VERSION ""

NS_ :

BS_:

BU_: GPSReceiver TractorECU Implement

BO_ 2628452094 CFS: 9 Vector__XXX
 SG_ VI_VolumeName m64 : 56|16@1+ (1,0) [0|65535] "" Vector__XXX
 SG_ VI_Flag_OverwriteExisting m64 : 48|1@1+ (1,0) [0|1] "" Vector__XXX
 SG_ MF_DestinationPathNameLength m48 : 40|16@1+ (1,0) [0|65535] "" Vector__XXX
 SG_ RF_ReportHiddenFiles m34 : 40|8@1+ (1,0) [0|255] "" Vector__XXX
 SG_ SF_Offset m33 : 32|32@1- (1,0) [-2147483648|2147483647] "" Vector__XXX
 SG_ RF_Count m34 : 24|16@1+ (1,0) [0|65535] "" Vector__XXX
 SG_ SF_PositionMode m33 : 24|8@1+ (1,0) [0|255] "" Vector__XXX
 SG_ OF_PathName m32 : 24|16@1+ (1,0) [0|65535] "" Vector__XXX
 SG_ MF_SourcePathNameLength m48 : 24|16@1+ (1,0) [0|65535] "" Vector__XXX
 SG_ WF_Count m35 : 24|16@1+ (1,0) [0|65535] "" Vector__XXX
 SG_ DF_PathName m49 : 24|16@1+ (1,0) [0|65535] "" Vector__XXX
 SG_ SA_PathName m51 : 24|16@1+ (1,0) [0|65535] "" Vector__XXX
 SG_ VI_Space m64 : 16|32@1+ (1,0) [0|4294967295] "" Vector__XXX
 SG_ OF_FlagExclusiveAccess m32 : 20|1@1+ (1,0) [0|1] "" Vector__XXX
 SG_ OF_FlagAppend m32 : 19|1@1+ (1,0) [0|1] "" Vector__XXX
 SG_ SA_ATTR_Hidden m51 : 18|2@1+ (1,0) [0|3] "" Vector__XXX
 SG_ OF_FlagCreateNew m32 : 18|1@1+ (1,0) [0|1] "" Vector__XXX
 SG_ MF_MoveModeRecursive m48 : 18|1@1+ (1,0) [0|1] "" Vector__XXX
 SG_ DF_DeleteModeRecursive m49 : 18|1@1+ (1,0) [0|1] "" Vector__XXX
 SG_ MF_MoveModeForce m48 : 17|1@1+ (1,0) [0|1] "" Vector__XXX
 SG_ DF_DeleteModeForce m49 : 17|1@1+ (1,0) [0|1] "" Vector__XXX
 SG_ VI_Flag_UsingSpaceSpecified m64 : 49|1@1+ (1,0) [0|1] "" Vector__XXX
 SG_ SA_ATTR_ReadOnly m51 : 16|2@1+ (1,0) [0|3] "" Vector__XXX
 SG_ CF_Handle m36 : 16|8@1+ (1,0) [0|255] "" Vector__XXX
 SG_ WF_Handle m35 : 16|8@1+ (1,0) [0|255] "" Vector__XXX
 SG_ RF_Handle m34 : 16|8@1+ (1,0) [0|255] "" Vector__XXX
 SG_ SF_Handle m33 : 16|8@1+ (1,0) [0|255] "" Vector__XXX
 SG_ OF_FlagReadWrite m32 : 16|2@1+ (1,0) [0|3] "" Vector__XXX
 SG_ CCD_PathName m17 : 16|16@1+ (1,0) [0|65535] "" Vector__XXX
 SG_ MF_MoveModeCopy m48 : 16|1@1+ (1,0) [0|1] "" Vector__XXX
 SG_ DF_DeleteMode m49 : 16|1@1+ (1,0) [0|1] "" Vector__XXX
 SG_ GA_PathName m50 : 16|16@1+ (1,0) [0|65535] "" Vector__XXX
 SG_ FDT_PathName m52 : 16|16@1+ (1,0) [0|65535] "" Vector__XXX
 SG_ VS_VolumeName m2 : 16|16@1+ (1,0) [0|0] "" Vector__XXX
 SG_ VS_RequestVolumeToPrepareForRemo m2 : 9|1@1- (1,0) [0|1] "" Vector__XXX
 SG_ CCD_TAN m17 : 8|8@1+ (1,0) [0|255] "" Vector__XXX
 SG_ GCD_TAN m16 : 8|8@1+ (1,0) [0|255] "" Vector__XXX
 SG_ FDT_TAN m52 : 8|8@1+ (1,0) [0|255] "" Vector__XXX
 SG_ SA_TAN m51 : 8|8@1+ (1,0) [0|255] "" Vector__XXX
 SG_ GA_TAN m50 : 8|8@1+ (1,0) [0|255] "" Vector__XXX
 SG_ RF_TAN m34 : 8|8@1+ (1,0) [0|255] "" Vector__XXX
 SG_ CF_TAN m36 : 8|8@1+ (1,0) [0|255] "" Vector__XXX
 SG_ WF_TAN m35 : 8|8@1+ (1,0) [0|255] "" Vector__XXX
 SG_ SF_TAN m33 : 8|8@1+ (1,0) [0|255] "" Vector__XXX
 SG_ OF_TAN m32 : 8|8@1+ (1,0) [0|255] "" Vector__XXX
 SG_ MF_TAN m48 : 8|8@1+ (1,0) [0|255] "" Vector__XXX
 SG_ DF_TAN m49 : 8|8@1+ (1,0) [0|255] "" Vector__XXX
 SG_ VI_TAN m64 : 8|8@1+ (1,0) [0|255] "" Vector__XXX
 SG_ VS_ReportVolumeUsedByClient m2 : 8|1@1+ (1,0) [0|1] "" Vector__XXX
 SG_ CM_VersionNumber m0 : 8|8@1+ (1,0) [0|255] "" Vector__XXX
 SG_ FSClientCommand M : 0|8@1+ (1,0) [0|255] "" Vector__XXX

BO_ 2628517630 FSC: 35 Vector__XXX
 SG_ OF_ATTR_VolumeSupportsHidden m32 : 34|1@1+ (1,0) [0|1] "" Vector__XXX
 SG_ GCD_PathName m16 : 88|16@1+ (1,0) [0|65535] "" Vector__XXX
 SG_ GCD_FreeSpace m16 : 56|32@1+ (512,0) [0|4294966744] "Bytes" Vector__XXX
 SG_ FDT_TimeHour m52 : 51|5@1+ (1,0) [0|23] "Hour" Vector__XXX
 SG_ FDT_TimeMinutes m52 : 45|6@1+ (1,0) [0|59] "Minutes" Vector__XXX
 SG_ FDT_TimeSeconds m52 : 40|5@1+ (2,0) [0|58] "Seconds" Vector__XXX
 SG_ OF_ATTR_VolumeIsCaseSensitive m32 : 39|1@1+ (1,0) [0|1] "" Vector__XXX
 SG_ OF_ATTR_VolumeIsRemovable m32 : 38|1@1+ (1,0) [0|1] "" Vector__XXX
 SG_ OF_ATTR_SupportsLongFilenames m32 : 37|1@1+ (1,0) [0|1] "" Vector__XXX
 SG_ OF_ATTR_IsDirectory m32 : 36|1@1+ (1,0) [0|1] "" Vector__XXX
 SG_ OF_ATTR_IsVolume m32 : 35|1@1+ (1,0) [0|1] "" Vector__XXX
 SG_ FDT_DateYear m52 : 33|7@1+ (1,1980) [1980|2107] "Year" Vector__XXX
 SG_ OF_ATTR_Hidden m32 : 33|1@1+ (1,0) [0|1] "" Vector__XXX
 SG_ SF_Position m33 : 32|32@1+ (1,0) [0|4294967295] "" Vector__XXX
 SG_ OF_ATTR_ReadOnly m32 : 32|1@1+ (1,0) [0|1] "" Vector__XXX
 SG_ GA_Size m50 : 32|32@1+ (1,0) [0|4294967295] "" Vector__XXX
 SG_ VS_VolumeName m2 : 32|16@1+ (1,0) [0|65535] "" Vector__XXX
 SG_ VI_VolumeIsCaseSensitive m64 : 31|1@1+ (1,0) [0|1] "" Vector__XXX
 SG_ GA_ATTR_VolumeIsCaseSensitive m50 : 31|1@1+ (1,0) [0|1] "" Vector__XXX
 SG_ VI_ATTR_VolumeRemovable m64 : 30|1@1+ (1,0) [0|1] "" Vector__XXX
 SG_ GA_ATTR_VolumeIsRemovable m50 : 30|1@1+ (1,0) [0|1] "" Vector__XXX
 SG_ VI_ATTR_SupportsLongFilenames m64 : 29|1@1+ (1,0) [0|1] "" Vector__XXX
 SG_ FDT_DateMonth m52 : 29|4@1+ (1,0) [0|12] "Month" Vector__XXX
 SG_ GA_ATTR_SupportsLongFilenames m50 : 29|1@1+ (1,0) [0|1] "" Vector__XXX
 SG_ GA_ATTR_IsDirectory m50 : 28|1@1+ (1,0) [0|1] "" Vector__XXX
 SG_ VI_ATTR_IsDirectory m64 : 28|1@1+ (1,0) [0|1] "" Vector__XXX
 SG_ VI_ATTR_IsVolume m64 : 27|1@1+ (1,0) [0|1] "" Vector__XXX
 SG_ GA_ATTR_IsVolume m50 : 27|1@1+ (1,0) [0|1] "" Vector__XXX
 SG_ VI_ATTR_VolumeSupportsHidden m64 : 26|1@1+ (1,0) [0|1] "" Vector__XXX
 SG_ GA_ATTR_VolumeSupportsHidden m50 : 26|1@1+ (1,0) [0|1] "" Vector__XXX
 SG_ VI_ATTR_Hidden m64 : 25|1@1+ (1,0) [0|1] "" Vector__XXX
 SG_ GA_ATTR_Hidden m50 : 25|1@1+ (1,0) [0|1] "" Vector__XXX
 SG_ VI_ATTR_ReadOnly m64 : 24|1@1+ (1,0) [0|1] "" Vector__XXX
 SG_ FDT_DateDay m52 : 24|5@1+ (1,0) [0|31] "Day" Vector__XXX
 SG_ GA_ATTR_ReadOnly m50 : 24|1@1+ (1,0) [0|1] "" Vector__XXX
 SG_ OF_Handle m32 : 24|8@1+ (1,0) [0|255] "" Vector__XXX
 SG_ GCD_TotalSpace m16 : 24|32@1+ (512,0) [0|4294966744] "Bytes" Vector__XXX
 SG_ RF_Count m34 : 24|16@1+ (1,0) [0|65535] "Bytes" Vector__XXX
 SG_ GSP_SupportMultipleVolumes m1 : 24|1@1+ (1,0) [0|255] "" Vector__XXX
 SG_ WF_Count m35 : 24|16@1+ (1,0) [0|65535] "" Vector__XXX
 SG_ VS_ErrorCode m2 : 24|8@1+ (1,0) [0|255] "" Vector__XXX
 SG_ FDT_ErrorCode m52 : 16|8@1+ (1,0) [0|255] "" Vector__XXX
 SG_ RF_ErrorCode m34 : 16|8@1+ (1,0) [0|255] "" Vector__XXX
 SG_ SF_ErrorCode m33 : 16|8@1+ (1,0) [0|255] "" Vector__XXX
 SG_ FSNumberOfOpenFiles m0 : 16|8@1- (1,0) [0|255] "" Vector__XXX
 SG_ OF_ErrorCode m32 : 16|8@1+ (1,0) [0|255] "" Vector__XXX
 SG_ WF_ErrorCode m35 : 16|8@1+ (1,0) [0|255] "" Vector__XXX
 SG_ CF_ErrorCode m36 : 16|8@1+ (1,0) [0|255] "" Vector__XXX
 SG_ MF_ErrorCode m48 : 16|8@1+ (1,0) [0|255] "" Vector__XXX
 SG_ GA_ErrorCode m50 : 16|8@1+ (1,0) [0|255] "" Vector__XXX
 SG_ SA_ErrorCode m51 : 16|8@1+ (1,0) [0|255] "" Vector__XXX
 SG_ GCD_ErrorCode m16 : 16|8@1+ (1,0) [0|255] "" Vector__XXX
 SG_ CCD_ErrorCode m17 : 16|8@1+ (1,0) [0|255] "" Vector__XXX
 SG_ GSP_MaxNrSimultaneousFilesOpen m1 : 16|8@1+ (1,0) [0|255] "" Vector__XXX
 SG_ DF_ErrorCode m49 : 16|8@1+ (1,0) [0|255] "" Vector__XXX
 SG_ VI_ErrorCode m64 : 16|8@1+ (1,0) [0|255] "" Vector__XXX
 SG_ VS_MaxTimeBeforeVolRemoval m2 : 16|8@1+ (1,0) [0|250] "min/bit" Vector__XXX
 SG_ FSBusyWriting m0 : 9|1@1+ (1,0) [0|1] "" Vector__XXX
 SG_ FSBusyReading m0 : 8|1@1+ (1,0) [0|1] "" Vector__XXX
 SG_ OF_TAN m32 : 8|8@1+ (1,0) [0|255] "" Vector__XXX
 SG_ SF_TAN m33 : 8|8@1+ (1,0) [0|255] "" Vector__XXX
 SG_ RF_TAN m34 : 8|8@1+ (1,0) [0|255] "" Vector__XXX
 SG_ WF_TAN m35 : 8|8@1+ (1,0) [0|255] "" Vector__XXX
 SG_ CF_TAN m36 : 8|8@1+ (1,0) [0|255] "" Vector__XXX
 SG_ MF_TAN m48 : 8|8@1+ (1,0) [0|255] "" Vector__XXX
 SG_ GA_TAN m50 : 8|8@1+ (1,0) [0|255] "" Vector__XXX
 SG_ SA_TAN m51 : 8|8@1+ (1,0) [0|255] "" Vector__XXX
 SG_ FDT_TAN m52 : 8|8@1+ (1,0) [0|255] "" Vector__XXX
 SG_ GCD_TAN m16 : 8|8@1+ (1,0) [0|255] "" Vector__XXX
 SG_ CCD_TAN m17 : 8|8@1+ (1,0) [0|255] "" Vector__XXX
 SG_ GSP_VersionNumber m1 : 8|8@1+ (1,0) [0|255] "" Vector__XXX
 SG_ DF_TAN m49 : 8|8@1+ (1,0) [0|255] "" Vector__XXX
 SG_ VI_TAN m64 : 8|8@1+ (1,0) [0|255] "" Vector__XXX
 SG_ VS_VolumeStatus m2 : 8|8@1+ (1,0) [0|3] "" Vector__XXX
 SG_ FSServerCommand M : 0|8@1+ (1,0) [0|255] "" Vector__XXX

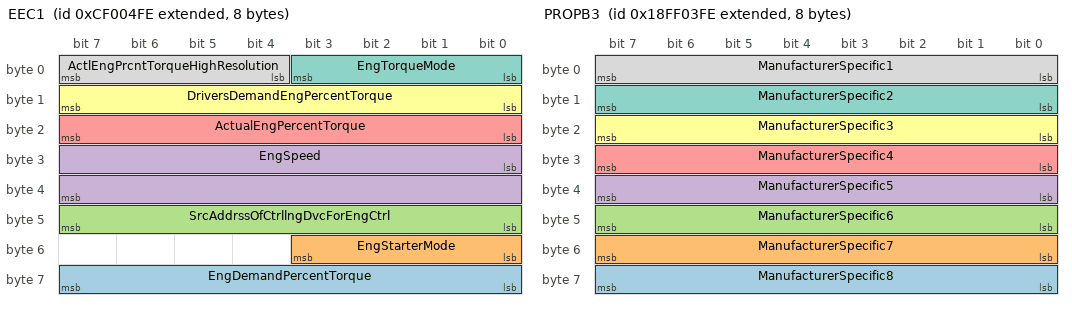
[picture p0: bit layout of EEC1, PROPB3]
BO_ 2364540158 EEC1: 8 Vector__XXX
 SG_ EngDemandPercentTorque : 56|8@1+ (1,-125) [-125|125] "%" Vector__XXX
 SG_ EngStarterMode : 48|4@1+ (1,0) [0|15] "" Vector__XXX
 SG_ SrcAddrssOfCtrllngDvcForEngCtrl : 40|8@1+ (1,0) [0|255] "" Vector__XXX
 SG_ EngSpeed : 24|16@1+ (0.125,0) [0|8031.875] "rpm" Vector__XXX
 SG_ ActualEngPercentTorque : 16|8@1+ (1,-125) [-125|125] "%" Vector__XXX
 SG_ DriversDemandEngPercentTorque : 8|8@1+ (1,-125) [-125|125] "%" Vector__XXX
 SG_ EngTorqueMode : 0|4@1+ (1,0) [0|15] "" Vector__XXX
 SG_ ActlEngPrcntTorqueHighResolution : 4|4@1+ (0.125,0) [0|0.875] "%" Vector__XXX

BO_ 2563243774 ETP_DT: 8 Vector__XXX
 SG_ Byte7 : 56|8@1+ (1,0) [0|255] "" Vector__XXX
 SG_ Byte6 : 48|8@1+ (1,0) [0|255] "" Vector__XXX
 SG_ Byte5 : 40|8@1+ (1,0) [0|255] "" Vector__XXX
 SG_ Byte4 : 32|8@1+ (1,0) [0|255] "" Vector__XXX
 SG_ Byte3 : 24|8@1+ (1,0) [0|255] "" Vector__XXX
 SG_ Byte2 : 16|8@1+ (1,0) [0|255] "" Vector__XXX
 SG_ Byte1 : 8|8@1+ (1,0) [0|255] "" Vector__XXX
 SG_ SequenceNumber : 0|8@1+ (1,0) [1|255] "" Vector__XXX

BO_ 2563309310 ETP_CM: 8 Vector__XXX
 SG_ PGNumber : 40|24@1+ (1,0) [0|16777200] "" Vector__XXX
 SG_ DataPacketOffset m22 : 16|24@1+ (1,0) [0|16777215] "" Vector__XXX
 SG_ NextPacketNumberToSend m21 : 16|24@1+ (1,0) [1|16777215] "" Vector__XXX
 SG_ NumberOfBytesTransfered m23 : 8|32@1+ (1,0) [1786|117440505] "" Vector__XXX
 SG_ NumberOfPacketsOffset m22 : 8|8@1+ (1,0) [1|255] "" Vector__XXX
 SG_ NumberOfPacketsToSend m21 : 8|8@1+ (1,0) [1|255] "" Vector__XXX
 SG_ NumberOfBytesToTransfer m20 : 8|32@1+ (1,0) [1786|117440505] "" Vector__XXX
 SG_ ControlByte M : 0|8@1+ (1,0) [0|255] "" Vector__XXX
 SG_ ConnectionAbortReason m255 : 8|8@1+ (1,0) [0|255] "" Vector__XXX

BO_ 2314732030 GNSSPositionRapidUpdate: 8 Vector__XXX
 SG_ Longitude : 32|32@1- (1E-007,0) [-180|180] "deg" Vector__XXX
 SG_ Latitude : 0|32@1- (1E-007,0) [-90|90] "deg" Vector__XXX

BO_ 2583168510 GNSSPositionData: 47 Vector__XXX
 SG_ AgeOfDGNSSCorrections1 : 360|16@1+ (0.01,0) [0|655.32] "sec" Vector__XXX
 SG_ ReferenceStationID1 : 348|12@1+ (1,0) [0|4095] "" Vector__XXX
 SG_ RefrenceStationType1 : 344|4@1+ (1,0) [0|15] "" Vector__XXX
 SG_ NumberOfReferenceStations : 336|8@1+ (1,0) [0|252] "" Vector__XXX
 SG_ GeoidalSeparation : 304|32@1- (0.01,0) [-21470000|21470000] "m" Vector__XXX
 SG_ PDOP : 288|16@1- (0.01,0) [-327.64|327.64] "" Vector__XXX
 SG_ HDOP : 272|16@1- (0.01,0) [-327.64|327.64] "" Vector__XXX
 SG_ NumberOfSVs : 264|8@1+ (1,0) [0|252] "" Vector__XXX
 SG_ GNSSIntegrity : 256|2@1+ (1,0) [0|3] "" Vector__XXX
 SG_ GNSSMethod : 252|4@1+ (1,0) [0|15] "" Vector__XXX
 SG_ TypeOfSystem : 248|4@1+ (1,0) [0|4] "" Vector__XXX
 SG_ Altitude : 184|64@1- (1E-006,0) [-9223372036854.78|9223372036854.78] "m" Vector__XXX
 SG_ Longitude : 120|64@1- (1E-016,0) [-180|180] "deg" Vector__XXX
 SG_ Latitude : 56|64@1- (1E-016,0) [-90|90] "deg" Vector__XXX
 SG_ PositionTime : 24|32@1+ (0.0001,0) [0|86401] "s" Vector__XXX
 SG_ PositionDate : 8|16@1+ (1,0) [0|65532] "day" Vector__XXX
 SG_ SequenceID : 0|8@1+ (1,0) [0|255] "" Vector__XXX

BO_ 2583299838 GNSSPseudoRangeNoiseStatistic: 15 Vector__XXX
 SG_ STDofAltError : 104|16@1+ (0.01,0) [0|655.32] "m" Vector__XXX
 SG_ STDofLonError : 88|16@1+ (0.01,0) [0|655.32] "m" Vector__XXX
 SG_ STDofLatError : 72|16@1+ (0.01,0) [0|655.32] "m" Vector__XXX
 SG_ OrientationOfMinorAxis : 56|16@1+ (0.0001,0) [0|6.2832] "rad" Vector__XXX
 SG_ STDofMinorAxis : 40|16@1+ (0.01,0) [0|655.32] "m" Vector__XXX
 SG_ STDofMajorAxis : 24|16@1+ (0.01,0) [0|655.32] "m" Vector__XXX
 SG_ RMSofPositionUncertainty : 8|16@1+ (0.01,0) [0|655.32] "m" Vector__XXX
 SG_ SequenceID : 0|8@1+ (1,0) [0|255] "" Vector__XXX

BO_ 2566849534 PROPB3: 8 Vector__XXX
 SG_ ManufacturerSpecific8 : 56|8@1+ (1,0) [0|255] "" Vector__XXX
 SG_ ManufacturerSpecific7 : 48|8@1+ (1,0) [0|255] "" Vector__XXX
 SG_ ManufacturerSpecific6 : 40|8@1+ (1,0) [0|255] "" Vector__XXX
 SG_ ManufacturerSpecific5 : 32|8@1+ (1,0) [0|255] "" Vector__XXX
 SG_ ManufacturerSpecific4 : 24|8@1+ (1,0) [0|255] "" Vector__XXX
 SG_ ManufacturerSpecific3 : 16|8@1+ (1,0) [0|255] "" Vector__XXX
 SG_ ManufacturerSpecific2 : 8|8@1+ (1,0) [0|255] "" Vector__XXX
 SG_ ManufacturerSpecific1 : 0|8@1+ (1,0) [0|255] "" Vector__XXX

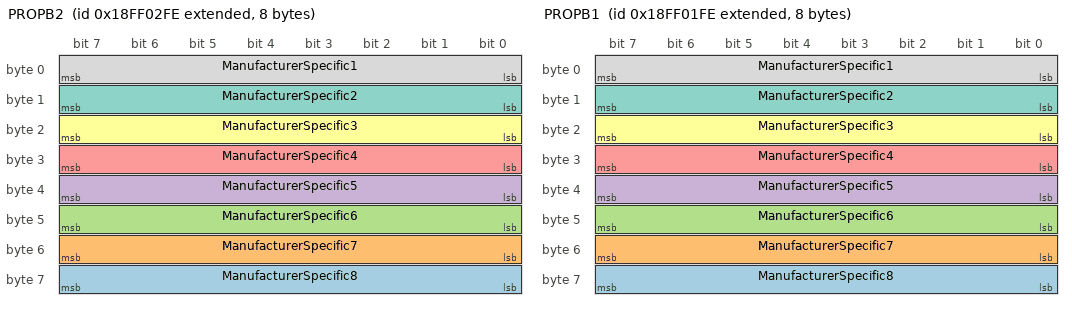
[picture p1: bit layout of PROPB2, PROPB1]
BO_ 2566849278 PROPB2: 8 Vector__XXX
 SG_ ManufacturerSpecific8 : 56|8@1+ (1,0) [0|255] "" Vector__XXX
 SG_ ManufacturerSpecific7 : 48|8@1+ (1,0) [0|255] "" Vector__XXX
 SG_ ManufacturerSpecific6 : 40|8@1+ (1,0) [0|255] "" Vector__XXX
 SG_ ManufacturerSpecific5 : 32|8@1+ (1,0) [0|255] "" Vector__XXX
 SG_ ManufacturerSpecific4 : 24|8@1+ (1,0) [0|255] "" Vector__XXX
 SG_ ManufacturerSpecific3 : 16|8@1+ (1,0) [0|255] "" Vector__XXX
 SG_ ManufacturerSpecific2 : 8|8@1+ (1,0) [0|255] "" Vector__XXX
 SG_ ManufacturerSpecific1 : 0|8@1+ (1,0) [0|255] "" Vector__XXX

BO_ 2566849022 PROPB1: 8 Vector__XXX
 SG_ ManufacturerSpecific8 : 56|8@1+ (1,0) [0|255] "" Vector__XXX
 SG_ ManufacturerSpecific7 : 48|8@1+ (1,0) [0|255] "" Vector__XXX
 SG_ ManufacturerSpecific6 : 40|8@1+ (1,0) [0|255] "" Vector__XXX
 SG_ ManufacturerSpecific5 : 32|8@1+ (1,0) [0|255] "" Vector__XXX
 SG_ ManufacturerSpecific4 : 24|8@1+ (1,0) [0|255] "" Vector__XXX
 SG_ ManufacturerSpecific3 : 16|8@1+ (1,0) [0|255] "" Vector__XXX
 SG_ ManufacturerSpecific2 : 8|8@1+ (1,0) [0|255] "" Vector__XXX
 SG_ ManufacturerSpecific1 : 0|8@1+ (1,0) [0|255] "" Vector__XXX

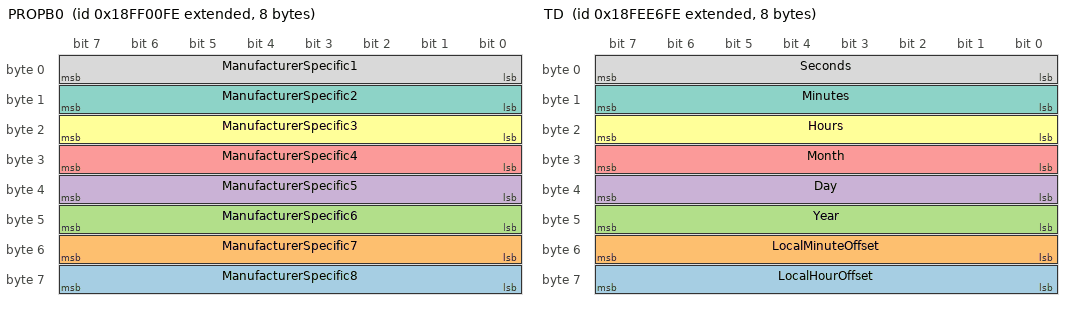
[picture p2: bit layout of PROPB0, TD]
BO_ 2566848766 PROPB0: 8 Vector__XXX
 SG_ ManufacturerSpecific8 : 56|8@1+ (1,0) [0|255] "" Vector__XXX
 SG_ ManufacturerSpecific7 : 48|8@1+ (1,0) [0|255] "" Vector__XXX
 SG_ ManufacturerSpecific6 : 40|8@1+ (1,0) [0|255] "" Vector__XXX
 SG_ ManufacturerSpecific5 : 32|8@1+ (1,0) [0|255] "" Vector__XXX
 SG_ ManufacturerSpecific4 : 24|8@1+ (1,0) [0|255] "" Vector__XXX
 SG_ ManufacturerSpecific3 : 16|8@1+ (1,0) [0|255] "" Vector__XXX
 SG_ ManufacturerSpecific2 : 8|8@1+ (1,0) [0|255] "" Vector__XXX
 SG_ ManufacturerSpecific1 : 0|8@1+ (1,0) [0|255] "" Vector__XXX

BO_ 2566842110 TD: 8 Vector__XXX
 SG_ LocalHourOffset : 56|8@1+ (1,-125) [-125|125] "hr" Vector__XXX
 SG_ LocalMinuteOffset : 48|8@1+ (1,-125) [-125|125] "mins" Vector__XXX
 SG_ Year : 40|8@1+ (1,1985) [1985|2235] "years" Vector__XXX
 SG_ Day : 32|8@1+ (0.25,0) [0|62.5] "days" Vector__XXX
 SG_ Month : 24|8@1+ (1,0) [0|250] "months" Vector__XXX
 SG_ Hours : 16|8@1+ (1,0) [0|250] "hr" Vector__XXX
 SG_ Minutes : 8|8@1+ (1,0) [0|250] "mins" Vector__XXX
 SG_ Seconds : 0|8@1+ (0.25,0) [0|62.5] "s" Vector__XXX

BO_ 2365475326 GBSD: 8 Vector__XXX
 SG_ GroundBasedMachineDirection : 56|2@1+ (1,0) [0|3] "" Vector__XXX
 SG_ GroundBasedMachineDistance : 16|32@1+ (0.001,0) [0|4211080] "m" Vector__XXX
 SG_ GroundBasedMachineSpeed : 0|16@1+ (0.001,0) [0|64.255] "m/s" Vector__XXX

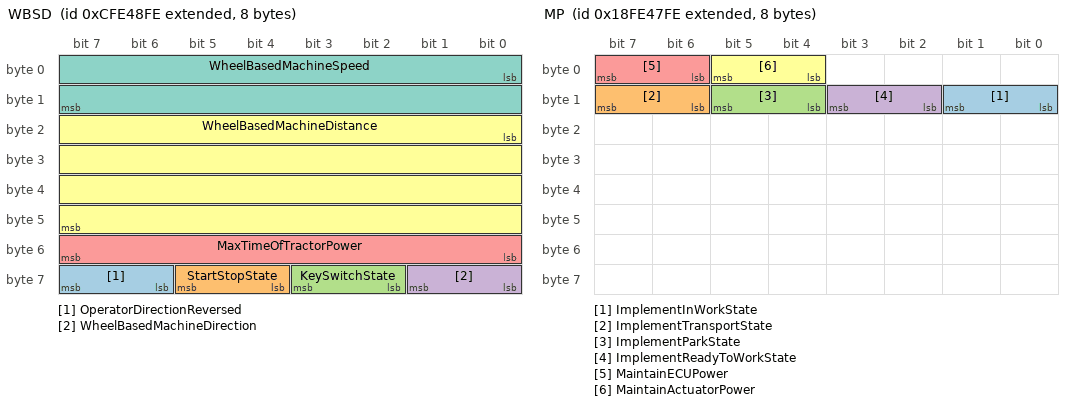
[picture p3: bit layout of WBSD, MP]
BO_ 2365475070 WBSD: 8 Vector__XXX
 SG_ OperatorDirectionReversed : 62|2@1+ (1,0) [0|3] "" Vector__XXX
 SG_ StartStopState : 60|2@1+ (1,0) [0|4] "" Vector__XXX
 SG_ KeySwitchState : 58|2@1+ (1,0) [0|3] "" Vector__XXX
 SG_ WheelBasedMachineDirection : 56|2@1+ (1,0) [0|3] "" Vector__XXX
 SG_ MaxTimeOfTractorPower : 48|8@1+ (1,0) [0|250] "min" Vector__XXX
 SG_ WheelBasedMachineDistance : 16|32@1+ (0.001,0) [0|4211081.215] "m" Vector__XXX
 SG_ WheelBasedMachineSpeed : 0|16@1+ (0.001,0) [0|64.255] "m/s" Vector__XXX

BO_ 2566801406 MP: 8 Vector__XXX
 SG_ ImplementInWorkState : 8|2@1+ (1,0) [0|0] "" Vector__XXX
 SG_ ImplementTransportState : 14|2@1+ (1,0) [0|3] "" Vector__XXX
 SG_ ImplementParkState : 12|2@1+ (1,0) [0|3] "" Vector__XXX
 SG_ ImplementReadyToWorkState : 10|2@1+ (1,0) [0|3] "" Vector__XXX
 SG_ MaintainECUPower : 6|2@1+ (1,0) [0|0] "" Vector__XXX
 SG_ MaintainActuatorPower : 4|2@1+ (1,0) [0|3] "" Vector__XXX

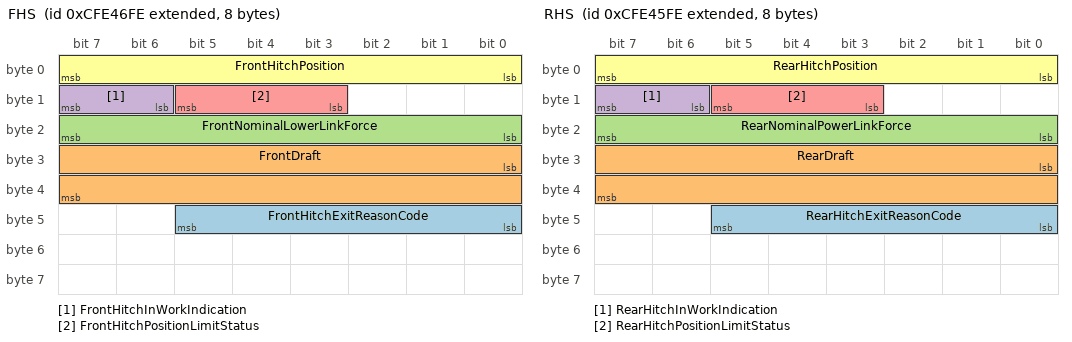
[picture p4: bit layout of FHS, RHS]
BO_ 2365474558 FHS: 8 Vector__XXX
 SG_ FrontHitchExitReasonCode : 40|6@1+ (1,0) [0|63] "" Vector__XXX
 SG_ FrontDraft : 24|16@1+ (10,-320000) [-320000|322550] "N" Vector__XXX
 SG_ FrontNominalLowerLinkForce : 16|8@1+ (0.8,-100) [-100|100] "%" Vector__XXX
 SG_ FrontHitchInWorkIndication : 14|2@1+ (1,0) [0|3] "" Vector__XXX
 SG_ FrontHitchPositionLimitStatus : 11|3@1+ (1,0) [0|7] "" Vector__XXX
 SG_ FrontHitchPosition : 0|8@1+ (0.4,0) [0|100] "%" Vector__XXX

BO_ 2365474302 RHS: 8 Vector__XXX
 SG_ RearHitchExitReasonCode : 40|6@1+ (1,0) [0|63] "" Vector__XXX
 SG_ RearDraft : 24|16@1+ (10,-320000) [-320000|322550] "N" Vector__XXX
 SG_ RearNominalPowerLinkForce : 16|8@1+ (0.8,-100) [-100|100] "%" Vector__XXX
 SG_ RearHitchInWorkIndication : 14|2@1+ (1,0) [0|3] "" Vector__XXX
 SG_ RearHitchPositionLimitStatus : 11|3@1+ (1,0) [0|7] "" Vector__XXX
 SG_ RearHitchPosition : 0|8@1+ (0.4,0) [0|100] "%" Vector__XXX

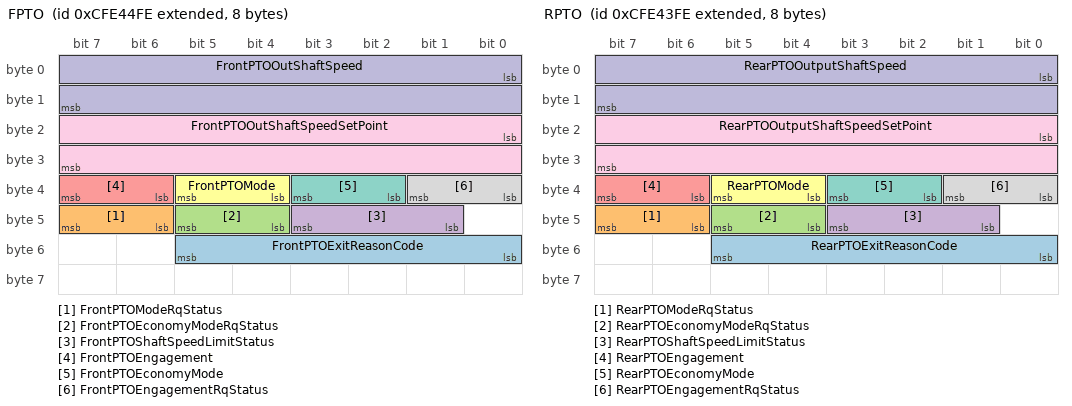
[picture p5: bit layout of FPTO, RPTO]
BO_ 2365474046 FPTO: 8 Vector__XXX
 SG_ FrontPTOExitReasonCode : 48|6@1+ (1,0) [0|63] "" Vector__XXX
 SG_ FrontPTOModeRqStatus : 46|2@1+ (1,0) [0|3] "" Vector__XXX
 SG_ FrontPTOEconomyModeRqStatus : 44|2@1+ (1,0) [0|3] "" Vector__XXX
 SG_ FrontPTOShaftSpeedLimitStatus : 41|3@1+ (1,0) [0|7] "" Vector__XXX
 SG_ FrontPTOEngagement : 38|2@1+ (1,0) [0|3] "" Vector__XXX
 SG_ FrontPTOMode : 36|2@1+ (1,0) [0|3] "" Vector__XXX
 SG_ FrontPTOEconomyMode : 34|2@1+ (1,0) [0|3] "" Vector__XXX
 SG_ FrontPTOEngagementRqStatus : 32|2@1+ (1,0) [0|3] "" Vector__XXX
 SG_ FrontPTOOutShaftSpeedSetPoint : 16|16@1+ (0.125,0) [0|8031.88] "1/min" Vector__XXX
 SG_ FrontPTOOutShaftSpeed : 0|16@1+ (0.125,0) [0|8031.88] "1/min" Vector__XXX

BO_ 2365473790 RPTO: 8 Vector__XXX
 SG_ RearPTOExitReasonCode : 48|6@1+ (1,0) [0|63] "" Vector__XXX
 SG_ RearPTOModeRqStatus : 46|2@1+ (1,0) [0|3] "" Vector__XXX
 SG_ RearPTOEconomyModeRqStatus : 44|2@1+ (1,0) [0|3] "" Vector__XXX
 SG_ RearPTOShaftSpeedLimitStatus : 41|3@1+ (1,0) [0|7] "" Vector__XXX
 SG_ RearPTOEngagement : 38|2@1+ (1,0) [0|3] "" Vector__XXX
 SG_ RearPTOMode : 36|2@1+ (1,0) [0|3] "" Vector__XXX
 SG_ RearPTOEconomyMode : 34|2@1+ (1,0) [0|3] "" Vector__XXX
 SG_ RearPTOEngagementRqStatus : 32|2@1+ (1,0) [0|3] "" Vector__XXX
 SG_ RearPTOOutputShaftSpeedSetPoint : 16|16@1+ (0.125,0) [0|8031.88] "1/min" Vector__XXX
 SG_ RearPTOOutputShaftSpeed : 0|16@1+ (0.125,0) [0|8031.88] "1/min" Vector__XXX

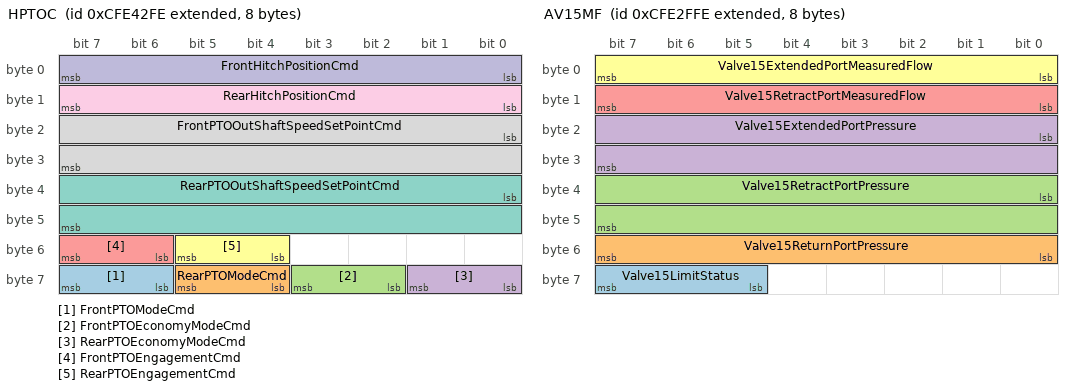
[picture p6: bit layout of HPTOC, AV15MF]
BO_ 2365473534 HPTOC: 8 Vector__XXX
 SG_ FrontPTOModeCmd : 62|2@1+ (1,0) [0|3] "" Vector__XXX
 SG_ RearPTOModeCmd : 60|2@1+ (1,0) [0|3] "" Vector__XXX
 SG_ FrontPTOEconomyModeCmd : 58|2@1+ (1,0) [0|3] "" Vector__XXX
 SG_ RearPTOEconomyModeCmd : 56|2@1+ (1,0) [0|3] "" Vector__XXX
 SG_ FrontPTOEngagementCmd : 54|2@1+ (1,0) [0|3] "" Vector__XXX
 SG_ RearPTOEngagementCmd : 52|2@1+ (1,0) [0|3] "" Vector__XXX
 SG_ RearPTOOutShaftSpeedSetPointCmd : 32|16@1+ (0.125,0) [0|801.875] "1/min" Vector__XXX
 SG_ FrontPTOOutShaftSpeedSetPointCmd : 16|16@1+ (0.125,0) [0|8031.875] "1/min" Vector__XXX
 SG_ RearHitchPositionCmd : 8|8@1+ (0.4,0) [0|100] "%" Vector__XXX
 SG_ FrontHitchPositionCmd : 0|8@1+ (0.4,0) [0|100] "%" Vector__XXX

BO_ 2365473278 LCMD: 8 Vector__XXX
 SG_ ImplementRearWorkLightCmd : 62|2@1+ (1,0) [0|3] "" Vector__XXX
 SG_ ImplementLeftFacingWorkLightCmd : 60|2@1+ (1,0) [0|3] "" Vector__XXX
 SG_ ImplementRightFacingWorkLightCmd : 58|2@1+ (1,0) [0|3] "" Vector__XXX
 SG_ LightingDataRequestCmd : 56|2@1+ (1,0) [0|3] "" Vector__XXX
 SG_ ImplementLeftForwardLightCmd : 54|2@1+ (1,0) [0|3] "" Vector__XXX
 SG_ ImplementRightForwardLightCmd : 52|2@1+ (1,0) [0|3] "" Vector__XXX
 SG_ ImplementOEMOption1LightCmd : 50|2@1+ (1,0) [0|3] "" Vector__XXX
 SG_ ImplementOEMOption2LightCmd : 48|2@1+ (1,0) [0|3] "" Vector__XXX
 SG_ TractorFrontHighWorkLightCmd : 46|2@1+ (1,0) [0|3] "" Vector__XXX
 SG_ TractorFrontLowWorkLightCmd : 44|2@1+ (1,0) [0|3] "" Vector__XXX
 SG_ TractorSideHighWorkLightCmd : 42|2@1+ (1,0) [0|3] "" Vector__XXX
 SG_ TractorSideLowWorkLightCmd : 40|2@1+ (1,0) [0|3] "" Vector__XXX
 SG_ TractorRearHighWorkLightCmd : 38|2@1+ (1,0) [0|3] "" Vector__XXX
 SG_ TractorRearLowWorkLightCmd : 36|2@1+ (1,0) [0|3] "" Vector__XXX
 SG_ TractorUndersideWorkLightCmd : 34|2@1+ (1,0) [0|3] "" Vector__XXX
 SG_ RearFogLightCmd : 32|2@1+ (1,0) [0|3] "" Vector__XXX
 SG_ TractorMarkerLightCmd : 30|2@1+ (1,0) [0|3] "" Vector__XXX
 SG_ ImplementMarkerLightCmd : 28|2@1+ (1,0) [0|3] "" Vector__XXX
 SG_ TractorClearanceLightCmd : 26|2@1+ (1,0) [0|3] "" Vector__XXX
 SG_ ImplementClearanceLightCmd : 24|2@1+ (1,0) [0|3] "" Vector__XXX
 SG_ LeftStopLightCmd : 22|2@1+ (1,0) [0|3] "" Vector__XXX
 SG_ RightStopLightCmd : 20|2@1+ (1,0) [0|3] "" Vector__XXX
 SG_ CentreStopLightCmd : 18|2@1+ (1,0) [0|3] "" Vector__XXX
 SG_ BackUpLightAndAlarmHornCmd : 16|2@1+ (1,0) [0|3] "" Vector__XXX
 SG_ LeftTurnSignalLightCmd : 14|2@1+ (1,0) [0|3] "" Vector__XXX
 SG_ RightTurnSignalLightCmd : 12|2@1+ (1,0) [0|3] "" Vector__XXX
 SG_ RotatingBeaconLightCmd : 10|2@1+ (1,0) [0|3] "" Vector__XXX
 SG_ TractorFrontFogLightCmd : 8|2@1+ (1,0) [0|3] "" Vector__XXX
 SG_ HighBeamHeadLightCmd : 6|2@1+ (1,0) [0|3] "" Vector__XXX
 SG_ LowBeamHeadLightCmd : 4|2@1+ (1,0) [0|3] "" Vector__XXX
 SG_ AlternateHeadLightCmd : 2|2@1+ (1,0) [0|3] "" Vector__XXX
 SG_ DaytimeRunningLightCmd : 0|2@1+ (1,0) [0|3] "" Vector__XXX

BO_ 2566799614 LID: 8 Vector__XXX
 SG_ ImplementRearWorkLightData : 62|2@1+ (1,0) [0|3] "" Vector__XXX
 SG_ ImplLeftFacingWorkLightData : 60|2@1+ (1,0) [0|3] "" Vector__XXX
 SG_ ImplRightFacingWorkLightData : 58|2@1+ (1,0) [0|3] "" Vector__XXX
 SG_ ImplementLeftForwardLightData : 54|2@1+ (1,0) [0|3] "" Vector__XXX
 SG_ ImplementRightForwardLightData : 52|2@1+ (1,0) [0|3] "" Vector__XXX
 SG_ ImplementOEMOption1LightData : 50|2@1+ (1,0) [0|3] "" Vector__XXX
 SG_ ImplementOEMOption2LightData : 48|2@1+ (1,0) [0|3] "" Vector__XXX
 SG_ TractorFrontHighWorkLightData : 46|2@1+ (1,0) [0|3] "" Vector__XXX
 SG_ TractorFrontLowWorkLightData : 44|2@1+ (1,0) [0|3] "" Vector__XXX
 SG_ TractorSideHighWorkLightData : 42|2@1+ (1,0) [0|3] "" Vector__XXX
 SG_ TractorSideLowWorkLightData : 40|2@1+ (1,0) [0|3] "" Vector__XXX
 SG_ TractorRearHighWorkLightData : 38|2@1+ (1,0) [0|3] "" Vector__XXX
 SG_ TractorRearLowWorkLightData : 36|2@1+ (1,0) [0|3] "" Vector__XXX
 SG_ TractorUndersideWorkLightData : 34|2@1+ (1,0) [0|3] "" Vector__XXX
 SG_ RearFogLightData : 32|2@1+ (1,0) [0|3] "" Vector__XXX
 SG_ TractorMarkerLightData : 30|2@1+ (1,0) [0|3] "" Vector__XXX
 SG_ ImplementMarkerLightData : 28|2@1+ (1,0) [0|3] "" Vector__XXX
 SG_ TractorClearanceLightData : 26|2@1+ (1,0) [0|3] "" Vector__XXX
 SG_ ImplementClearanceLightData : 24|2@1+ (1,0) [0|3] "" Vector__XXX
 SG_ LefttStopLightData : 22|2@1+ (1,0) [0|3] "" Vector__XXX
 SG_ RightStopLightData : 20|2@1+ (1,0) [0|3] "" Vector__XXX
 SG_ CentreStopLightData : 18|2@1+ (1,0) [0|3] "" Vector__XXX
 SG_ BackUpLightAndAlarmHornData : 16|2@1+ (1,0) [0|3] "" Vector__XXX
 SG_ LeftTurnSignalLightData : 14|2@1+ (1,0) [0|3] "" Vector__XXX
 SG_ RightTurnSignalLightData : 12|2@1+ (1,0) [0|3] "" Vector__XXX
 SG_ RotationBeaconLightData : 10|2@1+ (1,0) [0|3] "" Vector__XXX
 SG_ TractorFrontFogLightData : 8|2@1+ (1,0) [0|3] "" Vector__XXX
 SG_ HighBeamHeadLightData : 6|2@1+ (1,0) [0|3] "" Vector__XXX
 SG_ LowBeamHeadLightData : 4|2@1+ (1,0) [0|3] "" Vector__XXX
 SG_ AlternateHeadLightData : 2|2@1+ (1,0) [0|3] "" Vector__XXX
 SG_ DaytimeRunningLightData : 0|2@1+ (1,0) [0|3] "" Vector__XXX

BO_ 2365472766 AV15C: 8 Vector__XXX
 SG_ Valve15FailSaveModeCmd : 22|2@1+ (1,0) [0|3] "" Vector__XXX
 SG_ Valve15StateCmd : 16|4@1+ (1,0) [0|15] "" Vector__XXX
 SG_ Valve15PortFlowCmd : 0|8@1+ (0.4,0) [0|100] "%" Vector__XXX

BO_ 2365472510 AV14C: 8 Vector__XXX
 SG_ Valve14FailSaveModeCmd : 22|2@1+ (1,0) [0|3] "" Vector__XXX
 SG_ Valve14StateCmd : 16|4@1+ (1,0) [0|15] "" Vector__XXX
 SG_ Valve14PortFlowCmd : 0|8@1+ (0.4,0) [0|100] "%" Vector__XXX

BO_ 2365472254 AV13C: 8 Vector__XXX
 SG_ Valve13FailSaveModeCmd : 22|2@1+ (1,0) [0|3] "" Vector__XXX
 SG_ Valve13StateCmd : 16|4@1+ (1,0) [0|15] "" Vector__XXX
 SG_ Valve13PortFlowCmd : 0|8@1+ (0.4,0) [0|100] "%" Vector__XXX

BO_ 2365471998 AV12C: 8 Vector__XXX
 SG_ Valve12FailSaveModeCmd : 22|2@1+ (1,0) [0|3] "" Vector__XXX
 SG_ Valve12StateCmd : 16|4@1+ (1,0) [0|15] "" Vector__XXX
 SG_ Valve12PortFlowCmd : 0|8@1+ (0.4,0) [0|100] "%" Vector__XXX

BO_ 2365471742 AV11C: 8 Vector__XXX
 SG_ Valve11FailSaveModeCmd : 22|2@1+ (1,0) [0|3] "" Vector__XXX
 SG_ Valve11StateCmd : 16|4@1+ (1,0) [0|15] "" Vector__XXX
 SG_ Valve11PortFlowCmd : 0|8@1+ (0.4,0) [0|100] "%" Vector__XXX

BO_ 2365471486 AV10C: 8 Vector__XXX
 SG_ Valve10FailSaveModeCmd : 22|2@1+ (1,0) [0|3] "" Vector__XXX
 SG_ Valve10StateCmd : 16|4@1+ (1,0) [0|15] "" Vector__XXX
 SG_ Valve10PortFlowCmd : 0|8@1+ (0.4,0) [0|100] "%" Vector__XXX

BO_ 2365471230 AV09C: 8 Vector__XXX
 SG_ Valve9FailSaveModeCmd : 22|2@1+ (1,0) [0|3] "" Vector__XXX
 SG_ Valve9StateCmd : 16|4@1+ (1,0) [0|15] "" Vector__XXX
 SG_ Valve9PortFlowCmd : 0|8@1+ (0.4,0) [0|100] "%" Vector__XXX

BO_ 2365470974 AV08C: 8 Vector__XXX
 SG_ Valve8FailSaveModeCmd : 22|2@1+ (1,0) [0|3] "" Vector__XXX
 SG_ Valve8StateCmd : 16|4@1+ (1,0) [0|15] "" Vector__XXX
 SG_ Valve8PortFlowCmd : 0|8@1+ (0.4,0) [0|100] "%" Vector__XXX

BO_ 2365470718 AV07C: 8 Vector__XXX
 SG_ Valve7FailSaveModeCmd : 22|2@1+ (1,0) [0|3] "" Vector__XXX
 SG_ Valve7StateCmd : 16|4@1+ (1,0) [0|15] "" Vector__XXX
 SG_ Valve7PortFlowCmd : 0|8@1+ (0.4,0) [0|100] "%" Vector__XXX

BO_ 2365470462 AV06C: 8 Vector__XXX
 SG_ Valve6FailSaveModeCmd : 22|2@1+ (1,0) [0|3] "" Vector__XXX
 SG_ Valve6StateCmd : 16|4@1+ (1,0) [0|15] "" Vector__XXX
 SG_ Valve6PortFlowCmd : 0|8@1+ (0.4,0) [0|100] "%" Vector__XXX

BO_ 2365470206 AV05C: 8 Vector__XXX
 SG_ Valve5FailSaveModeCmd : 22|2@1+ (1,0) [0|3] "" Vector__XXX
 SG_ Valve5StateCmd : 16|4@1+ (1,0) [0|15] "" Vector__XXX
 SG_ Valve5PortFlowCmd : 0|8@1+ (0.4,0) [0|100] "%" Vector__XXX

BO_ 2365469950 AV04C: 8 Vector__XXX
 SG_ Valve4FailSaveModeCmd : 22|2@1+ (1,0) [0|3] "" Vector__XXX
 SG_ Valve4StateCmd : 16|4@1+ (1,0) [0|15] "" Vector__XXX
 SG_ Valve4PortFlowCmd : 0|8@1+ (0.4,0) [0|100] "%" Vector__XXX

BO_ 2365469694 AV03C: 8 Vector__XXX
 SG_ Valve3FailSaveModeCmd : 22|2@1+ (1,0) [0|3] "" Vector__XXX
 SG_ Valve3StateCmd : 16|4@1+ (1,0) [0|15] "" Vector__XXX
 SG_ Valve3PortFlowCmd : 0|8@1+ (0.4,0) [0|100] "%" Vector__XXX

BO_ 2365469438 AV02C: 8 Vector__XXX
 SG_ Valve2FailSaveModeCmd : 22|2@1+ (1,0) [0|3] "" Vector__XXX
 SG_ Valve2StateCmd : 16|4@1+ (1,0) [0|15] "" Vector__XXX
 SG_ Valve2PortFlowCmd : 0|8@1+ (0.4,0) [0|100] "%" Vector__XXX

BO_ 2365469182 AV01C: 8 Vector__XXX
 SG_ Valve1FailSaveModeCmd : 22|2@1+ (1,0) [0|3] "" Vector__XXX
 SG_ Valve1StateCmd : 16|4@1+ (1,0) [0|15] "" Vector__XXX
 SG_ Valve1PortFlowCmd : 0|8@1+ (0.4,0) [0|100] "%" Vector__XXX

BO_ 2365468926 AV00C: 8 Vector__XXX
 SG_ Valve0FailSaveModeCmd : 22|2@1+ (1,0) [0|3] "" Vector__XXX
 SG_ Valve0StateCmd : 16|4@1+ (1,0) [0|15] "" Vector__XXX
 SG_ Valve0PortFlowCmd : 0|8@1+ (0.4,0) [0|100] "%" Vector__XXX

BO_ 2365468670 AV15MF: 8 Vector__XXX
 SG_ Valve15LimitStatus : 61|3@1+ (1,0) [0|7] "" Vector__XXX
 SG_ Valve15ReturnPortPressure : 48|8@1+ (16,0) [0|4000] "kPa" Vector__XXX
 SG_ Valve15RetractPortPressure : 32|16@1+ (5,0) [0|321275] "kPa" Vector__XXX
 SG_ Valve15ExtendedPortPressure : 16|16@1+ (5,0) [0|321275] "kPa" Vector__XXX
 SG_ Valve15RetractPortMeasuredFlow : 8|8@1+ (1,-125) [-125|125] "%" Vector__XXX
 SG_ Valve15ExtendedPortMeasuredFlow : 0|8@1+ (1,-125) [-125|125] "%" Vector__XXX

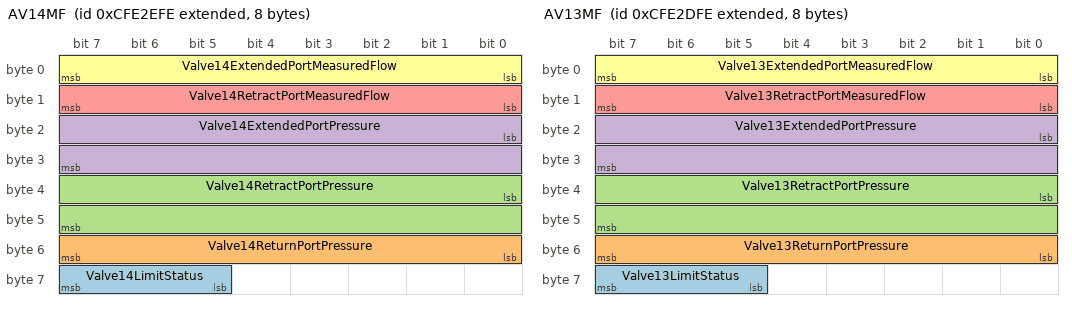
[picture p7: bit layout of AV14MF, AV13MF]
BO_ 2365468414 AV14MF: 8 Vector__XXX
 SG_ Valve14LimitStatus : 61|3@1+ (1,0) [0|7] "" Vector__XXX
 SG_ Valve14ReturnPortPressure : 48|8@1+ (16,0) [0|4000] "kPa" Vector__XXX
 SG_ Valve14RetractPortPressure : 32|16@1+ (5,0) [0|321275] "kPa" Vector__XXX
 SG_ Valve14ExtendedPortPressure : 16|16@1+ (5,0) [0|321275] "kPa" Vector__XXX
 SG_ Valve14RetractPortMeasuredFlow : 8|8@1+ (1,-125) [-125|125] "%" Vector__XXX
 SG_ Valve14ExtendedPortMeasuredFlow : 0|8@1+ (1,-125) [-125|125] "%" Vector__XXX

BO_ 2365468158 AV13MF: 8 Vector__XXX
 SG_ Valve13LimitStatus : 61|3@1+ (1,0) [0|7] "" Vector__XXX
 SG_ Valve13ReturnPortPressure : 48|8@1+ (16,0) [0|4000] "kPa" Vector__XXX
 SG_ Valve13RetractPortPressure : 32|16@1+ (5,0) [0|321275] "kPa" Vector__XXX
 SG_ Valve13ExtendedPortPressure : 16|16@1+ (5,0) [0|321275] "kPa" Vector__XXX
 SG_ Valve13RetractPortMeasuredFlow : 8|8@1+ (1,-125) [-125|125] "%" Vector__XXX
 SG_ Valve13ExtendedPortMeasuredFlow : 0|8@1+ (1,-125) [-125|125] "%" Vector__XXX

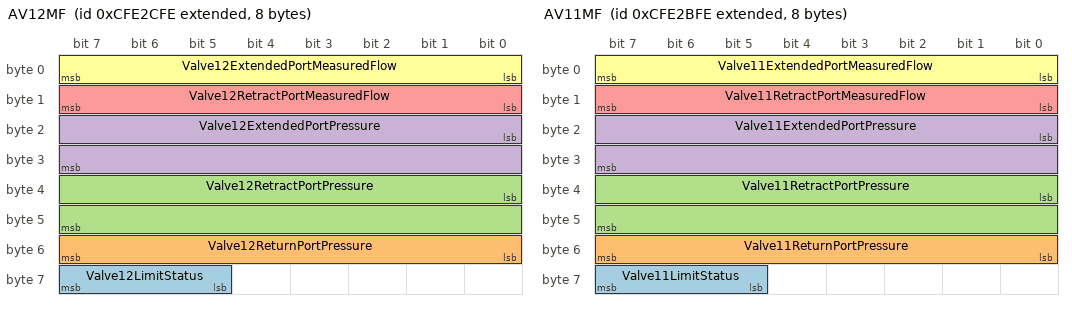
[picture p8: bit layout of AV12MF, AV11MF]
BO_ 2365467902 AV12MF: 8 Vector__XXX
 SG_ Valve12LimitStatus : 61|3@1+ (1,0) [0|7] "" Vector__XXX
 SG_ Valve12ReturnPortPressure : 48|8@1+ (16,0) [0|4000] "kPa" Vector__XXX
 SG_ Valve12RetractPortPressure : 32|16@1+ (5,0) [0|321275] "kPa" Vector__XXX
 SG_ Valve12ExtendedPortPressure : 16|16@1+ (5,0) [0|321275] "kPa" Vector__XXX
 SG_ Valve12RetractPortMeasuredFlow : 8|8@1+ (1,-125) [-125|125] "%" Vector__XXX
 SG_ Valve12ExtendedPortMeasuredFlow : 0|8@1+ (1,-125) [-125|125] "%" Vector__XXX

BO_ 2365467646 AV11MF: 8 Vector__XXX
 SG_ Valve11LimitStatus : 61|3@1+ (1,0) [0|7] "" Vector__XXX
 SG_ Valve11ReturnPortPressure : 48|8@1+ (16,0) [0|4000] "kPa" Vector__XXX
 SG_ Valve11RetractPortPressure : 32|16@1+ (5,0) [0|321275] "kPa" Vector__XXX
 SG_ Valve11ExtendedPortPressure : 16|16@1+ (5,0) [0|321275] "kPa" Vector__XXX
 SG_ Valve11RetractPortMeasuredFlow : 8|8@1+ (1,-125) [-125|125] "%" Vector__XXX
 SG_ Valve11ExtendedPortMeasuredFlow : 0|8@1+ (1,-125) [-125|125] "%" Vector__XXX

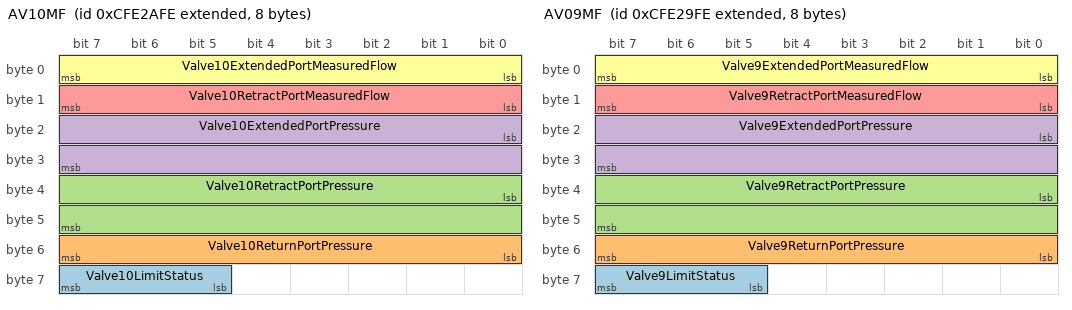
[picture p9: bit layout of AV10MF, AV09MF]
BO_ 2365467390 AV10MF: 8 Vector__XXX
 SG_ Valve10LimitStatus : 61|3@1+ (1,0) [0|7] "" Vector__XXX
 SG_ Valve10ReturnPortPressure : 48|8@1+ (16,0) [0|4000] "kPa" Vector__XXX
 SG_ Valve10RetractPortPressure : 32|16@1+ (5,0) [0|321275] "kPa" Vector__XXX
 SG_ Valve10ExtendedPortPressure : 16|16@1+ (5,0) [0|321275] "kPa" Vector__XXX
 SG_ Valve10RetractPortMeasuredFlow : 8|8@1+ (1,-125) [-125|125] "%" Vector__XXX
 SG_ Valve10ExtendedPortMeasuredFlow : 0|8@1+ (1,-125) [-125|125] "%" Vector__XXX

BO_ 2365467134 AV09MF: 8 Vector__XXX
 SG_ Valve9LimitStatus : 61|3@1+ (1,0) [0|7] "" Vector__XXX
 SG_ Valve9ReturnPortPressure : 48|8@1+ (16,0) [0|4000] "kPa" Vector__XXX
 SG_ Valve9RetractPortPressure : 32|16@1+ (5,0) [0|321275] "kPa" Vector__XXX
 SG_ Valve9ExtendedPortPressure : 16|16@1+ (5,0) [0|321275] "kPa" Vector__XXX
 SG_ Valve9RetractPortMeasuredFlow : 8|8@1+ (1,-125) [-125|125] "%" Vector__XXX
 SG_ Valve9ExtendedPortMeasuredFlow : 0|8@1+ (1,-125) [-125|125] "%" Vector__XXX

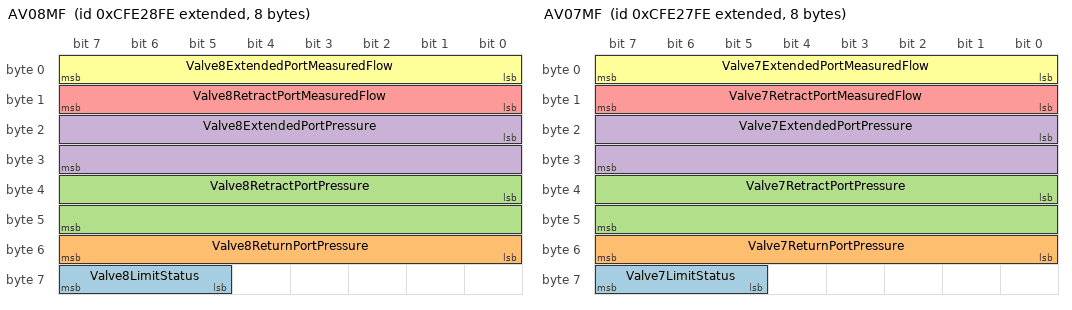
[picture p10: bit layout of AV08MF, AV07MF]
BO_ 2365466878 AV08MF: 8 Vector__XXX
 SG_ Valve8LimitStatus : 61|3@1+ (1,0) [0|7] "" Vector__XXX
 SG_ Valve8ReturnPortPressure : 48|8@1+ (16,0) [0|4000] "kPa" Vector__XXX
 SG_ Valve8RetractPortPressure : 32|16@1+ (5,0) [0|321275] "kPa" Vector__XXX
 SG_ Valve8ExtendedPortPressure : 16|16@1+ (5,0) [0|321275] "kPa" Vector__XXX
 SG_ Valve8RetractPortMeasuredFlow : 8|8@1+ (1,-125) [-125|125] "%" Vector__XXX
 SG_ Valve8ExtendedPortMeasuredFlow : 0|8@1+ (1,-125) [-125|125] "%" Vector__XXX

BO_ 2365466622 AV07MF: 8 Vector__XXX
 SG_ Valve7LimitStatus : 61|3@1+ (1,0) [0|7] "" Vector__XXX
 SG_ Valve7ReturnPortPressure : 48|8@1+ (16,0) [0|4000] "kPa" Vector__XXX
 SG_ Valve7RetractPortPressure : 32|16@1+ (5,0) [0|321275] "kPa" Vector__XXX
 SG_ Valve7ExtendedPortPressure : 16|16@1+ (5,0) [0|321275] "kPa" Vector__XXX
 SG_ Valve7RetractPortMeasuredFlow : 8|8@1+ (1,-125) [-125|125] "%" Vector__XXX
 SG_ Valve7ExtendedPortMeasuredFlow : 0|8@1+ (1,-125) [-125|125] "%" Vector__XXX

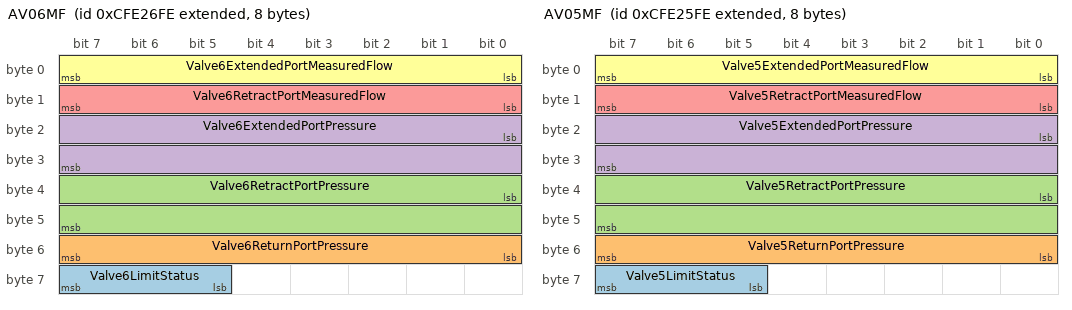
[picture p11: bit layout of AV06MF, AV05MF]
BO_ 2365466366 AV06MF: 8 Vector__XXX
 SG_ Valve6LimitStatus : 61|3@1+ (1,0) [0|7] "" Vector__XXX
 SG_ Valve6ReturnPortPressure : 48|8@1+ (16,0) [0|4000] "kPa" Vector__XXX
 SG_ Valve6RetractPortPressure : 32|16@1+ (5,0) [0|321275] "kPa" Vector__XXX
 SG_ Valve6ExtendedPortPressure : 16|16@1+ (5,0) [0|321275] "kPa" Vector__XXX
 SG_ Valve6RetractPortMeasuredFlow : 8|8@1+ (1,-125) [-125|125] "%" Vector__XXX
 SG_ Valve6ExtendedPortMeasuredFlow : 0|8@1+ (1,-125) [-125|125] "%" Vector__XXX

BO_ 2365466110 AV05MF: 8 Vector__XXX
 SG_ Valve5LimitStatus : 61|3@1+ (1,0) [0|7] "" Vector__XXX
 SG_ Valve5ReturnPortPressure : 48|8@1+ (16,0) [0|4000] "kPa" Vector__XXX
 SG_ Valve5RetractPortPressure : 32|16@1+ (5,0) [0|321275] "kPa" Vector__XXX
 SG_ Valve5ExtendedPortPressure : 16|16@1+ (5,0) [0|321275] "kPa" Vector__XXX
 SG_ Valve5RetractPortMeasuredFlow : 8|8@1+ (1,-125) [-125|125] "%" Vector__XXX
 SG_ Valve5ExtendedPortMeasuredFlow : 0|8@1+ (1,-125) [-125|125] "%" Vector__XXX

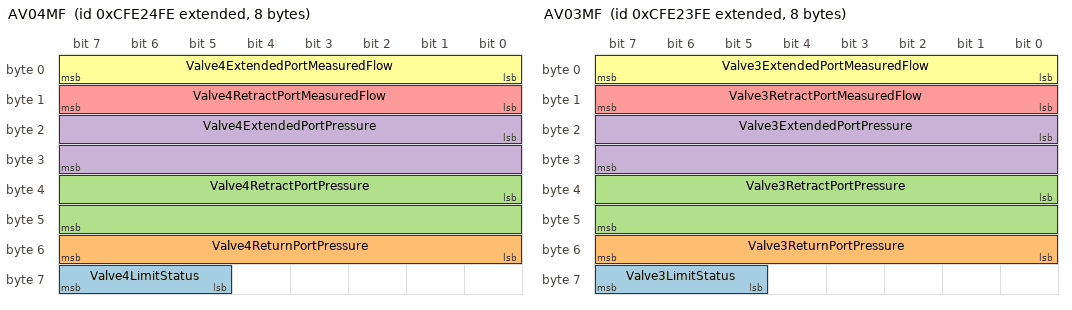
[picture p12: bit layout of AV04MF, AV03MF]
BO_ 2365465854 AV04MF: 8 Vector__XXX
 SG_ Valve4LimitStatus : 61|3@1+ (1,0) [0|7] "" Vector__XXX
 SG_ Valve4ReturnPortPressure : 48|8@1+ (16,0) [0|4000] "kPa" Vector__XXX
 SG_ Valve4RetractPortPressure : 32|16@1+ (5,0) [0|321275] "kPa" Vector__XXX
 SG_ Valve4ExtendedPortPressure : 16|16@1+ (5,0) [0|321275] "kPa" Vector__XXX
 SG_ Valve4RetractPortMeasuredFlow : 8|8@1+ (1,-125) [-125|125] "%" Vector__XXX
 SG_ Valve4ExtendedPortMeasuredFlow : 0|8@1+ (1,-125) [-125|125] "%" Vector__XXX

BO_ 2365465598 AV03MF: 8 Vector__XXX
 SG_ Valve3LimitStatus : 61|3@1+ (1,0) [0|7] "" Vector__XXX
 SG_ Valve3ReturnPortPressure : 48|8@1+ (16,0) [0|4000] "kPa" Vector__XXX
 SG_ Valve3RetractPortPressure : 32|16@1+ (5,0) [0|321275] "kPa" Vector__XXX
 SG_ Valve3ExtendedPortPressure : 16|16@1+ (5,0) [0|321275] "kPa" Vector__XXX
 SG_ Valve3RetractPortMeasuredFlow : 8|8@1+ (1,-125) [-125|125] "%" Vector__XXX
 SG_ Valve3ExtendedPortMeasuredFlow : 0|8@1+ (1,-125) [-125|125] "%" Vector__XXX

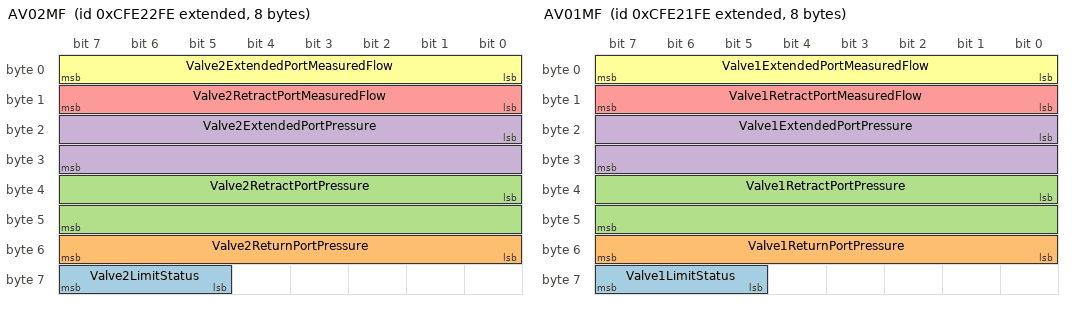
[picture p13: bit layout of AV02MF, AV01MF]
BO_ 2365465342 AV02MF: 8 Vector__XXX
 SG_ Valve2LimitStatus : 61|3@1+ (1,0) [0|7] "" Vector__XXX
 SG_ Valve2ReturnPortPressure : 48|8@1+ (16,0) [0|4000] "kPa" Vector__XXX
 SG_ Valve2RetractPortPressure : 32|16@1+ (5,0) [0|321275] "kPa" Vector__XXX
 SG_ Valve2ExtendedPortPressure : 16|16@1+ (5,0) [0|321275] "kPa" Vector__XXX
 SG_ Valve2RetractPortMeasuredFlow : 8|8@1+ (1,-125) [-125|125] "%" Vector__XXX
 SG_ Valve2ExtendedPortMeasuredFlow : 0|8@1+ (1,-125) [-125|125] "%" Vector__XXX

BO_ 2365465086 AV01MF: 8 Vector__XXX
 SG_ Valve1LimitStatus : 61|3@1+ (1,0) [0|7] "" Vector__XXX
 SG_ Valve1ReturnPortPressure : 48|8@1+ (16,0) [0|4000] "kPa" Vector__XXX
 SG_ Valve1RetractPortPressure : 32|16@1+ (5,0) [0|321275] "kPa" Vector__XXX
 SG_ Valve1ExtendedPortPressure : 16|16@1+ (5,0) [0|321275] "kPa" Vector__XXX
 SG_ Valve1RetractPortMeasuredFlow : 8|8@1+ (1,-125) [-125|125] "%" Vector__XXX
 SG_ Valve1ExtendedPortMeasuredFlow : 0|8@1+ (1,-125) [-125|125] "%" Vector__XXX

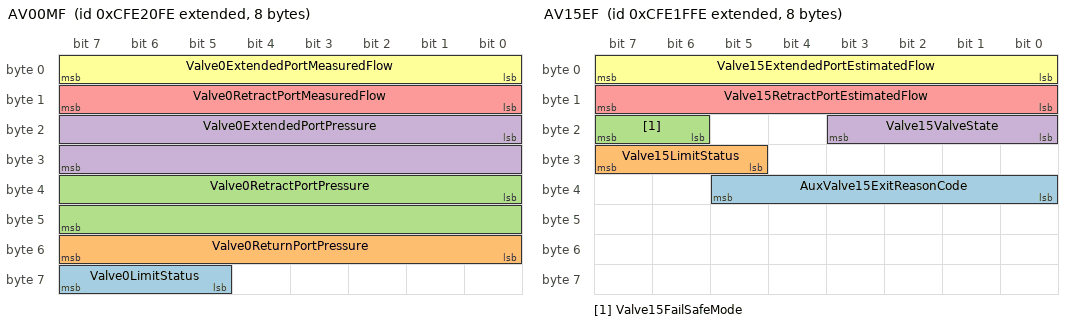
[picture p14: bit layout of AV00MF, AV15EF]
BO_ 2365464830 AV00MF: 8 Vector__XXX
 SG_ Valve0LimitStatus : 61|3@1+ (1,0) [0|7] "" Vector__XXX
 SG_ Valve0ReturnPortPressure : 48|8@1+ (16,0) [0|4000] "kPa" Vector__XXX
 SG_ Valve0RetractPortPressure : 32|16@1+ (5,0) [0|321275] "kPa" Vector__XXX
 SG_ Valve0ExtendedPortPressure : 16|16@1+ (5,0) [0|321275] "kPa" Vector__XXX
 SG_ Valve0RetractPortMeasuredFlow : 8|8@1+ (1,-125) [-125|125] "%" Vector__XXX
 SG_ Valve0ExtendedPortMeasuredFlow : 0|8@1+ (1,-125) [-125|125] "%" Vector__XXX

BO_ 2365464574 AV15EF: 8 Vector__XXX
 SG_ AuxValve15ExitReasonCode : 32|6@1+ (1,0) [0|63] "" Vector__XXX
 SG_ Valve15LimitStatus : 29|3@1+ (1,0) [0|7] "" Vector__XXX
 SG_ Valve15FailSafeMode : 22|2@1+ (1,0) [0|3] "" Vector__XXX
 SG_ Valve15ValveState : 16|4@1+ (1,0) [0|15] "" Vector__XXX
 SG_ Valve15RetractPortEstimatedFlow : 8|8@1+ (1,-125) [-125|125] "%" Vector__XXX
 SG_ Valve15ExtendedPortEstimatedFlow : 0|8@1+ (1,-125) [-125|125] "%" Vector__XXX

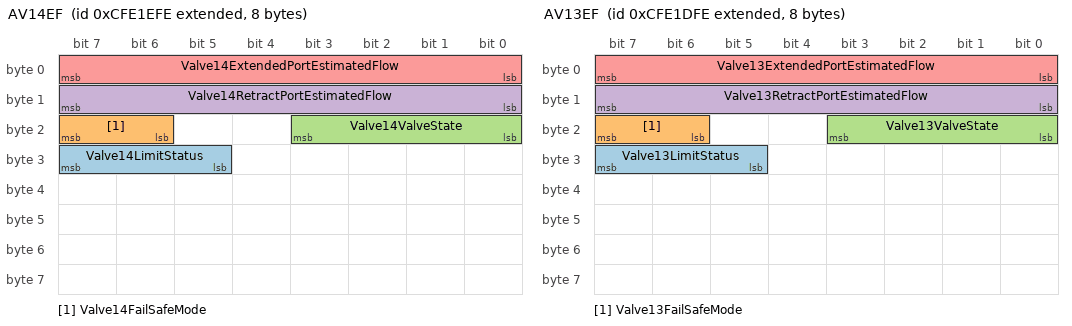
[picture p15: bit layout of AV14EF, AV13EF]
BO_ 2365464318 AV14EF: 8 Vector__XXX
 SG_ Valve14LimitStatus : 29|3@1+ (1,0) [0|7] "" Vector__XXX
 SG_ Valve14FailSafeMode : 22|2@1+ (1,0) [0|3] "" Vector__XXX
 SG_ Valve14ValveState : 16|4@1+ (1,0) [0|15] "" Vector__XXX
 SG_ Valve14RetractPortEstimatedFlow : 8|8@1+ (1,-125) [-125|125] "%" Vector__XXX
 SG_ Valve14ExtendedPortEstimatedFlow : 0|8@1+ (1,-125) [-125|125] "%" Vector__XXX

BO_ 2365464062 AV13EF: 8 Vector__XXX
 SG_ Valve13LimitStatus : 29|3@1+ (1,0) [0|7] "" Vector__XXX
 SG_ Valve13FailSafeMode : 22|2@1+ (1,0) [0|3] "" Vector__XXX
 SG_ Valve13ValveState : 16|4@1+ (1,0) [0|15] "" Vector__XXX
 SG_ Valve13RetractPortEstimatedFlow : 8|8@1+ (1,-125) [-125|125] "%" Vector__XXX
 SG_ Valve13ExtendedPortEstimatedFlow : 0|8@1+ (1,-125) [-125|125] "%" Vector__XXX

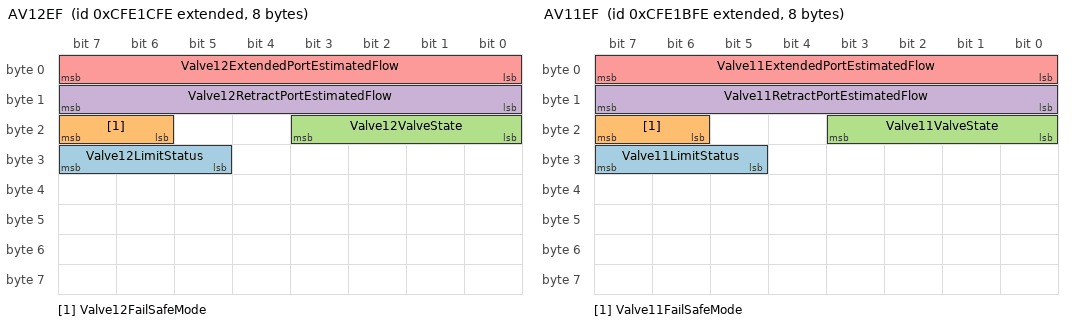
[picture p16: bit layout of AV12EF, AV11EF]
BO_ 2365463806 AV12EF: 8 Vector__XXX
 SG_ Valve12LimitStatus : 29|3@1+ (1,0) [0|7] "" Vector__XXX
 SG_ Valve12FailSafeMode : 22|2@1+ (1,0) [0|3] "" Vector__XXX
 SG_ Valve12ValveState : 16|4@1+ (1,0) [0|15] "" Vector__XXX
 SG_ Valve12RetractPortEstimatedFlow : 8|8@1+ (1,-125) [-125|125] "%" Vector__XXX
 SG_ Valve12ExtendedPortEstimatedFlow : 0|8@1+ (1,-125) [-125|125] "%" Vector__XXX

BO_ 2365463550 AV11EF: 8 Vector__XXX
 SG_ Valve11LimitStatus : 29|3@1+ (1,0) [0|7] "" Vector__XXX
 SG_ Valve11FailSafeMode : 22|2@1+ (1,0) [0|3] "" Vector__XXX
 SG_ Valve11ValveState : 16|4@1+ (1,0) [0|15] "" Vector__XXX
 SG_ Valve11RetractPortEstimatedFlow : 8|8@1+ (1,-125) [-125|125] "%" Vector__XXX
 SG_ Valve11ExtendedPortEstimatedFlow : 0|8@1+ (1,-125) [-125|125] "%" Vector__XXX

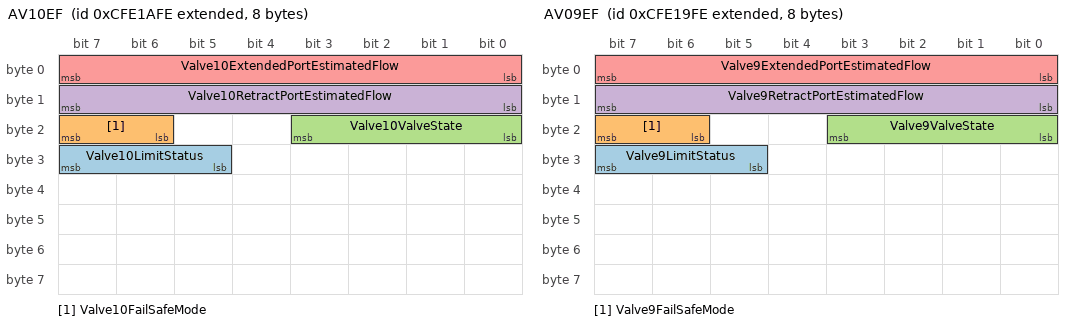
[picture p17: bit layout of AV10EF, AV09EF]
BO_ 2365463294 AV10EF: 8 Vector__XXX
 SG_ Valve10LimitStatus : 29|3@1+ (1,0) [0|7] "" Vector__XXX
 SG_ Valve10FailSafeMode : 22|2@1+ (1,0) [0|3] "" Vector__XXX
 SG_ Valve10ValveState : 16|4@1+ (1,0) [0|15] "" Vector__XXX
 SG_ Valve10RetractPortEstimatedFlow : 8|8@1+ (1,-125) [-125|125] "%" Vector__XXX
 SG_ Valve10ExtendedPortEstimatedFlow : 0|8@1+ (1,-125) [-125|125] "%" Vector__XXX

BO_ 2365463038 AV09EF: 8 Vector__XXX
 SG_ Valve9LimitStatus : 29|3@1+ (1,0) [0|7] "" Vector__XXX
 SG_ Valve9FailSafeMode : 22|2@1+ (1,0) [0|3] "" Vector__XXX
 SG_ Valve9ValveState : 16|4@1+ (1,0) [0|15] "" Vector__XXX
 SG_ Valve9RetractPortEstimatedFlow : 8|8@1+ (1,-125) [-125|125] "%" Vector__XXX
 SG_ Valve9ExtendedPortEstimatedFlow : 0|8@1+ (1,-125) [-125|125] "%" Vector__XXX

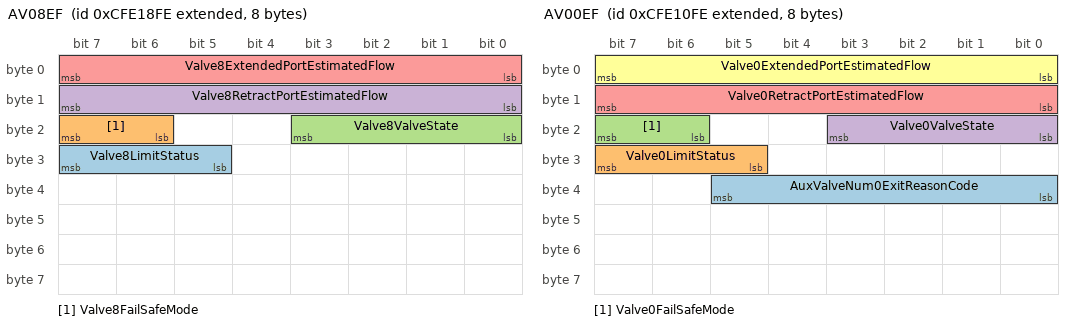
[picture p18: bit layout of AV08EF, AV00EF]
BO_ 2365462782 AV08EF: 8 Vector__XXX
 SG_ Valve8LimitStatus : 29|3@1+ (1,0) [0|7] "" Vector__XXX
 SG_ Valve8FailSafeMode : 22|2@1+ (1,0) [0|3] "" Vector__XXX
 SG_ Valve8ValveState : 16|4@1+ (1,0) [0|15] "" Vector__XXX
 SG_ Valve8RetractPortEstimatedFlow : 8|8@1+ (1,-125) [-125|125] "%" Vector__XXX
 SG_ Valve8ExtendedPortEstimatedFlow : 0|8@1+ (1,-125) [-125|125] "%" Vector__XXX

BO_ 2365462526 AV07EF: 8 Vector__XXX
 SG_ Valve7LimitStatus : 29|3@1+ (1,0) [0|7] "" Vector__XXX
 SG_ Valve7FailSafeMode : 22|2@1+ (1,0) [0|3] "" Vector__XXX
 SG_ Valve7ValveState : 16|4@1+ (1,0) [0|15] "" Vector__XXX
 SG_ Valve7RetractPortEstimatedFlow : 8|8@1+ (1,-125) [-125|125] "%" Vector__XXX
 SG_ Valve7ExtendedPortEstimatedFlow : 0|8@1+ (1,-125) [-125|125] "%" Vector__XXX

BO_ 2365462270 AV06EF: 8 Vector__XXX
 SG_ Valve6LimitStatus : 29|3@1+ (1,0) [0|7] "" Vector__XXX
 SG_ Valve6FailSafeMode : 22|2@1+ (1,0) [0|3] "" Vector__XXX
 SG_ Valve6ValveState : 16|4@1+ (1,0) [0|15] "" Vector__XXX
 SG_ Valve6RetractPortEstimatedFlow : 8|8@1+ (1,-125) [-125|125] "%" Vector__XXX
 SG_ Valve6ExtendedPortEstimatedFlow : 0|8@1+ (1,-125) [-125|125] "%" Vector__XXX

BO_ 2365462014 AV05EF: 8 Vector__XXX
 SG_ Valve5LimitStatus : 29|3@1+ (1,0) [0|7] "" Vector__XXX
 SG_ Valve5FailSafeMode : 22|2@1+ (1,0) [0|3] "" Vector__XXX
 SG_ Valve5ValveState : 16|4@1+ (1,0) [0|15] "" Vector__XXX
 SG_ Valve5RetractPortEstimatedFlow : 8|8@1+ (1,-125) [-125|125] "%" Vector__XXX
 SG_ Valve5ExtendedPortEstimatedFlow : 0|8@1+ (1,-125) [-125|125] "%" Vector__XXX

BO_ 2365461758 AV04EF: 8 Vector__XXX
 SG_ Valve4LimitStatus : 29|3@1+ (1,0) [0|7] "" Vector__XXX
 SG_ Valve4FailSafeMode : 22|2@1+ (1,0) [0|3] "" Vector__XXX
 SG_ Valve4ValveState : 16|4@1+ (1,0) [0|15] "" Vector__XXX
 SG_ Valve4RetractPortEstimatedFlow : 8|8@1+ (1,-125) [-125|125] "%" Vector__XXX
 SG_ Valve4ExtendedPortEstimatedFlow : 0|8@1+ (1,-125) [-125|125] "%" Vector__XXX

BO_ 2365461502 AV03EF: 8 Vector__XXX
 SG_ Valve3LimitStatus : 29|3@1+ (1,0) [0|7] "" Vector__XXX
 SG_ Valve3FailSafeMode : 22|2@1+ (1,0) [0|3] "" Vector__XXX
 SG_ Valve3ValveState : 16|4@1+ (1,0) [0|15] "" Vector__XXX
 SG_ Valve3RetractPortEstimatedFlow : 8|8@1+ (1,-125) [-125|125] "%" Vector__XXX
 SG_ Valve3ExtendedPortEstimatedFlow : 0|8@1+ (1,-125) [-125|125] "%" Vector__XXX

BO_ 2365461246 AV02EF: 8 Vector__XXX
 SG_ Valve2LimitStatus : 29|3@1+ (1,0) [0|7] "" Vector__XXX
 SG_ Valve2FailSafeMode : 22|2@1+ (1,0) [0|3] "" Vector__XXX
 SG_ Valve2ValveState : 16|4@1+ (1,0) [0|15] "" Vector__XXX
 SG_ Valve2RetractPortEstimatedFlow : 8|8@1+ (1,-125) [-125|125] "%" Vector__XXX
 SG_ Valve2ExtendedPortEstimatedFlow : 0|8@1+ (1,-125) [-125|125] "%" Vector__XXX

BO_ 2365460990 AV01EF: 8 Vector__XXX
 SG_ Valve1LimitStatus : 29|3@1+ (1,0) [0|7] "" Vector__XXX
 SG_ Valve1FailSafeMode : 22|2@1+ (1,0) [0|3] "" Vector__XXX
 SG_ Valve1ValveState : 16|4@1+ (1,0) [0|15] "" Vector__XXX
 SG_ Valve1RetractPortEstimatedFlow : 8|8@1+ (1,-125) [-125|125] "%" Vector__XXX
 SG_ Valve1ExtendedPortEstimatedFlow : 0|8@1+ (1,-125) [-125|125] "%" Vector__XXX

BO_ 2365460734 AV00EF: 8 Vector__XXX
 SG_ AuxValveNum0ExitReasonCode : 32|6@1+ (1,0) [0|63] "" Vector__XXX
 SG_ Valve0LimitStatus : 29|3@1+ (1,0) [0|7] "" Vector__XXX
 SG_ Valve0FailSafeMode : 22|2@1+ (1,0) [0|3] "" Vector__XXX
 SG_ Valve0ValveState : 16|4@1+ (1,0) [0|15] "" Vector__XXX
 SG_ Valve0RetractPortEstimatedFlow : 8|8@1+ (1,-125) [-125|125] "%" Vector__XXX
 SG_ Valve0ExtendedPortEstimatedFlow : 0|8@1+ (1,-125) [-125|125] "%" Vector__XXX

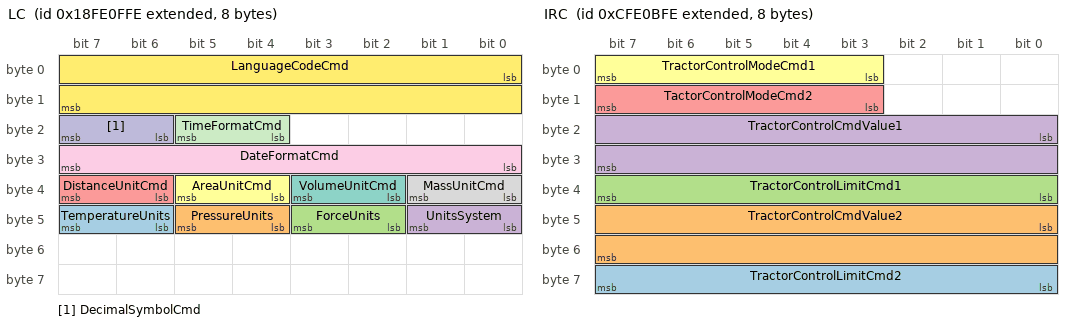
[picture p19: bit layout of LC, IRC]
BO_ 2566787070 LC: 8 Vector__XXX
 SG_ TemperatureUnits : 46|2@1+ (1,0) [0|3] "" Vector__XXX
 SG_ PressureUnits : 44|2@1+ (1,0) [0|3] "" Vector__XXX
 SG_ ForceUnits : 42|2@1+ (1,0) [0|3] "" Vector__XXX
 SG_ UnitsSystem : 40|2@1+ (1,0) [0|3] "" Vector__XXX
 SG_ DistanceUnitCmd : 38|2@1+ (1,0) [0|3] "" Vector__XXX
 SG_ AreaUnitCmd : 36|2@1+ (1,0) [0|3] "" Vector__XXX
 SG_ VolumeUnitCmd : 34|2@1+ (1,0) [0|3] "" Vector__XXX
 SG_ MassUnitCmd : 32|2@1+ (1,0) [0|3] "" Vector__XXX
 SG_ DateFormatCmd : 24|8@1+ (1,0) [0|255] "" Vector__XXX
 SG_ DecimalSymbolCmd : 22|2@1+ (1,0) [0|3] "" Vector__XXX
 SG_ TimeFormatCmd : 20|2@1+ (1,0) [0|3] "" Vector__XXX
 SG_ LanguageCodeCmd : 0|16@1+ (1,0) [0|16383] "" Vector__XXX

BO_ 2566786814 RESRR: 8 Vector__XXX
 SG_ ActualRepetitionRate : 24|16@1+ (1,0) [0|64255] "ms" Vector__XXX
 SG_ PGN : 0|24@1+ (1,0) [0|16777200] "" Vector__XXX

BO_ 2633895422 WSMSTR: 8 Vector__XXX
 SG_ NumberOfMembers : 0|8@1+ (1,0) [0|0] "" Vector__XXX

BO_ 2633895166 WSMEM: 8 Vector__XXX
 SG_ ArbitraryAddressCapable : 63|1@1+ (1,0) [0|1] "" Vector__XXX
 SG_ ECUInstance : 32|3@1+ (1,0) [0|7] "" Vector__XXX
 SG_ Function : 40|8@1+ (1,0) [0|255] "" Vector__XXX
 SG_ FunctionInstance : 35|5@1+ (1,0) [0|31] "" Vector__XXX
 SG_ IdentityNumber : 0|21@1+ (1,0) [0|2097152] "" Vector__XXX
 SG_ IndustryGroup M : 60|3@1+ (1,0) [0|7] "" Vector__XXX
 SG_ ManufacturerCode : 21|11@1+ (1,0) [0|2047] "" Vector__XXX
 SG_ VehicleSystem m0 : 49|7@1+ (1,0) [0|127] "" Vector__XXX
 SG_ VehicleSystem1 m1 : 49|7@1+ (1,0) [0|127] "" Vector__XXX
 SG_ VehicleSystem2 m2 : 49|7@1+ (1,0) [0|127] "" Vector__XXX
 SG_ VehicleSystem3 m3 : 49|7@1+ (1,0) [0|127] "" Vector__XXX
 SG_ VehicleSystem4 m4 : 49|7@1+ (1,0) [0|127] "" Vector__XXX
 SG_ VehicleSystem5 m5 : 49|7@1+ (1,0) [0|127] "" Vector__XXX
 SG_ VehicleSystemInstance m0 : 56|4@1+ (1,0) [0|15] "" Vector__XXX

BO_ 2365459454 IRC: 8 Vector__XXX
 SG_ TractorControlLimitCmd2 : 56|8@1- (1,0) [0|0] "" Vector__XXX
 SG_ TractorControlCmdValue2 : 40|16@1+ (1,0) [0|0] "" Vector__XXX
 SG_ TractorControlLimitCmd1 : 32|8@1- (1,0) [0|0] "" Vector__XXX
 SG_ TractorControlCmdValue1 : 16|16@1+ (1,0) [0|0] "" Vector__XXX
 SG_ TactorControlModeCmd2 : 11|5@1+ (1,0) [0|31] "" Vector__XXX
 SG_ TractorControlModeCmd1 : 3|5@1+ (1,0) [0|31] "" Vector__XXX

CM_ BO_ 2628452094 "Client (ECU) to File Server message";
CM_ SG_ 2628452094 VI_VolumeName "Length of path name string for Initailize Volume Request";
CM_ SG_ 2628452094 VI_Flag_OverwriteExisting "Create a new volume if not yet existing (fails if existing volume)";
CM_ SG_ 2628452094 MF_DestinationPathNameLength "Length of destination path name string for Move File";
CM_ SG_ 2628452094 RF_ReportHiddenFiles "Report Hidden Files";
CM_ SG_ 2628452094 SF_Offset "Offset for Seek File";
CM_ SG_ 2628452094 RF_Count "Number of bytes or number of directory entries to be read";
CM_ SG_ 2628452094 SF_PositionMode "Position Mode for Seek File";
CM_ SG_ 2628452094 OF_PathName "Length of path name string for Open File";
CM_ SG_ 2628452094 MF_SourcePathNameLength "Length of source path name string for Move File";
CM_ SG_ 2628452094 WF_Count "Byte count of data to be written to file";
CM_ SG_ 2628452094 DF_PathName "Length of path name string for Delete File";
CM_ SG_ 2628452094 SA_PathName "Length of path name string for Set File Attributes";
CM_ SG_ 2628452094 VI_Space "The space in units of 512";
CM_ SG_ 2628452094 OF_FlagExclusiveAccess "Open file with exclusive access (fails if already open)";
CM_ SG_ 2628452094 OF_FlagAppend "Open file for appending data to the end of the file";
CM_ SG_ 2628452094 SA_ATTR_Hidden "Attribute 'hidden'";
CM_ SG_ 2628452094 OF_FlagCreateNew "Create a new file if not yet existing";
CM_ SG_ 2628452094 MF_MoveModeRecursive "Recursive mode for Move File";
CM_ SG_ 2628452094 DF_DeleteModeRecursive "Recursive mode for Move File";
CM_ SG_ 2628452094 MF_MoveModeForce "Force mode for Move File";
CM_ SG_ 2628452094 DF_DeleteModeForce "Force mode for Move File";
CM_ SG_ 2628452094 VI_Flag_UsingSpaceSpecified "Create volume using space specified";
CM_ SG_ 2628452094 SA_ATTR_ReadOnly "Attribute 'read-only'";
CM_ SG_ 2628452094 CF_Handle "Handle for Close File";
CM_ SG_ 2628452094 WF_Handle "Handle for Write File";
CM_ SG_ 2628452094 RF_Handle "Handle for Read File";
CM_ SG_ 2628452094 SF_Handle "Handle for Seek File";
CM_ SG_ 2628452094 OF_FlagReadWrite "Read/Write/Both/Directory Flag for Open File";
CM_ SG_ 2628452094 CCD_PathName "Length of path name string for Change Current Directory";
CM_ SG_ 2628452094 MF_MoveModeCopy "Copy mode for Move File";
CM_ SG_ 2628452094 DF_DeleteMode "Copy mode for Move File";
CM_ SG_ 2628452094 GA_PathName "Length of path name string for Get File Attributes";
CM_ SG_ 2628452094 FDT_PathName "Length of path name string for Get File Date and Time";
CM_ SG_ 2628452094 CCD_TAN "Transaction Number for Change Default Directory";
CM_ SG_ 2628452094 GCD_TAN "Transaction Number for Get Default Directory";
CM_ SG_ 2628452094 FDT_TAN "Transaction Number for Get File Data & Time";
CM_ SG_ 2628452094 SA_TAN "Transaction Number for Set File Attribute";
CM_ SG_ 2628452094 GA_TAN "Transaction Number for Get File Attribute";
CM_ SG_ 2628452094 RF_TAN "Transaction Number for Read File";
CM_ SG_ 2628452094 CF_TAN "Transaction Number for Close File";
CM_ SG_ 2628452094 WF_TAN "Transaction Number for Write File";
CM_ SG_ 2628452094 SF_TAN "Transaction Number for Seek File";
CM_ SG_ 2628452094 OF_TAN "Transaction Number for Open File";
CM_ SG_ 2628452094 MF_TAN "Transaction Number for Move File";
CM_ SG_ 2628452094 DF_TAN "Transaction Number for Delete File";
CM_ SG_ 2628452094 VI_TAN "Transaction Number for Initailize Volume Request";
CM_ SG_ 2628452094 FSClientCommand "File Server - Client Command";
CM_ BO_ 2628517630 "File Server to Client (ECU) message";
CM_ SG_ 2628517630 GCD_PathName "Length of path name string for Get Current Directory";
CM_ SG_ 2628517630 GCD_FreeSpace "Free Volume Space for Get Current Directory";
CM_ SG_ 2628517630 FDT_TimeHour "Hour of File Time";
CM_ SG_ 2628517630 FDT_TimeMinutes "Minutes of File Time";
CM_ SG_ 2628517630 FDT_TimeSeconds "Day of File Time";
CM_ SG_ 2628517630 FDT_DateYear "Year of File Date";
CM_ SG_ 2628517630 SF_Position "Position of Seek File response";
CM_ SG_ 2628517630 GA_Size "The number of bytes in a file.";
CM_ SG_ 2628517630 GA_ATTR_VolumeIsCaseSensitive "GetFileAttribute attribute 'Volume is case-sensitive'";
CM_ SG_ 2628517630 GA_ATTR_VolumeIsRemovable "GetFileAttribute attribute 'Volume is not removable'";
CM_ SG_ 2628517630 FDT_DateMonth "Month of File Date";
CM_ SG_ 2628517630 GA_ATTR_SupportsLongFilenames "GetFileAttribute attribute 'Volume supports long filenames'";
CM_ SG_ 2628517630 GA_ATTR_IsDirectory "GetFileAttribute attribute 'Handle specifies a directory'";
CM_ SG_ 2628517630 VI_ATTR_IsDirectory "File Attribute DirectoryFile Attribute DirectoryFile Attribute DirectoryFile Attribute Directory";
CM_ SG_ 2628517630 GA_ATTR_IsVolume "GetFileAttribute attribute 'Handle specifies a volume'";
CM_ SG_ 2628517630 GA_ATTR_VolumeSupportsHidden "GetFileAttribute attribute 'Volume supports hidden attribute'";
CM_ SG_ 2628517630 GA_ATTR_Hidden "GetFileAttribute attribute 'Hidden'";
CM_ SG_ 2628517630 FDT_DateDay "Day of File Date";
CM_ SG_ 2628517630 GA_ATTR_ReadOnly "GetFileAttribute attribute 'Read-Only'";
CM_ SG_ 2628517630 OF_Handle "Handle for Open File";
CM_ SG_ 2628517630 GCD_TotalSpace "Total Volume Space for Get Current Directory";
CM_ SG_ 2628517630 RF_Count "Number of read bytes or number of read directory entries";
CM_ SG_ 2628517630 GSP_SupportMultipleVolumes "File Server Capabilities for Get File Server Properties";
CM_ SG_ 2628517630 WF_Count "Number of written bytes";
CM_ SG_ 2628517630 FDT_ErrorCode "Error Code for Get File Data & Time";
CM_ SG_ 2628517630 RF_ErrorCode "Error Code for Read File";
CM_ SG_ 2628517630 SF_ErrorCode "ErrorCode for Seek File";
CM_ SG_ 2628517630 FSNumberOfOpenFiles "Number of open files";
CM_ SG_ 2628517630 OF_ErrorCode "Error Code for Open File";
CM_ SG_ 2628517630 WF_ErrorCode "Error Code for Write File";
CM_ SG_ 2628517630 CF_ErrorCode "Error Code for Close File";
CM_ SG_ 2628517630 MF_ErrorCode "Error Code for Move File";
CM_ SG_ 2628517630 GA_ErrorCode "Error Code for Get File Attribute";
CM_ SG_ 2628517630 SA_ErrorCode "Error Code for Set File Attribute";
CM_ SG_ 2628517630 GCD_ErrorCode "ErrorCode for Get Current Directory";
CM_ SG_ 2628517630 CCD_ErrorCode "Error Code for Change Current Directory";
CM_ SG_ 2628517630 GSP_MaxNrSimultaneousFilesOpen "The number of files that can maximally be opened simultaneous at the File Server.";
CM_ SG_ 2628517630 DF_ErrorCode "Error Code for Delete File";
CM_ SG_ 2628517630 VI_ErrorCode "Error Code for Volume Initialization";
CM_ SG_ 2628517630 FSBusyWriting "Busy writing";
CM_ SG_ 2628517630 FSBusyReading "Busy reading";
CM_ SG_ 2628517630 OF_TAN "Transaction Number for Open File";
CM_ SG_ 2628517630 SF_TAN "Transaction Number for Seek File";
CM_ SG_ 2628517630 RF_TAN "Transaction Number for Rename File";
CM_ SG_ 2628517630 WF_TAN "Transaction Number for Write File";
CM_ SG_ 2628517630 CF_TAN "Transaction Number for Close File";
CM_ SG_ 2628517630 MF_TAN "Transaction Number for Move File";
CM_ SG_ 2628517630 GA_TAN "Transaction Number for Get File Attributes";
CM_ SG_ 2628517630 SA_TAN "Transaction Number for Set File Attributes";
CM_ SG_ 2628517630 FDT_TAN "Transaction Number for Get File Data & Time";
CM_ SG_ 2628517630 GCD_TAN "Transaction Number for Get Current Directory";
CM_ SG_ 2628517630 CCD_TAN "Transaction Number for Change Current Directory";
CM_ SG_ 2628517630 GSP_VersionNumber "The version of ISO11783-13 that this File Server meets.";
CM_ SG_ 2628517630 DF_TAN "Transaction Number for Delete File";
CM_ SG_ 2628517630 VI_TAN "Transaction Number for Volume Initialization";
CM_ SG_ 2628517630 FSServerCommand "File Server Command";
CM_ BO_ 2364540158 "Electronic Engine Controller #1";
CM_ SG_ 2364540158 EngStarterMode "There are several phases in a starting action and different reasons why a start cannot take place.";
CM_ SG_ 2364540158 SrcAddrssOfCtrllngDvcForEngCtrl "The source address of the SAE J1939 device currently controlling the engine.";
CM_ SG_ 2364540158 ActualEngPercentTorque "The calculated output torque of the engine.";
CM_ SG_ 2364540158 DriversDemandEngPercentTorque "The requested torque output of the engine by the driver.";
CM_ SG_ 2364540158 EngTorqueMode "State signal which indicates which engine torque mode is currently generating, limiting, or controlling the torque.";
CM_ SG_ 2364540158 ActlEngPrcntTorqueHighResolution "This parameter displays an additional torque in percent of the reference engine torque.";
CM_ BO_ 2563243774 "Extended TP (Data)";
CM_ BO_ 2563309310 "Extended TP (Command)";
CM_ BO_ 2314732030 "This PGN provides latitude and longitude referenced to WGS84";
CM_ BO_ 2583168510 "This PGN conveys a comprehensive set of Global Navigation Satellite System (GNSS) parameters, including position 
information
";
CM_ SG_ 2583168510 AgeOfDGNSSCorrections1 "Age of Differential corrections";
CM_ SG_ 2583168510 ReferenceStationID1 "Reference Station ID";
CM_ SG_ 2583168510 NumberOfReferenceStations "Numeric count, event counter, sequence counter";
CM_ SG_ 2583168510 GeoidalSeparation "The difference between the earth ellipsoid and mean-sea-level (geoid) defined by the reference datum used in the position solution ' -' = mean-sea-level below ellipsoid
";
CM_ SG_ 2583168510 PDOP "Dilution of Precision (DOP) indicates the contribution of satellite configuration geometry to positioning error
";
CM_ SG_ 2583168510 HDOP "Dilution of Precision (DOP) indicates the contribution of satellite configuration geometry to positioning error
";
CM_ SG_ 2583168510 NumberOfSVs "Numeric count, event counter, sequence counter";
CM_ SG_ 2583168510 Altitude "Altitude referenced to WGS-84";
CM_ SG_ 2583168510 Longitude "Longitude referenced to WGS-84";
CM_ SG_ 2583168510 Latitude "Latitude referenced to WGS-84";
CM_ SG_ 2583168510 PositionTime "24 hour clock, 0 =  midnight,  time is in UTC";
CM_ SG_ 2583168510 PositionDate "Days since January 1, 1970,  Date is relative to UTC Time";
CM_ SG_ 2583168510 SequenceID "An upward counting number used to tie related information together between different PGNs.
";
CM_ BO_ 2583299838 "GNSS pseudorange measurement noise statistics can be translated in the position domain in order to give statistical measures 
of the quality of the position solution. Intended for use with a Receiver Autonomous Integrity Monitoring (RAIM) application.
";
CM_ SG_ 2583299838 STDofAltError "Error distances expressed in meters";
CM_ SG_ 2583299838 STDofLonError "Error distances expressed in meters";
CM_ SG_ 2583299838 STDofLatError "Error distances expressed in meters.";
CM_ SG_ 2583299838 OrientationOfMinorAxis "Degrees clockwise relative to True North.";
CM_ SG_ 2583299838 STDofMinorAxis "Error distances expressed in meters.";
CM_ SG_ 2583299838 STDofMajorAxis "Error distances expressed in meters.";
CM_ SG_ 2583299838 RMSofPositionUncertainty "Error distances expressed in meters.";
CM_ SG_ 2583299838 SequenceID "An upward counting number used to tie related information together between different PGNs.
";
CM_ BO_ 2566849534 "Proprietary B3";
CM_ BO_ 2566849278 "Proprietary B2";
CM_ BO_ 2566849022 "Proprietary B1";
CM_ BO_ 2566848766 "Proprietary B0";
CM_ BO_ 2566842110 "Time/Date";
CM_ SG_ 2566842110 LocalHourOffset "The hour component of the offset between the UTC (Universal Time Coordinate) time and date and a local time zone time ...";
CM_ SG_ 2566842110 LocalMinuteOffset "The minute component of the offset between the UTC time and date and a local time zone time and date.  This is the ...";
CM_ SG_ 2566842110 Day "The day component of the current calendar date.  This should be reported as the day component of the current date at ...";
CM_ SG_ 2566842110 Hours "The hour component of the current time of day.  This should be reported as the hour component of the current time at ...";
CM_ SG_ 2566842110 Minutes "The minutes component of the current time of day.  This should be reported as the minutes component of the current time ...";
CM_ BO_ 2365475326 "Ground-based Speed and Distance";
CM_ BO_ 2365475070 "Wheel-based Speed and Distance";
CM_ SG_ 2365475070 OperatorDirectionReversed "This parameter indicates whether the reported direction is reversed from the perspective of the operator.";
CM_ BO_ 2566801406 "Message sent by any ECU connected to the implement bus requesting that the Tractor ECU not switch off 
the power for 2 s after it has received the wheel-based speed and distance message indicating that the 
ignition has been switched off. ";
CM_ SG_ 2566801406 ImplementInWorkState "Indicates that an implement is connected to a tractor or power unit and is in work state.";
CM_ BO_ 2365474558 "Secondary or Front Hitch Status";
CM_ SG_ 2365474558 FrontHitchExitReasonCode "This parameter is used to indicate why the front hitch cannot accept remote commands or has most recently 
stopped accepting remote commands. ";
CM_ SG_ 2365474558 FrontHitchPositionLimitStatus "Parameter used to report the tractor ECUs present limit status associated with a parameter whose commands are persistent";
CM_ BO_ 2365474302 "Primary or Rear Hitch Status";
CM_ SG_ 2365474302 RearHitchExitReasonCode "This parameter is used to indicate why the rear hitch cannot accept remote commands or has most recently 
stopped accepting remote commands. ";
CM_ SG_ 2365474302 RearHitchPositionLimitStatus "Parameter used to report the tractor ECUs present limit status associated with a parameter whose commands are persistent";
CM_ BO_ 2365474046 "Pprovides the measurement of the current secondary or front power take-off (PTO) output shaft parameters.";
CM_ SG_ 2365474046 FrontPTOExitReasonCode "This parameter is used to indicate why the front PTO cannot accept remote commands or has most recently 
stopped accepting remote commands.";
CM_ SG_ 2365474046 FrontPTOModeRqStatus "Parameter used to report the tractor ECUs status associated with a parameter whose requests are transient.";
CM_ SG_ 2365474046 FrontPTOEconomyModeRqStatus "Parameter used to report the tractor ECUs status associated with a parameter whose requests are transient.";
CM_ SG_ 2365474046 FrontPTOShaftSpeedLimitStatus "Parameter used to report the tractor ECUs present limit status associated with a parameter whose commands are persistent";
CM_ SG_ 2365474046 FrontPTOEngagementRqStatus "Parameter used to report the tractor ECUs status associated with a parameter whose requests are transient.";
CM_ BO_ 2365473790 "Provides the measurement of the current primary or rear power take-off (PTO) output shaft parameters.
";
CM_ SG_ 2365473790 RearPTOExitReasonCode "This parameter is used to indicate why the rear PTO cannot accept remote commands or has most recently 
stopped accepting remote commands.";
CM_ SG_ 2365473790 RearPTOModeRqStatus "Parameter used to report the tractor ECUs status associated with a parameter whose requests are transient.";
CM_ SG_ 2365473790 RearPTOEconomyModeRqStatus "Parameter used to report the tractor ECUs status associated with a parameter whose requests are transient.";
CM_ SG_ 2365473790 RearPTOShaftSpeedLimitStatus "Parameter used to report the tractor ECUs present limit status associated with a parameter whose commands are persistent";
CM_ SG_ 2365473790 RearPTOEngagementRqStatus "Parameter used to report the tractor ECUs status associated with a parameter whose requests are transient.";
CM_ BO_ 2365473534 "Hitch and PTO Commands";
CM_ BO_ 2365473278 "Lighting Command";
CM_ BO_ 2566799614 "Lighting Data";
CM_ BO_ 2365472766 "Auxiliary Valve Command";
CM_ BO_ 2365472510 "Auxiliary Valve Command";
CM_ BO_ 2365472254 "Auxiliary Valve Command";
CM_ BO_ 2365471998 "Auxiliary Valve Command";
CM_ BO_ 2365471742 "Auxiliary Valve Command";
CM_ BO_ 2365471486 "Auxiliary Valve Command";
CM_ BO_ 2365471230 "Auxiliary Valve Command";
CM_ BO_ 2365470974 "Auxiliary Valve Command";
CM_ BO_ 2365470718 "Auxiliary Valve Command";
CM_ BO_ 2365470462 "Auxiliary Valve Command";
CM_ BO_ 2365470206 "Auxiliary Valve Command";
CM_ BO_ 2365469950 "Auxiliary Valve Command";
CM_ BO_ 2365469694 "Auxiliary Valve Command";
CM_ BO_ 2365469438 "Auxiliary Valve Command";
CM_ BO_ 2365469182 "Auxiliary Valve Command";
CM_ BO_ 2365468926 "Auxiliary Valve Command";
CM_ BO_ 2365468670 "Auxiliary valve measured flow";
CM_ SG_ 2365468670 Valve15LimitStatus "Parameter used to report the tractor ECUs present limit status associated with a parameter whose commands are persistent";
CM_ BO_ 2365468414 "Auxiliary valve measured flow";
CM_ SG_ 2365468414 Valve14LimitStatus "Parameter used to report the tractor ECUs present limit status associated with a parameter whose commands are persistent";
CM_ BO_ 2365468158 "Auxiliary valve measured flow";
CM_ SG_ 2365468158 Valve13LimitStatus "Parameter used to report the tractor ECUs present limit status associated with a parameter whose commands are persistent";
CM_ BO_ 2365467902 "Auxiliary valve measured flow";
CM_ SG_ 2365467902 Valve12LimitStatus "Parameter used to report the tractor ECUs present limit status associated with a parameter whose commands are persistent";
CM_ BO_ 2365467646 "Auxiliary valve measured flow";
CM_ SG_ 2365467646 Valve11LimitStatus "Parameter used to report the tractor ECUs present limit status associated with a parameter whose commands are persistent";
CM_ BO_ 2365467390 "Auxiliary valve measured flow";
CM_ SG_ 2365467390 Valve10LimitStatus "Parameter used to report the tractor ECUs present limit status associated with a parameter whose commands are persistent";
CM_ BO_ 2365467134 "Auxiliary valve measured flow";
CM_ SG_ 2365467134 Valve9LimitStatus "Parameter used to report the tractor ECUs present limit status associated with a parameter whose commands are persistent";
CM_ BO_ 2365466878 "Auxiliary valve measured flow";
CM_ SG_ 2365466878 Valve8LimitStatus "Parameter used to report the tractor ECUs present limit status associated with a parameter whose commands are persistent";
CM_ BO_ 2365466622 "Auxiliary valve measured flow";
CM_ SG_ 2365466622 Valve7LimitStatus "Parameter used to report the tractor ECUs present limit status associated with a parameter whose commands are persistent";
CM_ BO_ 2365466366 "Auxiliary valve measured flow";
CM_ SG_ 2365466366 Valve6LimitStatus "Parameter used to report the tractor ECUs present limit status associated with a parameter whose commands are persistent";
CM_ BO_ 2365466110 "Auxiliary valve measured flow";
CM_ SG_ 2365466110 Valve5LimitStatus "Parameter used to report the tractor ECUs present limit status associated with a parameter whose commands are persistent";
CM_ BO_ 2365465854 "Auxiliary valve measured flow";
CM_ SG_ 2365465854 Valve4LimitStatus "Parameter used to report the tractor ECUs present limit status associated with a parameter whose commands are persistent";
CM_ BO_ 2365465598 "Auxiliary valve measured flow";
CM_ SG_ 2365465598 Valve3LimitStatus "Parameter used to report the tractor ECUs present limit status associated with a parameter whose commands are persistent";
CM_ BO_ 2365465342 "Auxiliary valve measured flow";
CM_ SG_ 2365465342 Valve2LimitStatus "Parameter used to report the tractor ECUs present limit status associated with a parameter whose commands are persistent";
CM_ BO_ 2365465086 "Auxiliary valve measured flow";
CM_ SG_ 2365465086 Valve1LimitStatus "Parameter used to report the tractor ECUs present limit status associated with a parameter whose commands are persistent";
CM_ BO_ 2365464830 "Auxiliary valve measured flow";
CM_ SG_ 2365464830 Valve0LimitStatus "Parameter used to report the tractor ECUs present limit status associated with a parameter whose commands are persistent";
CM_ BO_ 2365464574 "Esimated flow of auxiliary valve number 0 ";
CM_ SG_ 2365464574 AuxValve15ExitReasonCode "This parameter is used to indicate why the auxiliary valve 15 cannot accept remote commands or has most 
recently stopped accepting remote commands.";
CM_ SG_ 2365464574 Valve15LimitStatus "Parameter used to report the tractor ECUs present limit status associated with a parameter whose commands are persistent";
CM_ BO_ 2365464318 "Esimated flow of auxiliary valve number 0 ";
CM_ SG_ 2365464318 Valve14LimitStatus "Parameter used to report the tractor ECUs present limit status associated with a parameter whose commands are persistent";
CM_ BO_ 2365464062 "Esimated flow of auxiliary valve number 0 ";
CM_ SG_ 2365464062 Valve13LimitStatus "Parameter used to report the tractor ECUs present limit status associated with a parameter whose commands are persistent";
CM_ BO_ 2365463806 "Esimated flow of auxiliary valve number 0 ";
CM_ SG_ 2365463806 Valve12LimitStatus "Parameter used to report the tractor ECUs present limit status associated with a parameter whose commands are persistent";
CM_ BO_ 2365463550 "Esimated flow of auxiliary valve number 0 ";
CM_ SG_ 2365463550 Valve11LimitStatus "Parameter used to report the tractor ECUs present limit status associated with a parameter whose commands are persistent";
CM_ BO_ 2365463294 "Esimated flow of auxiliary valve number 0 ";
CM_ SG_ 2365463294 Valve10LimitStatus "Parameter used to report the tractor ECUs present limit status associated with a parameter whose commands are persistent";
CM_ BO_ 2365463038 "Esimated flow of auxiliary valve number 0 ";
CM_ SG_ 2365463038 Valve9LimitStatus "Parameter used to report the tractor ECUs present limit status associated with a parameter whose commands are persistent";
CM_ BO_ 2365462782 "Esimated flow of auxiliary valve number 0 ";
CM_ SG_ 2365462782 Valve8LimitStatus "Parameter used to report the tractor ECUs present limit status associated with a parameter whose commands are persistent";
CM_ BO_ 2365462526 "Esimated flow of auxiliary valve number 0 ";
CM_ SG_ 2365462526 Valve7LimitStatus "Parameter used to report the tractor ECUs present limit status associated with a parameter whose commands are persistent";
CM_ BO_ 2365462270 "Esimated flow of auxiliary valve number 0 ";
CM_ SG_ 2365462270 Valve6LimitStatus "Parameter used to report the tractor ECUs present limit status associated with a parameter whose commands are persistent";
CM_ BO_ 2365462014 "Esimated flow of auxiliary valve number 0 ";
CM_ SG_ 2365462014 Valve5LimitStatus "Parameter used to report the tractor ECUs present limit status associated with a parameter whose commands are persistent";
CM_ BO_ 2365461758 "Esimated flow of auxiliary valve number 0 ";
CM_ SG_ 2365461758 Valve4LimitStatus "Parameter used to report the tractor ECUs present limit status associated with a parameter whose commands are persistent";
CM_ BO_ 2365461502 "Esimated flow of auxiliary valve number 0 ";
CM_ SG_ 2365461502 Valve3LimitStatus "Parameter used to report the tractor ECUs present limit status associated with a parameter whose commands are persistent";
CM_ BO_ 2365461246 "Esimated flow of auxiliary valve number 0 ";
CM_ SG_ 2365461246 Valve2LimitStatus "Parameter used to report the tractor ECUs present limit status associated with a parameter whose commands are persistent";
CM_ BO_ 2365460990 "Esimated flow of auxiliary valve number 0 ";
CM_ SG_ 2365460990 Valve1LimitStatus "Parameter used to report the tractor ECUs present limit status associated with a parameter whose commands are persistent";
CM_ BO_ 2365460734 "Esimated flow of auxiliary valve number 0 ";
CM_ SG_ 2365460734 AuxValveNum0ExitReasonCode "This parameter is used to indicate why the auxiliary valve 0 cannot accept remote commands or has most 
recently stopped accepting remote commands.";
CM_ SG_ 2365460734 Valve0LimitStatus "Parameter used to report the tractor ECUs present limit status associated with a parameter whose commands are persistent";
CM_ BO_ 2566787070 "Language Command";
CM_ BO_ 2566786814 "Response for Repetition Rate";
CM_ BO_ 2633895422 "Working Set Master";
CM_ BO_ 2633895166 "Working Set Member";
CM_ BO_ 2365459454 "Tractor control mode command (previously: Implement remote control command)";
BA_DEF_ SG_  "DDI" INT 0 65535;
BA_DEF_ BO_  "SingleFrame" INT 0 1;
BA_DEF_ BO_  "VFrameFormat" ENUM  "StandardCAN","ExtendedCAN","reserved","J1939PG","vector_leerstring";
BA_DEF_ BO_  "GenMsgSendType" ENUM  "cyclic","NotUsed","IfActive","NotUsed","NotUsed","NotUsed","NotUsed","NotUsed","noMsgSendType","vector_leerstring";
BA_DEF_ BO_  "GenMsgCycleTime" INT 0 3600000;
BA_DEF_ BO_  "GenMsgRequestable" INT 0 1;
BA_DEF_ BO_  "GenMsgCycleTimeFast" INT 0 3600000;
BA_DEF_ SG_  "SPN" INT 0 524287;
BA_DEF_ SG_  "GenSigSendType" ENUM  "Cyclic","OnWrite","OnWriteWithRepetition","OnChange","OnChangeWithRepetition","IfActive","IfActiveWithRepetition","NoSigSendType";
BA_DEF_ SG_  "SigType" ENUM  "Default","Range","RangeSigned","ASCII","Discrete","Control","ReferencePGN","DTC","StringDelimiter","StringLength","StringLengthControl","MessageCounter","MessageChecksum";
BA_DEF_ SG_  "GenSigStartValue" INT -2147483648 2147483647;
BA_DEF_ SG_  "SystemSignalLongSymbol" STRING ;
BA_DEF_DEF_  "DDI" 0;
BA_DEF_DEF_  "SingleFrame" 1;
BA_DEF_DEF_  "VFrameFormat" "J1939PG";
BA_DEF_DEF_  "GenMsgSendType" "noMsgSendType";
BA_DEF_DEF_  "GenMsgCycleTime" 0;
BA_DEF_DEF_  "GenMsgRequestable" 1;
BA_DEF_DEF_  "GenMsgCycleTimeFast" 0;
BA_DEF_DEF_  "SPN" 0;
BA_DEF_DEF_  "GenSigSendType" "NoSigSendType";
BA_DEF_DEF_  "SigType" "Default";
BA_DEF_DEF_  "GenSigStartValue" 0;
BA_DEF_DEF_  "SystemSignalLongSymbol" "";
BA_ "GenMsgSendType" BO_ 2314732030 8.51951780093012E-317;
BA_ "GenMsgCycleTime" BO_ 2314732030 100;
BA_ "GenMsgSendType" BO_ 2583168510 8.52390115134002E-317;
BA_ "GenMsgCycleTime" BO_ 2583168510 100;
BA_ "SingleFrame" BO_ 2583168510 0;
BA_ "GenMsgSendType" BO_ 2583299838 8.52558097453588E-317;
BA_ "GenMsgCycleTime" BO_ 2583299838 1000;
BA_ "SingleFrame" BO_ 2583299838 0;
BA_ "GenMsgSendType" BO_ 2566849534 8.52715012702708E-317;
BA_ "GenMsgCycleTime" BO_ 2566849534 100;
BA_ "GenMsgSendType" BO_ 2566849278 8.52871927951827E-317;
BA_ "GenMsgCycleTime" BO_ 2566849278 100;
BA_ "GenMsgSendType" BO_ 2566849022 8.53028843200946E-317;
BA_ "GenMsgCycleTime" BO_ 2566849022 100;
BA_ "GenMsgSendType" BO_ 2566848766 8.53185758450065E-317;
BA_ "GenMsgCycleTime" BO_ 2566848766 100;
BA_ "GenMsgSendType" BO_ 2365475326 8.53594844804822E-317;
BA_ "GenMsgCycleTime" BO_ 2365475326 100;
BA_ "GenMsgSendType" BO_ 2365475070 8.53733973690691E-317;
BA_ "GenMsgCycleTime" BO_ 2365475070 100;
BA_ "GenMsgCycleTime" BO_ 2566801406 100;
BA_ "GenMsgSendType" BO_ 2365474558 8.53967963180561E-317;
BA_ "GenMsgCycleTime" BO_ 2365474558 100;
BA_ "GenMsgSendType" BO_ 2365474302 8.54054523481712E-317;
BA_ "GenMsgCycleTime" BO_ 2365474302 100;
BA_ "GenMsgSendType" BO_ 2365474046 2;
BA_ "GenMsgCycleTime" BO_ 2365474046 100;
BA_ "GenMsgSendType" BO_ 2365473790 2;
BA_ "GenMsgCycleTime" BO_ 2365473790 100;
BA_ "GenMsgSendType" BO_ 2365473534 8.54526850239137E-317;
BA_ "GenMsgCycleTime" BO_ 2365473534 1000;
BA_ "GenMsgCycleTime" BO_ 2365473278 100;
BA_ "GenMsgCycleTime" BO_ 2566799614 100;
BA_ "GenMsgSendType" BO_ 2365472766 8.56219716768047E-317;
BA_ "GenMsgCycleTime" BO_ 2365472766 1000;
BA_ "GenMsgSendType" BO_ 2365472510 8.56296395756282E-317;
BA_ "GenMsgCycleTime" BO_ 2365472510 1000;
BA_ "GenMsgSendType" BO_ 2365472254 8.56373074744516E-317;
BA_ "GenMsgCycleTime" BO_ 2365472254 1000;
BA_ "GenMsgSendType" BO_ 2365471998 8.56449753732751E-317;
BA_ "GenMsgCycleTime" BO_ 2365471998 1000;
BA_ "GenMsgSendType" BO_ 2365471742 8.56526432720985E-317;
BA_ "GenMsgCycleTime" BO_ 2365471742 1000;
BA_ "GenMsgSendType" BO_ 2365471486 8.5660311170922E-317;
BA_ "GenMsgCycleTime" BO_ 2365471486 1000;
BA_ "GenMsgSendType" BO_ 2365471230 8.56679790697454E-317;
BA_ "GenMsgCycleTime" BO_ 2365471230 1000;
BA_ "GenMsgSendType" BO_ 2365470974 8.56756469685689E-317;
BA_ "GenMsgCycleTime" BO_ 2365470974 1000;
BA_ "GenMsgSendType" BO_ 2365470718 8.5683354392644E-317;
BA_ "GenMsgCycleTime" BO_ 2365470718 1000;
BA_ "GenMsgSendType" BO_ 2365470462 8.56910222914675E-317;
BA_ "GenMsgCycleTime" BO_ 2365470462 1000;
BA_ "GenMsgSendType" BO_ 2365470206 8.56986901902909E-317;
BA_ "GenMsgCycleTime" BO_ 2365470206 1000;
BA_ "GenMsgSendType" BO_ 2365469950 8.57063976143661E-317;
BA_ "GenMsgCycleTime" BO_ 2365469950 1000;
BA_ "GenMsgSendType" BO_ 2365469694 8.57140655131895E-317;
BA_ "GenMsgCycleTime" BO_ 2365469694 1000;
BA_ "GenMsgSendType" BO_ 2365469438 8.5721733412013E-317;
BA_ "GenMsgCycleTime" BO_ 2365469438 1000;
BA_ "GenMsgSendType" BO_ 2365469182 8.57294013108364E-317;
BA_ "GenMsgCycleTime" BO_ 2365469182 1000;
BA_ "GenMsgSendType" BO_ 2365468926 8.57370692096599E-317;
BA_ "GenMsgCycleTime" BO_ 2365468926 1000;
BA_ "GenMsgSendType" BO_ 2365468670 8.5746199542795E-317;
BA_ "GenMsgCycleTime" BO_ 2365468670 100;
BA_ "GenMsgSendType" BO_ 2365468414 8.57553298759302E-317;
BA_ "GenMsgCycleTime" BO_ 2365468414 100;
BA_ "GenMsgSendType" BO_ 2365468158 8.5764499734317E-317;
BA_ "GenMsgCycleTime" BO_ 2365468158 100;
BA_ "GenMsgSendType" BO_ 2365467902 8.57736300674521E-317;
BA_ "GenMsgCycleTime" BO_ 2365467902 100;
BA_ "GenMsgSendType" BO_ 2365467646 8.57827604005873E-317;
BA_ "GenMsgCycleTime" BO_ 2365467646 100;
BA_ "GenMsgSendType" BO_ 2365467390 8.57918907337224E-317;
BA_ "GenMsgCycleTime" BO_ 2365467390 100;
BA_ "GenMsgSendType" BO_ 2365467134 8.58010210668576E-317;
BA_ "GenMsgCycleTime" BO_ 2365467134 100;
BA_ "GenMsgSendType" BO_ 2365466878 8.58101513999927E-317;
BA_ "GenMsgCycleTime" BO_ 2365466878 100;
BA_ "GenMsgSendType" BO_ 2365466622 8.58192817331279E-317;
BA_ "GenMsgCycleTime" BO_ 2365466622 100;
BA_ "GenMsgSendType" BO_ 2365466366 8.58284515915147E-317;
BA_ "GenMsgCycleTime" BO_ 2365466366 100;
BA_ "GenMsgSendType" BO_ 2365466110 8.58375819246498E-317;
BA_ "GenMsgCycleTime" BO_ 2365466110 100;
BA_ "GenMsgSendType" BO_ 2365465854 8.5846712257785E-317;
BA_ "GenMsgCycleTime" BO_ 2365465854 100;
BA_ "GenMsgSendType" BO_ 2365465598 8.58558425909201E-317;
BA_ "GenMsgCycleTime" BO_ 2365465598 100;
BA_ "GenMsgSendType" BO_ 2365465342 8.58649729240553E-317;
BA_ "GenMsgCycleTime" BO_ 2365465342 100;
BA_ "GenMsgSendType" BO_ 2365465086 8.58741032571904E-317;
BA_ "GenMsgCycleTime" BO_ 2365465086 100;
BA_ "GenMsgSendType" BO_ 2365464830 8.58832335903256E-317;
BA_ "GenMsgCycleTime" BO_ 2365464830 100;
BA_ "GenMsgSendType" BO_ 2365464574 8.5893154428494E-317;
BA_ "GenMsgCycleTime" BO_ 2365464574 100;
BA_ "GenMsgSendType" BO_ 2365464318 8.59030752666625E-317;
BA_ "GenMsgCycleTime" BO_ 2365464318 100;
BA_ "GenMsgSendType" BO_ 2365464062 8.5912996104831E-317;
BA_ "GenMsgCycleTime" BO_ 2365464062 100;
BA_ "GenMsgSendType" BO_ 2365463806 8.59229169429995E-317;
BA_ "GenMsgCycleTime" BO_ 2365463806 100;
BA_ "GenMsgSendType" BO_ 2365463550 8.5932837781168E-317;
BA_ "GenMsgCycleTime" BO_ 2365463550 100;
BA_ "GenMsgSendType" BO_ 2365463294 8.59427586193365E-317;
BA_ "GenMsgCycleTime" BO_ 2365463294 100;
BA_ "GenMsgSendType" BO_ 2365463038 8.5952679457505E-317;
BA_ "GenMsgCycleTime" BO_ 2365463038 100;
BA_ "GenMsgSendType" BO_ 2365462782 8.59626002956735E-317;
BA_ "GenMsgCycleTime" BO_ 2365462782 100;
BA_ "GenMsgSendType" BO_ 2365462526 8.5972521133842E-317;
BA_ "GenMsgCycleTime" BO_ 2365462526 100;
BA_ "GenMsgSendType" BO_ 2365462270 8.59824419720105E-317;
BA_ "GenMsgCycleTime" BO_ 2365462270 100;
BA_ "GenMsgSendType" BO_ 2365462014 8.5992362810179E-317;
BA_ "GenMsgCycleTime" BO_ 2365462014 100;
BA_ "GenMsgSendType" BO_ 2365461758 8.60022836483475E-317;
BA_ "GenMsgCycleTime" BO_ 2365461758 100;
BA_ "GenMsgSendType" BO_ 2365461502 8.60122044865159E-317;
BA_ "GenMsgCycleTime" BO_ 2365461502 100;
BA_ "GenMsgSendType" BO_ 2365461246 8.60221253246844E-317;
BA_ "GenMsgCycleTime" BO_ 2365461246 100;
BA_ "GenMsgSendType" BO_ 2365460990 8.60320856881046E-317;
BA_ "GenMsgCycleTime" BO_ 2365460990 100;
BA_ "GenMsgSendType" BO_ 2365460734 8.60420065262731E-317;
BA_ "GenMsgCycleTime" BO_ 2365460734 100;
BA_ "GenMsgCycleTime" BO_ 2566787070 100;
BA_ "GenMsgCycleTime" BO_ 2566786814 100;
BA_ "GenMsgSendType" BO_ 2365459454 8.61276577466361E-317;
BA_ "GenMsgCycleTime" BO_ 2365459454 100;
BA_ "SigType" SG_ 2628452094 VI_VolumeName 9;
BA_ "SigType" SG_ 2628452094 OF_PathName 9;
BA_ "SigType" SG_ 2628452094 DF_PathName 9;
BA_ "SigType" SG_ 2628452094 SA_PathName 9;
BA_ "SigType" SG_ 2628452094 CCD_PathName 9;
BA_ "SigType" SG_ 2628452094 GA_PathName 9;
BA_ "SigType" SG_ 2628452094 FDT_PathName 9;
BA_ "SigType" SG_ 2628452094 VS_VolumeName 8;
BA_ "SystemSignalLongSymbol" SG_ 2628452094 VS_RequestVolumeToPrepareForRemo "VS_RequestVolumeToPrepareForRemoval";
BA_ "SigType" SG_ 2628517630 GCD_PathName 9;
BA_ "SigType" SG_ 2628517630 VS_VolumeName 9;
BA_ "SPN" SG_ 2364540158 EngDemandPercentTorque 2432;
BA_ "SigType" SG_ 2364540158 EngDemandPercentTorque 1;
BA_ "SPN" SG_ 2364540158 EngStarterMode 1675;
BA_ "SPN" SG_ 2364540158 SrcAddrssOfCtrllngDvcForEngCtrl 1483;
BA_ "SPN" SG_ 2364540158 EngSpeed 190;
BA_ "SigType" SG_ 2364540158 EngSpeed 1;
BA_ "SPN" SG_ 2364540158 ActualEngPercentTorque 513;
BA_ "SigType" SG_ 2364540158 ActualEngPercentTorque 1;
BA_ "SPN" SG_ 2364540158 DriversDemandEngPercentTorque 512;
BA_ "SigType" SG_ 2364540158 DriversDemandEngPercentTorque 1;
BA_ "SPN" SG_ 2364540158 EngTorqueMode 899;
BA_ "SPN" SG_ 2364540158 ActlEngPrcntTorqueHighResolution 4154;
BA_ "SigType" SG_ 2563243774 Byte7 1;
BA_ "SigType" SG_ 2563243774 Byte6 1;
BA_ "SigType" SG_ 2563243774 Byte5 1;
BA_ "SigType" SG_ 2563243774 Byte4 1;
BA_ "SigType" SG_ 2563243774 Byte3 1;
BA_ "SigType" SG_ 2563243774 Byte2 1;
BA_ "SigType" SG_ 2563243774 Byte1 1;
BA_ "SigType" SG_ 2563243774 SequenceNumber 1;
BA_ "GenSigStartValue" SG_ 2563243774 SequenceNumber 1;
BA_ "SigType" SG_ 2563309310 PGNumber 6;
BA_ "SigType" SG_ 2563309310 DataPacketOffset 1;
BA_ "SigType" SG_ 2563309310 NextPacketNumberToSend 1;
BA_ "GenSigStartValue" SG_ 2563309310 NextPacketNumberToSend 1;
BA_ "SigType" SG_ 2563309310 NumberOfBytesTransfered 1;
BA_ "GenSigStartValue" SG_ 2563309310 NumberOfBytesTransfered 1786;
BA_ "SigType" SG_ 2563309310 NumberOfPacketsOffset 1;
BA_ "GenSigStartValue" SG_ 2563309310 NumberOfPacketsOffset 1;
BA_ "SigType" SG_ 2563309310 NumberOfPacketsToSend 1;
BA_ "GenSigStartValue" SG_ 2563309310 NumberOfPacketsToSend 1;
BA_ "SigType" SG_ 2563309310 NumberOfBytesToTransfer 1;
BA_ "GenSigStartValue" SG_ 2563309310 NumberOfBytesToTransfer 1786;
BA_ "SigType" SG_ 2563309310 ControlByte 1;
BA_ "SigType" SG_ 2583168510 AgeOfDGNSSCorrections1 1;
BA_ "SigType" SG_ 2583168510 ReferenceStationID1 1;
BA_ "SigType" SG_ 2583168510 NumberOfReferenceStations 1;
BA_ "SigType" SG_ 2583168510 GeoidalSeparation 2;
BA_ "SigType" SG_ 2583168510 PDOP 2;
BA_ "SigType" SG_ 2583168510 HDOP 2;
BA_ "SigType" SG_ 2583168510 NumberOfSVs 1;
BA_ "SigType" SG_ 2583168510 GNSSIntegrity 4;
BA_ "SigType" SG_ 2583168510 PositionTime 1;
BA_ "SigType" SG_ 2583168510 PositionDate 1;
BA_ "SigType" SG_ 2583168510 SequenceID 1;
BA_ "SigType" SG_ 2583299838 STDofAltError 1;
BA_ "SigType" SG_ 2583299838 STDofLonError 1;
BA_ "SigType" SG_ 2583299838 STDofLatError 1;
BA_ "SigType" SG_ 2583299838 OrientationOfMinorAxis 1;
BA_ "SigType" SG_ 2583299838 STDofMinorAxis 1;
BA_ "SigType" SG_ 2583299838 STDofMajorAxis 1;
BA_ "SigType" SG_ 2583299838 RMSofPositionUncertainty 1;
BA_ "SigType" SG_ 2583299838 SequenceID 1;
BA_ "SigType" SG_ 2566849534 ManufacturerSpecific8 1;
BA_ "SigType" SG_ 2566849534 ManufacturerSpecific7 1;
BA_ "SigType" SG_ 2566849534 ManufacturerSpecific6 1;
BA_ "SigType" SG_ 2566849534 ManufacturerSpecific5 1;
BA_ "SigType" SG_ 2566849534 ManufacturerSpecific4 1;
BA_ "SigType" SG_ 2566849534 ManufacturerSpecific3 1;
BA_ "SigType" SG_ 2566849534 ManufacturerSpecific2 1;
BA_ "SigType" SG_ 2566849534 ManufacturerSpecific1 1;
BA_ "SigType" SG_ 2566849278 ManufacturerSpecific8 1;
BA_ "SigType" SG_ 2566849278 ManufacturerSpecific7 1;
BA_ "SigType" SG_ 2566849278 ManufacturerSpecific6 1;
BA_ "SigType" SG_ 2566849278 ManufacturerSpecific5 1;
BA_ "SigType" SG_ 2566849278 ManufacturerSpecific4 1;
BA_ "SigType" SG_ 2566849278 ManufacturerSpecific3 1;
BA_ "SigType" SG_ 2566849278 ManufacturerSpecific2 1;
BA_ "SigType" SG_ 2566849278 ManufacturerSpecific1 1;
BA_ "SigType" SG_ 2566849022 ManufacturerSpecific8 1;
BA_ "SigType" SG_ 2566849022 ManufacturerSpecific7 1;
BA_ "SigType" SG_ 2566849022 ManufacturerSpecific6 1;
BA_ "SigType" SG_ 2566849022 ManufacturerSpecific5 1;
BA_ "SigType" SG_ 2566849022 ManufacturerSpecific4 1;
BA_ "SigType" SG_ 2566849022 ManufacturerSpecific3 1;
BA_ "SigType" SG_ 2566849022 ManufacturerSpecific2 1;
BA_ "SigType" SG_ 2566849022 ManufacturerSpecific1 1;
BA_ "SigType" SG_ 2566848766 ManufacturerSpecific8 1;
BA_ "SigType" SG_ 2566848766 ManufacturerSpecific7 1;
BA_ "SigType" SG_ 2566848766 ManufacturerSpecific6 1;
BA_ "SigType" SG_ 2566848766 ManufacturerSpecific5 1;
BA_ "SigType" SG_ 2566848766 ManufacturerSpecific4 1;
BA_ "SigType" SG_ 2566848766 ManufacturerSpecific3 1;
BA_ "SigType" SG_ 2566848766 ManufacturerSpecific2 1;
BA_ "SigType" SG_ 2566848766 ManufacturerSpecific1 1;
BA_ "SigType" SG_ 2566842110 LocalHourOffset 1;
BA_ "SPN" SG_ 2566842110 LocalHourOffset 1602;
BA_ "SigType" SG_ 2566842110 LocalMinuteOffset 1;
BA_ "SPN" SG_ 2566842110 LocalMinuteOffset 1601;
BA_ "SigType" SG_ 2566842110 Year 1;
BA_ "SPN" SG_ 2566842110 Year 964;
BA_ "SigType" SG_ 2566842110 Day 1;
BA_ "SPN" SG_ 2566842110 Day 962;
BA_ "SigType" SG_ 2566842110 Month 1;
BA_ "SPN" SG_ 2566842110 Month 963;
BA_ "SigType" SG_ 2566842110 Hours 1;
BA_ "SPN" SG_ 2566842110 Hours 961;
BA_ "SigType" SG_ 2566842110 Minutes 1;
BA_ "SPN" SG_ 2566842110 Minutes 960;
BA_ "SigType" SG_ 2566842110 Seconds 1;
BA_ "SPN" SG_ 2566842110 Seconds 959;
BA_ "SigType" SG_ 2365475326 GroundBasedMachineDirection 4;
BA_ "SPN" SG_ 2365475326 GroundBasedMachineDirection 1861;
BA_ "SigType" SG_ 2365475326 GroundBasedMachineDistance 1;
BA_ "SPN" SG_ 2365475326 GroundBasedMachineDistance 1860;
BA_ "SigType" SG_ 2365475326 GroundBasedMachineSpeed 1;
BA_ "SPN" SG_ 2365475326 GroundBasedMachineSpeed 1859;
BA_ "SigType" SG_ 2365475070 OperatorDirectionReversed 5;
BA_ "SPN" SG_ 2365475070 OperatorDirectionReversed 5244;
BA_ "SigType" SG_ 2365475070 StartStopState 4;
BA_ "SPN" SG_ 2365475070 StartStopState 5203;
BA_ "SigType" SG_ 2365475070 KeySwitchState 4;
BA_ "SPN" SG_ 2365475070 KeySwitchState 1865;
BA_ "SigType" SG_ 2365475070 WheelBasedMachineDirection 4;
BA_ "SPN" SG_ 2365475070 WheelBasedMachineDirection 1864;
BA_ "SigType" SG_ 2365475070 MaxTimeOfTractorPower 1;
BA_ "SPN" SG_ 2365475070 MaxTimeOfTractorPower 1866;
BA_ "SigType" SG_ 2365475070 WheelBasedMachineDistance 1;
BA_ "SPN" SG_ 2365475070 WheelBasedMachineDistance 1863;
BA_ "SigType" SG_ 2365475070 WheelBasedMachineSpeed 1;
BA_ "SPN" SG_ 2365475070 WheelBasedMachineSpeed 1862;
BA_ "SPN" SG_ 2566801406 ImplementInWorkState 7447;
BA_ "SigType" SG_ 2566801406 ImplementInWorkState 4;
BA_ "SigType" SG_ 2566801406 ImplementTransportState 4;
BA_ "SPN" SG_ 2566801406 ImplementTransportState 1869;
BA_ "SigType" SG_ 2566801406 ImplementParkState 4;
BA_ "SPN" SG_ 2566801406 ImplementParkState 1870;
BA_ "SigType" SG_ 2566801406 ImplementReadyToWorkState 4;
BA_ "SPN" SG_ 2566801406 ImplementReadyToWorkState 1871;
BA_ "SigType" SG_ 2566801406 MaintainECUPower 4;
BA_ "SPN" SG_ 2566801406 MaintainECUPower 1867;
BA_ "SigType" SG_ 2566801406 MaintainActuatorPower 4;
BA_ "SPN" SG_ 2566801406 MaintainActuatorPower 1868;
BA_ "SPN" SG_ 2365474558 FrontHitchExitReasonCode 5816;
BA_ "SigType" SG_ 2365474558 FrontDraft 1;
BA_ "SPN" SG_ 2365474558 FrontDraft 1878;
BA_ "SigType" SG_ 2365474558 FrontNominalLowerLinkForce 1;
BA_ "SPN" SG_ 2365474558 FrontNominalLowerLinkForce 1880;
BA_ "SigType" SG_ 2365474558 FrontHitchInWorkIndication 4;
BA_ "SPN" SG_ 2365474558 FrontHitchInWorkIndication 1876;
BA_ "SPN" SG_ 2365474558 FrontHitchPositionLimitStatus 5150;
BA_ "SigType" SG_ 2365474558 FrontHitchPosition 1;
BA_ "SPN" SG_ 2365474558 FrontHitchPosition 1872;
BA_ "SPN" SG_ 2365474302 RearHitchExitReasonCode 5819;
BA_ "SigType" SG_ 2365474302 RearDraft 1;
BA_ "SPN" SG_ 2365474302 RearDraft 1879;
BA_ "SigType" SG_ 2365474302 RearNominalPowerLinkForce 1;
BA_ "SPN" SG_ 2365474302 RearNominalPowerLinkForce 1881;
BA_ "SigType" SG_ 2365474302 RearHitchInWorkIndication 4;
BA_ "SPN" SG_ 2365474302 RearHitchInWorkIndication 1877;
BA_ "SPN" SG_ 2365474302 RearHitchPositionLimitStatus 5151;
BA_ "SigType" SG_ 2365474302 RearHitchPosition 1;
BA_ "SPN" SG_ 2365474302 RearHitchPosition 1873;
BA_ "SPN" SG_ 2365474046 FrontPTOExitReasonCode 5817;
BA_ "SigType" SG_ 2365474046 FrontPTOModeRqStatus 4;
BA_ "SPN" SG_ 2365474046 FrontPTOModeRqStatus 5153;
BA_ "SigType" SG_ 2365474046 FrontPTOEconomyModeRqStatus 4;
BA_ "SPN" SG_ 2365474046 FrontPTOEconomyModeRqStatus 5154;
BA_ "SPN" SG_ 2365474046 FrontPTOShaftSpeedLimitStatus 5155;
BA_ "SigType" SG_ 2365474046 FrontPTOEngagement 4;
BA_ "SPN" SG_ 2365474046 FrontPTOEngagement 1888;
BA_ "SigType" SG_ 2365474046 FrontPTOMode 4;
BA_ "SPN" SG_ 2365474046 FrontPTOMode 1889;
BA_ "SigType" SG_ 2365474046 FrontPTOEconomyMode 4;
BA_ "SPN" SG_ 2365474046 FrontPTOEconomyMode 1891;
BA_ "SigType" SG_ 2365474046 FrontPTOEngagementRqStatus 4;
BA_ "SPN" SG_ 2365474046 FrontPTOEngagementRqStatus 5152;
BA_ "SigType" SG_ 2365474046 FrontPTOOutShaftSpeedSetPoint 1;
BA_ "SPN" SG_ 2365474046 FrontPTOOutShaftSpeedSetPoint 1884;
BA_ "SigType" SG_ 2365474046 FrontPTOOutShaftSpeed 1;
BA_ "SPN" SG_ 2365474046 FrontPTOOutShaftSpeed 1882;
BA_ "SPN" SG_ 2365473790 RearPTOExitReasonCode 5820;
BA_ "SigType" SG_ 2365473790 RearPTOModeRqStatus 4;
BA_ "SPN" SG_ 2365473790 RearPTOModeRqStatus 5157;
BA_ "SigType" SG_ 2365473790 RearPTOEconomyModeRqStatus 4;
BA_ "SPN" SG_ 2365473790 RearPTOEconomyModeRqStatus 5158;
BA_ "SPN" SG_ 2365473790 RearPTOShaftSpeedLimitStatus 5159;
BA_ "SigType" SG_ 2365473790 RearPTOEngagement 4;
BA_ "SPN" SG_ 2365473790 RearPTOEngagement 2408;
BA_ "SigType" SG_ 2365473790 RearPTOMode 4;
BA_ "SPN" SG_ 2365473790 RearPTOMode 1890;
BA_ "SigType" SG_ 2365473790 RearPTOEconomyMode 4;
BA_ "SPN" SG_ 2365473790 RearPTOEconomyMode 1892;
BA_ "SigType" SG_ 2365473790 RearPTOEngagementRqStatus 4;
BA_ "SPN" SG_ 2365473790 RearPTOEngagementRqStatus 5156;
BA_ "SigType" SG_ 2365473790 RearPTOOutputShaftSpeedSetPoint 1;
BA_ "SPN" SG_ 2365473790 RearPTOOutputShaftSpeedSetPoint 1885;
BA_ "SigType" SG_ 2365473790 RearPTOOutputShaftSpeed 1;
BA_ "SPN" SG_ 2365473790 RearPTOOutputShaftSpeed 1883;
BA_ "SigType" SG_ 2365473534 FrontPTOModeCmd 4;
BA_ "SPN" SG_ 2365473534 FrontPTOModeCmd 1895;
BA_ "SigType" SG_ 2365473534 RearPTOModeCmd 4;
BA_ "SPN" SG_ 2365473534 RearPTOModeCmd 1896;
BA_ "SigType" SG_ 2365473534 FrontPTOEconomyModeCmd 4;
BA_ "SPN" SG_ 2365473534 FrontPTOEconomyModeCmd 1897;
BA_ "SigType" SG_ 2365473534 RearPTOEconomyModeCmd 4;
BA_ "SPN" SG_ 2365473534 RearPTOEconomyModeCmd 1898;
BA_ "SigType" SG_ 2365473534 FrontPTOEngagementCmd 4;
BA_ "SPN" SG_ 2365473534 FrontPTOEngagementCmd 1893;
BA_ "SigType" SG_ 2365473534 RearPTOEngagementCmd 4;
BA_ "SPN" SG_ 2365473534 RearPTOEngagementCmd 1894;
BA_ "SigType" SG_ 2365473534 RearPTOOutShaftSpeedSetPointCmd 1;
BA_ "SPN" SG_ 2365473534 RearPTOOutShaftSpeedSetPointCmd 1887;
BA_ "SigType" SG_ 2365473534 FrontPTOOutShaftSpeedSetPointCmd 1;
BA_ "SPN" SG_ 2365473534 FrontPTOOutShaftSpeedSetPointCmd 1886;
BA_ "SigType" SG_ 2365473534 RearHitchPositionCmd 1;
BA_ "SPN" SG_ 2365473534 RearHitchPositionCmd 1875;
BA_ "SigType" SG_ 2365473534 FrontHitchPositionCmd 1;
BA_ "SPN" SG_ 2365473534 FrontHitchPositionCmd 1874;
BA_ "SPN" SG_ 2365473278 ImplementRearWorkLightCmd 2405;
BA_ "SigType" SG_ 2365473278 ImplementRearWorkLightCmd 4;
BA_ "SPN" SG_ 2365473278 ImplementLeftFacingWorkLightCmd 2399;
BA_ "SigType" SG_ 2365473278 ImplementLeftFacingWorkLightCmd 4;
BA_ "SPN" SG_ 2365473278 ImplementRightFacingWorkLightCmd 2401;
BA_ "SigType" SG_ 2365473278 ImplementRightFacingWorkLightCmd 4;
BA_ "SPN" SG_ 2365473278 LightingDataRequestCmd 2393;
BA_ "SigType" SG_ 2365473278 LightingDataRequestCmd 4;
BA_ "SPN" SG_ 2365473278 ImplementLeftForwardLightCmd 2597;
BA_ "SigType" SG_ 2365473278 ImplementLeftForwardLightCmd 4;
BA_ "SPN" SG_ 2365473278 ImplementRightForwardLightCmd 2406;
BA_ "SigType" SG_ 2365473278 ImplementRightForwardLightCmd 4;
BA_ "SPN" SG_ 2365473278 ImplementOEMOption1LightCmd 2395;
BA_ "SigType" SG_ 2365473278 ImplementOEMOption1LightCmd 4;
BA_ "SPN" SG_ 2365473278 ImplementOEMOption2LightCmd 2397;
BA_ "SigType" SG_ 2365473278 ImplementOEMOption2LightCmd 4;
BA_ "SPN" SG_ 2365473278 TractorFrontHighWorkLightCmd 2355;
BA_ "SigType" SG_ 2365473278 TractorFrontHighWorkLightCmd 4;
BA_ "SPN" SG_ 2365473278 TractorFrontLowWorkLightCmd 2353;
BA_ "SigType" SG_ 2365473278 TractorFrontLowWorkLightCmd 4;
BA_ "SPN" SG_ 2365473278 TractorSideHighWorkLightCmd 2365;
BA_ "SigType" SG_ 2365473278 TractorSideHighWorkLightCmd 4;
BA_ "SPN" SG_ 2365473278 TractorSideLowWorkLightCmd 2363;
BA_ "SigType" SG_ 2365473278 TractorSideLowWorkLightCmd 4;
BA_ "SPN" SG_ 2365473278 TractorRearHighWorkLightCmd 2361;
BA_ "SigType" SG_ 2365473278 TractorRearHighWorkLightCmd 4;
BA_ "SPN" SG_ 2365473278 TractorRearLowWorkLightCmd 2359;
BA_ "SigType" SG_ 2365473278 TractorRearLowWorkLightCmd 4;
BA_ "SPN" SG_ 2365473278 TractorUndersideWorkLightCmd 2357;
BA_ "SigType" SG_ 2365473278 TractorUndersideWorkLightCmd 4;
BA_ "SPN" SG_ 2365473278 RearFogLightCmd 2389;
BA_ "SigType" SG_ 2365473278 RearFogLightCmd 4;
BA_ "SPN" SG_ 2365473278 TractorMarkerLightCmd 2377;
BA_ "SigType" SG_ 2365473278 TractorMarkerLightCmd 4;
BA_ "SPN" SG_ 2365473278 ImplementMarkerLightCmd 2379;
BA_ "SigType" SG_ 2365473278 ImplementMarkerLightCmd 4;
BA_ "SPN" SG_ 2365473278 TractorClearanceLightCmd 2381;
BA_ "SigType" SG_ 2365473278 TractorClearanceLightCmd 4;
BA_ "SPN" SG_ 2365473278 ImplementClearanceLightCmd 2383;
BA_ "SigType" SG_ 2365473278 ImplementClearanceLightCmd 4;
BA_ "SPN" SG_ 2365473278 LeftStopLightCmd 2371;
BA_ "SigType" SG_ 2365473278 LeftStopLightCmd 4;
BA_ "SPN" SG_ 2365473278 RightStopLightCmd 2373;
BA_ "SigType" SG_ 2365473278 RightStopLightCmd 4;
BA_ "SPN" SG_ 2365473278 CentreStopLightCmd 2375;
BA_ "SigType" SG_ 2365473278 CentreStopLightCmd 4;
BA_ "SPN" SG_ 2365473278 BackUpLightAndAlarmHornCmd 2391;
BA_ "SigType" SG_ 2365473278 BackUpLightAndAlarmHornCmd 4;
BA_ "SPN" SG_ 2365473278 LeftTurnSignalLightCmd 2367;
BA_ "SigType" SG_ 2365473278 LeftTurnSignalLightCmd 4;
BA_ "SPN" SG_ 2365473278 RightTurnSignalLightCmd 2369;
BA_ "SigType" SG_ 2365473278 RightTurnSignalLightCmd 4;
BA_ "SPN" SG_ 2365473278 RotatingBeaconLightCmd 2385;
BA_ "SigType" SG_ 2365473278 RotatingBeaconLightCmd 4;
BA_ "SPN" SG_ 2365473278 TractorFrontFogLightCmd 2387;
BA_ "SigType" SG_ 2365473278 TractorFrontFogLightCmd 4;
BA_ "SPN" SG_ 2365473278 HighBeamHeadLightCmd 2347;
BA_ "SigType" SG_ 2365473278 HighBeamHeadLightCmd 4;
BA_ "SPN" SG_ 2365473278 LowBeamHeadLightCmd 2349;
BA_ "SigType" SG_ 2365473278 LowBeamHeadLightCmd 4;
BA_ "SPN" SG_ 2365473278 AlternateHeadLightCmd 2351;
BA_ "SigType" SG_ 2365473278 AlternateHeadLightCmd 4;
BA_ "SPN" SG_ 2365473278 DaytimeRunningLightCmd 2403;
BA_ "SigType" SG_ 2365473278 DaytimeRunningLightCmd 4;
BA_ "SPN" SG_ 2566799614 ImplementRearWorkLightData 2394;
BA_ "SigType" SG_ 2566799614 ImplementRearWorkLightData 4;
BA_ "SPN" SG_ 2566799614 ImplLeftFacingWorkLightData 2400;
BA_ "SigType" SG_ 2566799614 ImplLeftFacingWorkLightData 4;
BA_ "SPN" SG_ 2566799614 ImplRightFacingWorkLightData 2402;
BA_ "SigType" SG_ 2566799614 ImplRightFacingWorkLightData 4;
BA_ "SPN" SG_ 2566799614 ImplementLeftForwardLightData 2598;
BA_ "SigType" SG_ 2566799614 ImplementLeftForwardLightData 4;
BA_ "SPN" SG_ 2566799614 ImplementRightForwardLightData 2407;
BA_ "SigType" SG_ 2566799614 ImplementRightForwardLightData 4;
BA_ "SPN" SG_ 2566799614 ImplementOEMOption1LightData 2396;
BA_ "SigType" SG_ 2566799614 ImplementOEMOption1LightData 4;
BA_ "SPN" SG_ 2566799614 ImplementOEMOption2LightData 2398;
BA_ "SigType" SG_ 2566799614 ImplementOEMOption2LightData 4;
BA_ "SPN" SG_ 2566799614 TractorFrontHighWorkLightData 2356;
BA_ "SigType" SG_ 2566799614 TractorFrontHighWorkLightData 4;
BA_ "SPN" SG_ 2566799614 TractorFrontLowWorkLightData 2354;
BA_ "SigType" SG_ 2566799614 TractorFrontLowWorkLightData 4;
BA_ "SPN" SG_ 2566799614 TractorSideHighWorkLightData 2366;
BA_ "SigType" SG_ 2566799614 TractorSideHighWorkLightData 4;
BA_ "SPN" SG_ 2566799614 TractorSideLowWorkLightData 2364;
BA_ "SigType" SG_ 2566799614 TractorSideLowWorkLightData 4;
BA_ "SPN" SG_ 2566799614 TractorRearHighWorkLightData 2362;
BA_ "SigType" SG_ 2566799614 TractorRearHighWorkLightData 4;
BA_ "SPN" SG_ 2566799614 TractorRearLowWorkLightData 2360;
BA_ "SigType" SG_ 2566799614 TractorRearLowWorkLightData 4;
BA_ "SPN" SG_ 2566799614 TractorUndersideWorkLightData 2358;
BA_ "SigType" SG_ 2566799614 TractorUndersideWorkLightData 4;
BA_ "SPN" SG_ 2566799614 RearFogLightData 2390;
BA_ "SigType" SG_ 2566799614 RearFogLightData 4;
BA_ "SPN" SG_ 2566799614 TractorMarkerLightData 2378;
BA_ "SigType" SG_ 2566799614 TractorMarkerLightData 4;
BA_ "SPN" SG_ 2566799614 ImplementMarkerLightData 2380;
BA_ "SigType" SG_ 2566799614 ImplementMarkerLightData 4;
BA_ "SPN" SG_ 2566799614 TractorClearanceLightData 2382;
BA_ "SigType" SG_ 2566799614 TractorClearanceLightData 4;
BA_ "SPN" SG_ 2566799614 ImplementClearanceLightData 2384;
BA_ "SigType" SG_ 2566799614 ImplementClearanceLightData 4;
BA_ "SPN" SG_ 2566799614 LefttStopLightData 2372;
BA_ "SigType" SG_ 2566799614 LefttStopLightData 4;
BA_ "SPN" SG_ 2566799614 RightStopLightData 2374;
BA_ "SigType" SG_ 2566799614 RightStopLightData 4;
BA_ "SPN" SG_ 2566799614 CentreStopLightData 2376;
BA_ "SigType" SG_ 2566799614 CentreStopLightData 4;
BA_ "SPN" SG_ 2566799614 BackUpLightAndAlarmHornData 2392;
BA_ "SigType" SG_ 2566799614 BackUpLightAndAlarmHornData 4;
BA_ "SPN" SG_ 2566799614 LeftTurnSignalLightData 2368;
BA_ "SigType" SG_ 2566799614 LeftTurnSignalLightData 4;
BA_ "SPN" SG_ 2566799614 RightTurnSignalLightData 2370;
BA_ "SigType" SG_ 2566799614 RightTurnSignalLightData 4;
BA_ "SPN" SG_ 2566799614 RotationBeaconLightData 2386;
BA_ "SigType" SG_ 2566799614 RotationBeaconLightData 4;
BA_ "SPN" SG_ 2566799614 TractorFrontFogLightData 2388;
BA_ "SigType" SG_ 2566799614 TractorFrontFogLightData 4;
BA_ "SPN" SG_ 2566799614 HighBeamHeadLightData 2348;
BA_ "SigType" SG_ 2566799614 HighBeamHeadLightData 4;
BA_ "SPN" SG_ 2566799614 LowBeamHeadLightData 2350;
BA_ "SigType" SG_ 2566799614 LowBeamHeadLightData 4;
BA_ "SPN" SG_ 2566799614 AlternateHeadLightData 2352;
BA_ "SigType" SG_ 2566799614 AlternateHeadLightData 4;
BA_ "SPN" SG_ 2566799614 DaytimeRunningLightData 2404;
BA_ "SigType" SG_ 2566799614 DaytimeRunningLightData 4;
BA_ "SPN" SG_ 2365472766 Valve15FailSaveModeCmd 2345;
BA_ "SigType" SG_ 2365472766 Valve15FailSaveModeCmd 4;
BA_ "SPN" SG_ 2365472766 Valve15StateCmd 2344;
BA_ "SPN" SG_ 2365472766 Valve15PortFlowCmd 2343;
BA_ "SigType" SG_ 2365472766 Valve15PortFlowCmd 1;
BA_ "SPN" SG_ 2365472510 Valve14FailSaveModeCmd 2333;
BA_ "SigType" SG_ 2365472510 Valve14FailSaveModeCmd 4;
BA_ "SPN" SG_ 2365472510 Valve14StateCmd 2332;
BA_ "SPN" SG_ 2365472510 Valve14PortFlowCmd 2331;
BA_ "SigType" SG_ 2365472510 Valve14PortFlowCmd 1;
BA_ "SPN" SG_ 2365472254 Valve13FailSaveModeCmd 2321;
BA_ "SigType" SG_ 2365472254 Valve13FailSaveModeCmd 4;
BA_ "SPN" SG_ 2365472254 Valve13StateCmd 2320;
BA_ "SPN" SG_ 2365472254 Valve13PortFlowCmd 2319;
BA_ "SigType" SG_ 2365472254 Valve13PortFlowCmd 1;
BA_ "SPN" SG_ 2365471998 Valve12FailSaveModeCmd 2309;
BA_ "SigType" SG_ 2365471998 Valve12FailSaveModeCmd 4;
BA_ "SPN" SG_ 2365471998 Valve12StateCmd 2308;
BA_ "SPN" SG_ 2365471998 Valve12PortFlowCmd 2307;
BA_ "SigType" SG_ 2365471998 Valve12PortFlowCmd 1;
BA_ "SPN" SG_ 2365471742 Valve11FailSaveModeCmd 2297;
BA_ "SigType" SG_ 2365471742 Valve11FailSaveModeCmd 4;
BA_ "SPN" SG_ 2365471742 Valve11StateCmd 2296;
BA_ "SPN" SG_ 2365471742 Valve11PortFlowCmd 2295;
BA_ "SigType" SG_ 2365471742 Valve11PortFlowCmd 1;
BA_ "SPN" SG_ 2365471486 Valve10FailSaveModeCmd 2285;
BA_ "SigType" SG_ 2365471486 Valve10FailSaveModeCmd 4;
BA_ "SPN" SG_ 2365471486 Valve10StateCmd 2284;
BA_ "SPN" SG_ 2365471486 Valve10PortFlowCmd 2283;
BA_ "SigType" SG_ 2365471486 Valve10PortFlowCmd 1;
BA_ "SPN" SG_ 2365471230 Valve9FailSaveModeCmd 2273;
BA_ "SigType" SG_ 2365471230 Valve9FailSaveModeCmd 4;
BA_ "SPN" SG_ 2365471230 Valve9StateCmd 2272;
BA_ "SPN" SG_ 2365471230 Valve9PortFlowCmd 2271;
BA_ "SigType" SG_ 2365471230 Valve9PortFlowCmd 1;
BA_ "SPN" SG_ 2365470974 Valve8FailSaveModeCmd 2261;
BA_ "SigType" SG_ 2365470974 Valve8FailSaveModeCmd 4;
BA_ "SPN" SG_ 2365470974 Valve8StateCmd 2260;
BA_ "SPN" SG_ 2365470974 Valve8PortFlowCmd 2259;
BA_ "SigType" SG_ 2365470974 Valve8PortFlowCmd 1;
BA_ "SPN" SG_ 2365470718 Valve7FailSaveModeCmd 1993;
BA_ "SigType" SG_ 2365470718 Valve7FailSaveModeCmd 4;
BA_ "SPN" SG_ 2365470718 Valve7StateCmd 1992;
BA_ "SPN" SG_ 2365470718 Valve7PortFlowCmd 1991;
BA_ "SigType" SG_ 2365470718 Valve7PortFlowCmd 1;
BA_ "SPN" SG_ 2365470462 Valve6FailSaveModeCmd 1981;
BA_ "SigType" SG_ 2365470462 Valve6FailSaveModeCmd 4;
BA_ "SPN" SG_ 2365470462 Valve6StateCmd 1980;
BA_ "SPN" SG_ 2365470462 Valve6PortFlowCmd 1979;
BA_ "SigType" SG_ 2365470462 Valve6PortFlowCmd 1;
BA_ "SPN" SG_ 2365470206 Valve5FailSaveModeCmd 1969;
BA_ "SigType" SG_ 2365470206 Valve5FailSaveModeCmd 4;
BA_ "SPN" SG_ 2365470206 Valve5StateCmd 1968;
BA_ "SPN" SG_ 2365470206 Valve5PortFlowCmd 1967;
BA_ "SigType" SG_ 2365470206 Valve5PortFlowCmd 1;
BA_ "SPN" SG_ 2365469950 Valve4FailSaveModeCmd 1957;
BA_ "SigType" SG_ 2365469950 Valve4FailSaveModeCmd 4;
BA_ "SPN" SG_ 2365469950 Valve4StateCmd 1956;
BA_ "SPN" SG_ 2365469950 Valve4PortFlowCmd 1955;
BA_ "SigType" SG_ 2365469950 Valve4PortFlowCmd 1;
BA_ "SPN" SG_ 2365469694 Valve3FailSaveModeCmd 1945;
BA_ "SigType" SG_ 2365469694 Valve3FailSaveModeCmd 4;
BA_ "SPN" SG_ 2365469694 Valve3StateCmd 1944;
BA_ "SPN" SG_ 2365469694 Valve3PortFlowCmd 1943;
BA_ "SigType" SG_ 2365469694 Valve3PortFlowCmd 1;
BA_ "SPN" SG_ 2365469438 Valve2FailSaveModeCmd 1933;
BA_ "SigType" SG_ 2365469438 Valve2FailSaveModeCmd 4;
BA_ "SPN" SG_ 2365469438 Valve2StateCmd 1932;
BA_ "SPN" SG_ 2365469438 Valve2PortFlowCmd 1931;
BA_ "SigType" SG_ 2365469438 Valve2PortFlowCmd 1;
BA_ "SigType" SG_ 2365469182 Valve1FailSaveModeCmd 4;
BA_ "SPN" SG_ 2365469182 Valve1StateCmd 1920;
BA_ "SPN" SG_ 2365469182 Valve1PortFlowCmd 1919;
BA_ "SigType" SG_ 2365469182 Valve1PortFlowCmd 1;
BA_ "SPN" SG_ 2365468926 Valve0FailSaveModeCmd 1909;
BA_ "SigType" SG_ 2365468926 Valve0FailSaveModeCmd 4;
BA_ "SPN" SG_ 2365468926 Valve0StateCmd 1908;
BA_ "SPN" SG_ 2365468926 Valve0PortFlowCmd 1907;
BA_ "SigType" SG_ 2365468926 Valve0PortFlowCmd 1;
BA_ "SPN" SG_ 2365468670 Valve15LimitStatus 5190;
BA_ "SPN" SG_ 2365468670 Valve15ReturnPortPressure 2342;
BA_ "SigType" SG_ 2365468670 Valve15ReturnPortPressure 1;
BA_ "SPN" SG_ 2365468670 Valve15RetractPortPressure 2341;
BA_ "SigType" SG_ 2365468670 Valve15RetractPortPressure 1;
BA_ "SPN" SG_ 2365468670 Valve15ExtendedPortPressure 2340;
BA_ "SigType" SG_ 2365468670 Valve15ExtendedPortPressure 1;
BA_ "SPN" SG_ 2365468670 Valve15RetractPortMeasuredFlow 2336;
BA_ "SigType" SG_ 2365468670 Valve15RetractPortMeasuredFlow 1;
BA_ "SPN" SG_ 2365468670 Valve15ExtendedPortMeasuredFlow 2335;
BA_ "SigType" SG_ 2365468670 Valve15ExtendedPortMeasuredFlow 1;
BA_ "SPN" SG_ 2365468414 Valve14LimitStatus 5188;
BA_ "SPN" SG_ 2365468414 Valve14ReturnPortPressure 2330;
BA_ "SigType" SG_ 2365468414 Valve14ReturnPortPressure 1;
BA_ "SPN" SG_ 2365468414 Valve14RetractPortPressure 2329;
BA_ "SigType" SG_ 2365468414 Valve14RetractPortPressure 1;
BA_ "SPN" SG_ 2365468414 Valve14ExtendedPortPressure 2328;
BA_ "SigType" SG_ 2365468414 Valve14ExtendedPortPressure 1;
BA_ "SPN" SG_ 2365468414 Valve14RetractPortMeasuredFlow 2324;
BA_ "SigType" SG_ 2365468414 Valve14RetractPortMeasuredFlow 1;
BA_ "SPN" SG_ 2365468414 Valve14ExtendedPortMeasuredFlow 2323;
BA_ "SigType" SG_ 2365468414 Valve14ExtendedPortMeasuredFlow 1;
BA_ "SPN" SG_ 2365468158 Valve13LimitStatus 5186;
BA_ "SPN" SG_ 2365468158 Valve13ReturnPortPressure 2318;
BA_ "SigType" SG_ 2365468158 Valve13ReturnPortPressure 1;
BA_ "SPN" SG_ 2365468158 Valve13RetractPortPressure 2317;
BA_ "SigType" SG_ 2365468158 Valve13RetractPortPressure 1;
BA_ "SPN" SG_ 2365468158 Valve13ExtendedPortPressure 2316;
BA_ "SigType" SG_ 2365468158 Valve13ExtendedPortPressure 1;
BA_ "SPN" SG_ 2365468158 Valve13RetractPortMeasuredFlow 2312;
BA_ "SigType" SG_ 2365468158 Valve13RetractPortMeasuredFlow 1;
BA_ "SPN" SG_ 2365468158 Valve13ExtendedPortMeasuredFlow 2311;
BA_ "SigType" SG_ 2365468158 Valve13ExtendedPortMeasuredFlow 1;
BA_ "SPN" SG_ 2365467902 Valve12LimitStatus 5184;
BA_ "SPN" SG_ 2365467902 Valve12ReturnPortPressure 2306;
BA_ "SigType" SG_ 2365467902 Valve12ReturnPortPressure 1;
BA_ "SPN" SG_ 2365467902 Valve12RetractPortPressure 2305;
BA_ "SigType" SG_ 2365467902 Valve12RetractPortPressure 1;
BA_ "SPN" SG_ 2365467902 Valve12ExtendedPortPressure 2304;
BA_ "SigType" SG_ 2365467902 Valve12ExtendedPortPressure 1;
BA_ "SPN" SG_ 2365467902 Valve12RetractPortMeasuredFlow 2300;
BA_ "SigType" SG_ 2365467902 Valve12RetractPortMeasuredFlow 1;
BA_ "SPN" SG_ 2365467902 Valve12ExtendedPortMeasuredFlow 2299;
BA_ "SigType" SG_ 2365467902 Valve12ExtendedPortMeasuredFlow 1;
BA_ "SPN" SG_ 2365467646 Valve11LimitStatus 5182;
BA_ "SPN" SG_ 2365467646 Valve11ReturnPortPressure 2294;
BA_ "SigType" SG_ 2365467646 Valve11ReturnPortPressure 1;
BA_ "SPN" SG_ 2365467646 Valve11RetractPortPressure 2293;
BA_ "SigType" SG_ 2365467646 Valve11RetractPortPressure 1;
BA_ "SPN" SG_ 2365467646 Valve11ExtendedPortPressure 2292;
BA_ "SigType" SG_ 2365467646 Valve11ExtendedPortPressure 1;
BA_ "SPN" SG_ 2365467646 Valve11RetractPortMeasuredFlow 2288;
BA_ "SigType" SG_ 2365467646 Valve11RetractPortMeasuredFlow 1;
BA_ "SPN" SG_ 2365467646 Valve11ExtendedPortMeasuredFlow 2287;
BA_ "SigType" SG_ 2365467646 Valve11ExtendedPortMeasuredFlow 1;
BA_ "SPN" SG_ 2365467390 Valve10LimitStatus 5180;
BA_ "SPN" SG_ 2365467390 Valve10ReturnPortPressure 2282;
BA_ "SigType" SG_ 2365467390 Valve10ReturnPortPressure 1;
BA_ "SPN" SG_ 2365467390 Valve10RetractPortPressure 2281;
BA_ "SigType" SG_ 2365467390 Valve10RetractPortPressure 1;
BA_ "SPN" SG_ 2365467390 Valve10ExtendedPortPressure 2280;
BA_ "SigType" SG_ 2365467390 Valve10ExtendedPortPressure 1;
BA_ "SPN" SG_ 2365467390 Valve10RetractPortMeasuredFlow 2276;
BA_ "SigType" SG_ 2365467390 Valve10RetractPortMeasuredFlow 1;
BA_ "SPN" SG_ 2365467390 Valve10ExtendedPortMeasuredFlow 2275;
BA_ "SigType" SG_ 2365467390 Valve10ExtendedPortMeasuredFlow 1;
BA_ "SPN" SG_ 2365467134 Valve9LimitStatus 5178;
BA_ "SPN" SG_ 2365467134 Valve9ReturnPortPressure 2270;
BA_ "SigType" SG_ 2365467134 Valve9ReturnPortPressure 1;
BA_ "SPN" SG_ 2365467134 Valve9RetractPortPressure 2269;
BA_ "SigType" SG_ 2365467134 Valve9RetractPortPressure 1;
BA_ "SPN" SG_ 2365467134 Valve9ExtendedPortPressure 2268;
BA_ "SigType" SG_ 2365467134 Valve9ExtendedPortPressure 1;
BA_ "SPN" SG_ 2365467134 Valve9RetractPortMeasuredFlow 2264;
BA_ "SigType" SG_ 2365467134 Valve9RetractPortMeasuredFlow 1;
BA_ "SPN" SG_ 2365467134 Valve9ExtendedPortMeasuredFlow 2263;
BA_ "SigType" SG_ 2365467134 Valve9ExtendedPortMeasuredFlow 1;
BA_ "SPN" SG_ 2365466878 Valve8LimitStatus 5176;
BA_ "SPN" SG_ 2365466878 Valve8ReturnPortPressure 2258;
BA_ "SigType" SG_ 2365466878 Valve8ReturnPortPressure 1;
BA_ "SPN" SG_ 2365466878 Valve8RetractPortPressure 2257;
BA_ "SigType" SG_ 2365466878 Valve8RetractPortPressure 1;
BA_ "SPN" SG_ 2365466878 Valve8ExtendedPortPressure 2256;
BA_ "SigType" SG_ 2365466878 Valve8ExtendedPortPressure 1;
BA_ "SPN" SG_ 2365466878 Valve8RetractPortMeasuredFlow 1996;
BA_ "SigType" SG_ 2365466878 Valve8RetractPortMeasuredFlow 1;
BA_ "SPN" SG_ 2365466878 Valve8ExtendedPortMeasuredFlow 1995;
BA_ "SigType" SG_ 2365466878 Valve8ExtendedPortMeasuredFlow 1;
BA_ "SPN" SG_ 2365466622 Valve7LimitStatus 5174;
BA_ "SPN" SG_ 2365466622 Valve7ReturnPortPressure 1990;
BA_ "SigType" SG_ 2365466622 Valve7ReturnPortPressure 1;
BA_ "SPN" SG_ 2365466622 Valve7RetractPortPressure 1989;
BA_ "SigType" SG_ 2365466622 Valve7RetractPortPressure 1;
BA_ "SPN" SG_ 2365466622 Valve7ExtendedPortPressure 1988;
BA_ "SigType" SG_ 2365466622 Valve7ExtendedPortPressure 1;
BA_ "SPN" SG_ 2365466622 Valve7RetractPortMeasuredFlow 1984;
BA_ "SigType" SG_ 2365466622 Valve7RetractPortMeasuredFlow 1;
BA_ "SPN" SG_ 2365466622 Valve7ExtendedPortMeasuredFlow 1983;
BA_ "SigType" SG_ 2365466622 Valve7ExtendedPortMeasuredFlow 1;
BA_ "SPN" SG_ 2365466366 Valve6LimitStatus 5172;
BA_ "SPN" SG_ 2365466366 Valve6ReturnPortPressure 1978;
BA_ "SigType" SG_ 2365466366 Valve6ReturnPortPressure 1;
BA_ "SPN" SG_ 2365466366 Valve6RetractPortPressure 1977;
BA_ "SigType" SG_ 2365466366 Valve6RetractPortPressure 1;
BA_ "SPN" SG_ 2365466366 Valve6ExtendedPortPressure 1976;
BA_ "SigType" SG_ 2365466366 Valve6ExtendedPortPressure 1;
BA_ "SPN" SG_ 2365466366 Valve6RetractPortMeasuredFlow 1972;
BA_ "SigType" SG_ 2365466366 Valve6RetractPortMeasuredFlow 1;
BA_ "SPN" SG_ 2365466366 Valve6ExtendedPortMeasuredFlow 1971;
BA_ "SigType" SG_ 2365466366 Valve6ExtendedPortMeasuredFlow 1;
BA_ "SPN" SG_ 2365466110 Valve5LimitStatus 5170;
BA_ "SPN" SG_ 2365466110 Valve5ReturnPortPressure 1966;
BA_ "SigType" SG_ 2365466110 Valve5ReturnPortPressure 1;
BA_ "SPN" SG_ 2365466110 Valve5RetractPortPressure 1965;
BA_ "SigType" SG_ 2365466110 Valve5RetractPortPressure 1;
BA_ "SPN" SG_ 2365466110 Valve5ExtendedPortPressure 1964;
BA_ "SigType" SG_ 2365466110 Valve5ExtendedPortPressure 1;
BA_ "SPN" SG_ 2365466110 Valve5RetractPortMeasuredFlow 1960;
BA_ "SigType" SG_ 2365466110 Valve5RetractPortMeasuredFlow 1;
BA_ "SPN" SG_ 2365466110 Valve5ExtendedPortMeasuredFlow 1959;
BA_ "SigType" SG_ 2365466110 Valve5ExtendedPortMeasuredFlow 1;
BA_ "SPN" SG_ 2365465854 Valve4LimitStatus 5168;
BA_ "SPN" SG_ 2365465854 Valve4ReturnPortPressure 1954;
BA_ "SigType" SG_ 2365465854 Valve4ReturnPortPressure 1;
BA_ "SPN" SG_ 2365465854 Valve4RetractPortPressure 1953;
BA_ "SigType" SG_ 2365465854 Valve4RetractPortPressure 1;
BA_ "SPN" SG_ 2365465854 Valve4ExtendedPortPressure 1952;
BA_ "SigType" SG_ 2365465854 Valve4ExtendedPortPressure 1;
BA_ "SPN" SG_ 2365465854 Valve4RetractPortMeasuredFlow 1948;
BA_ "SigType" SG_ 2365465854 Valve4RetractPortMeasuredFlow 1;
BA_ "SPN" SG_ 2365465854 Valve4ExtendedPortMeasuredFlow 1947;
BA_ "SigType" SG_ 2365465854 Valve4ExtendedPortMeasuredFlow 1;
BA_ "SPN" SG_ 2365465598 Valve3LimitStatus 5166;
BA_ "SPN" SG_ 2365465598 Valve3ReturnPortPressure 1942;
BA_ "SigType" SG_ 2365465598 Valve3ReturnPortPressure 1;
BA_ "SPN" SG_ 2365465598 Valve3RetractPortPressure 1941;
BA_ "SigType" SG_ 2365465598 Valve3RetractPortPressure 1;
BA_ "SPN" SG_ 2365465598 Valve3ExtendedPortPressure 1940;
BA_ "SigType" SG_ 2365465598 Valve3ExtendedPortPressure 1;
BA_ "SPN" SG_ 2365465598 Valve3RetractPortMeasuredFlow 1936;
BA_ "SigType" SG_ 2365465598 Valve3RetractPortMeasuredFlow 1;
BA_ "SPN" SG_ 2365465598 Valve3ExtendedPortMeasuredFlow 1935;
BA_ "SigType" SG_ 2365465598 Valve3ExtendedPortMeasuredFlow 1;
BA_ "SPN" SG_ 2365465342 Valve2LimitStatus 5164;
BA_ "SPN" SG_ 2365465342 Valve2ReturnPortPressure 1930;
BA_ "SigType" SG_ 2365465342 Valve2ReturnPortPressure 1;
BA_ "SPN" SG_ 2365465342 Valve2RetractPortPressure 1929;
BA_ "SigType" SG_ 2365465342 Valve2RetractPortPressure 1;
BA_ "SPN" SG_ 2365465342 Valve2ExtendedPortPressure 1928;
BA_ "SigType" SG_ 2365465342 Valve2ExtendedPortPressure 1;
BA_ "SPN" SG_ 2365465342 Valve2RetractPortMeasuredFlow 1924;
BA_ "SigType" SG_ 2365465342 Valve2RetractPortMeasuredFlow 1;
BA_ "SPN" SG_ 2365465342 Valve2ExtendedPortMeasuredFlow 1923;
BA_ "SigType" SG_ 2365465342 Valve2ExtendedPortMeasuredFlow 1;
BA_ "SPN" SG_ 2365465086 Valve1LimitStatus 5162;
BA_ "SPN" SG_ 2365465086 Valve1ReturnPortPressure 1918;
BA_ "SigType" SG_ 2365465086 Valve1ReturnPortPressure 1;
BA_ "SPN" SG_ 2365465086 Valve1RetractPortPressure 1917;
BA_ "SigType" SG_ 2365465086 Valve1RetractPortPressure 1;
BA_ "SPN" SG_ 2365465086 Valve1ExtendedPortPressure 1916;
BA_ "SigType" SG_ 2365465086 Valve1ExtendedPortPressure 1;
BA_ "SPN" SG_ 2365465086 Valve1RetractPortMeasuredFlow 1912;
BA_ "SigType" SG_ 2365465086 Valve1RetractPortMeasuredFlow 1;
BA_ "SPN" SG_ 2365465086 Valve1ExtendedPortMeasuredFlow 1911;
BA_ "SigType" SG_ 2365465086 Valve1ExtendedPortMeasuredFlow 1;
BA_ "SPN" SG_ 2365464830 Valve0LimitStatus 5160;
BA_ "SPN" SG_ 2365464830 Valve0ReturnPortPressure 1906;
BA_ "SigType" SG_ 2365464830 Valve0ReturnPortPressure 1;
BA_ "SPN" SG_ 2365464830 Valve0RetractPortPressure 1905;
BA_ "SigType" SG_ 2365464830 Valve0RetractPortPressure 1;
BA_ "SPN" SG_ 2365464830 Valve0ExtendedPortPressure 1904;
BA_ "SigType" SG_ 2365464830 Valve0ExtendedPortPressure 1;
BA_ "SigType" SG_ 2365464830 Valve0RetractPortMeasuredFlow 1;
BA_ "SPN" SG_ 2365464830 Valve0RetractPortMeasuredFlow 1900;
BA_ "SigType" SG_ 2365464830 Valve0ExtendedPortMeasuredFlow 1;
BA_ "SPN" SG_ 2365464830 Valve0ExtendedPortMeasuredFlow 1899;
BA_ "SPN" SG_ 2365464574 AuxValve15ExitReasonCode 5815;
BA_ "SPN" SG_ 2365464574 Valve15LimitStatus 5191;
BA_ "SPN" SG_ 2365464574 Valve15FailSafeMode 2346;
BA_ "SigType" SG_ 2365464574 Valve15FailSafeMode 4;
BA_ "SPN" SG_ 2365464574 Valve15ValveState 2339;
BA_ "SPN" SG_ 2365464574 Valve15RetractPortEstimatedFlow 2338;
BA_ "SigType" SG_ 2365464574 Valve15RetractPortEstimatedFlow 1;
BA_ "SPN" SG_ 2365464574 Valve15ExtendedPortEstimatedFlow 2337;
BA_ "SigType" SG_ 2365464574 Valve15ExtendedPortEstimatedFlow 1;
BA_ "SPN" SG_ 2365464318 Valve14LimitStatus 5189;
BA_ "SPN" SG_ 2365464318 Valve14FailSafeMode 2334;
BA_ "SigType" SG_ 2365464318 Valve14FailSafeMode 4;
BA_ "SPN" SG_ 2365464318 Valve14ValveState 2327;
BA_ "SPN" SG_ 2365464318 Valve14RetractPortEstimatedFlow 2326;
BA_ "SigType" SG_ 2365464318 Valve14RetractPortEstimatedFlow 1;
BA_ "SPN" SG_ 2365464318 Valve14ExtendedPortEstimatedFlow 2325;
BA_ "SigType" SG_ 2365464318 Valve14ExtendedPortEstimatedFlow 1;
BA_ "SPN" SG_ 2365464062 Valve13LimitStatus 5187;
BA_ "SPN" SG_ 2365464062 Valve13FailSafeMode 2322;
BA_ "SigType" SG_ 2365464062 Valve13FailSafeMode 4;
BA_ "SPN" SG_ 2365464062 Valve13ValveState 2315;
BA_ "SPN" SG_ 2365464062 Valve13RetractPortEstimatedFlow 2314;
BA_ "SigType" SG_ 2365464062 Valve13RetractPortEstimatedFlow 1;
BA_ "SPN" SG_ 2365464062 Valve13ExtendedPortEstimatedFlow 2313;
BA_ "SigType" SG_ 2365464062 Valve13ExtendedPortEstimatedFlow 1;
BA_ "SPN" SG_ 2365463806 Valve12LimitStatus 5185;
BA_ "SPN" SG_ 2365463806 Valve12FailSafeMode 2310;
BA_ "SigType" SG_ 2365463806 Valve12FailSafeMode 4;
BA_ "SPN" SG_ 2365463806 Valve12ValveState 2303;
BA_ "SPN" SG_ 2365463806 Valve12RetractPortEstimatedFlow 2302;
BA_ "SigType" SG_ 2365463806 Valve12RetractPortEstimatedFlow 1;
BA_ "SPN" SG_ 2365463806 Valve12ExtendedPortEstimatedFlow 2301;
BA_ "SigType" SG_ 2365463806 Valve12ExtendedPortEstimatedFlow 1;
BA_ "SPN" SG_ 2365463550 Valve11LimitStatus 5183;
BA_ "SPN" SG_ 2365463550 Valve11FailSafeMode 2298;
BA_ "SigType" SG_ 2365463550 Valve11FailSafeMode 4;
BA_ "SPN" SG_ 2365463550 Valve11ValveState 2291;
BA_ "SPN" SG_ 2365463550 Valve11RetractPortEstimatedFlow 2290;
BA_ "SigType" SG_ 2365463550 Valve11RetractPortEstimatedFlow 1;
BA_ "SPN" SG_ 2365463550 Valve11ExtendedPortEstimatedFlow 2289;
BA_ "SigType" SG_ 2365463550 Valve11ExtendedPortEstimatedFlow 1;
BA_ "SPN" SG_ 2365463294 Valve10LimitStatus 5181;
BA_ "SPN" SG_ 2365463294 Valve10FailSafeMode 2286;
BA_ "SigType" SG_ 2365463294 Valve10FailSafeMode 4;
BA_ "SPN" SG_ 2365463294 Valve10ValveState 2279;
BA_ "SPN" SG_ 2365463294 Valve10RetractPortEstimatedFlow 2278;
BA_ "SigType" SG_ 2365463294 Valve10RetractPortEstimatedFlow 1;
BA_ "SPN" SG_ 2365463294 Valve10ExtendedPortEstimatedFlow 2277;
BA_ "SigType" SG_ 2365463294 Valve10ExtendedPortEstimatedFlow 1;
BA_ "SPN" SG_ 2365463038 Valve9LimitStatus 5179;
BA_ "SPN" SG_ 2365463038 Valve9FailSafeMode 2274;
BA_ "SigType" SG_ 2365463038 Valve9FailSafeMode 4;
BA_ "SPN" SG_ 2365463038 Valve9ValveState 2267;
BA_ "SPN" SG_ 2365463038 Valve9RetractPortEstimatedFlow 2266;
BA_ "SigType" SG_ 2365463038 Valve9RetractPortEstimatedFlow 1;
BA_ "SPN" SG_ 2365463038 Valve9ExtendedPortEstimatedFlow 2265;
BA_ "SigType" SG_ 2365463038 Valve9ExtendedPortEstimatedFlow 1;
BA_ "SPN" SG_ 2365462782 Valve8LimitStatus 5177;
BA_ "SPN" SG_ 2365462782 Valve8FailSafeMode 2262;
BA_ "SigType" SG_ 2365462782 Valve8FailSafeMode 4;
BA_ "SPN" SG_ 2365462782 Valve8ValveState 1999;
BA_ "SPN" SG_ 2365462782 Valve8RetractPortEstimatedFlow 1998;
BA_ "SigType" SG_ 2365462782 Valve8RetractPortEstimatedFlow 1;
BA_ "SPN" SG_ 2365462782 Valve8ExtendedPortEstimatedFlow 1997;
BA_ "SigType" SG_ 2365462782 Valve8ExtendedPortEstimatedFlow 1;
BA_ "SPN" SG_ 2365462526 Valve7LimitStatus 5175;
BA_ "SPN" SG_ 2365462526 Valve7FailSafeMode 1994;
BA_ "SigType" SG_ 2365462526 Valve7FailSafeMode 4;
BA_ "SPN" SG_ 2365462526 Valve7ValveState 1987;
BA_ "SPN" SG_ 2365462526 Valve7RetractPortEstimatedFlow 1986;
BA_ "SigType" SG_ 2365462526 Valve7RetractPortEstimatedFlow 1;
BA_ "SPN" SG_ 2365462526 Valve7ExtendedPortEstimatedFlow 1985;
BA_ "SigType" SG_ 2365462526 Valve7ExtendedPortEstimatedFlow 1;
BA_ "SPN" SG_ 2365462270 Valve6LimitStatus 5173;
BA_ "SPN" SG_ 2365462270 Valve6FailSafeMode 1982;
BA_ "SigType" SG_ 2365462270 Valve6FailSafeMode 4;
BA_ "SPN" SG_ 2365462270 Valve6ValveState 1975;
BA_ "SPN" SG_ 2365462270 Valve6RetractPortEstimatedFlow 1974;
BA_ "SigType" SG_ 2365462270 Valve6RetractPortEstimatedFlow 1;
BA_ "SPN" SG_ 2365462270 Valve6ExtendedPortEstimatedFlow 1973;
BA_ "SigType" SG_ 2365462270 Valve6ExtendedPortEstimatedFlow 1;
BA_ "SPN" SG_ 2365462014 Valve5LimitStatus 5171;
BA_ "SPN" SG_ 2365462014 Valve5FailSafeMode 1970;
BA_ "SigType" SG_ 2365462014 Valve5FailSafeMode 4;
BA_ "SPN" SG_ 2365462014 Valve5ValveState 1963;
BA_ "SPN" SG_ 2365462014 Valve5RetractPortEstimatedFlow 1962;
BA_ "SigType" SG_ 2365462014 Valve5RetractPortEstimatedFlow 1;
BA_ "SPN" SG_ 2365462014 Valve5ExtendedPortEstimatedFlow 1961;
BA_ "SigType" SG_ 2365462014 Valve5ExtendedPortEstimatedFlow 1;
BA_ "SPN" SG_ 2365461758 Valve4LimitStatus 5169;
BA_ "SPN" SG_ 2365461758 Valve4FailSafeMode 1958;
BA_ "SigType" SG_ 2365461758 Valve4FailSafeMode 4;
BA_ "SPN" SG_ 2365461758 Valve4ValveState 1951;
BA_ "SPN" SG_ 2365461758 Valve4RetractPortEstimatedFlow 1950;
BA_ "SigType" SG_ 2365461758 Valve4RetractPortEstimatedFlow 1;
BA_ "SPN" SG_ 2365461758 Valve4ExtendedPortEstimatedFlow 1949;
BA_ "SigType" SG_ 2365461758 Valve4ExtendedPortEstimatedFlow 1;
BA_ "SPN" SG_ 2365461502 Valve3LimitStatus 5167;
BA_ "SPN" SG_ 2365461502 Valve3FailSafeMode 1946;
BA_ "SigType" SG_ 2365461502 Valve3FailSafeMode 4;
BA_ "SPN" SG_ 2365461502 Valve3ValveState 1939;
BA_ "SPN" SG_ 2365461502 Valve3RetractPortEstimatedFlow 1938;
BA_ "SigType" SG_ 2365461502 Valve3RetractPortEstimatedFlow 1;
BA_ "SPN" SG_ 2365461502 Valve3ExtendedPortEstimatedFlow 1937;
BA_ "SigType" SG_ 2365461502 Valve3ExtendedPortEstimatedFlow 1;
BA_ "SPN" SG_ 2365461246 Valve2LimitStatus 5165;
BA_ "SPN" SG_ 2365461246 Valve2FailSafeMode 1934;
BA_ "SigType" SG_ 2365461246 Valve2FailSafeMode 4;
BA_ "SPN" SG_ 2365461246 Valve2ValveState 1927;
BA_ "SPN" SG_ 2365461246 Valve2RetractPortEstimatedFlow 1926;
BA_ "SigType" SG_ 2365461246 Valve2RetractPortEstimatedFlow 1;
BA_ "SPN" SG_ 2365461246 Valve2ExtendedPortEstimatedFlow 1925;
BA_ "SigType" SG_ 2365461246 Valve2ExtendedPortEstimatedFlow 1;
BA_ "SPN" SG_ 2365460990 Valve1LimitStatus 5163;
BA_ "SPN" SG_ 2365460990 Valve1FailSafeMode 1922;
BA_ "SigType" SG_ 2365460990 Valve1FailSafeMode 4;
BA_ "SPN" SG_ 2365460990 Valve1ValveState 1915;
BA_ "SPN" SG_ 2365460990 Valve1RetractPortEstimatedFlow 1914;
BA_ "SigType" SG_ 2365460990 Valve1RetractPortEstimatedFlow 1;
BA_ "SPN" SG_ 2365460990 Valve1ExtendedPortEstimatedFlow 1913;
BA_ "SigType" SG_ 2365460990 Valve1ExtendedPortEstimatedFlow 1;
BA_ "SPN" SG_ 2365460734 AuxValveNum0ExitReasonCode 5800;
BA_ "SPN" SG_ 2365460734 Valve0LimitStatus 5161;
BA_ "SPN" SG_ 2365460734 Valve0FailSafeMode 1910;
BA_ "SigType" SG_ 2365460734 Valve0FailSafeMode 4;
BA_ "SPN" SG_ 2365460734 Valve0ValveState 1903;
BA_ "SPN" SG_ 2365460734 Valve0RetractPortEstimatedFlow 1902;
BA_ "SigType" SG_ 2365460734 Valve0RetractPortEstimatedFlow 1;
BA_ "SigType" SG_ 2365460734 Valve0ExtendedPortEstimatedFlow 1;
BA_ "SPN" SG_ 2365460734 Valve0ExtendedPortEstimatedFlow 1901;
BA_ "SigType" SG_ 2566787070 TemperatureUnits 4;
BA_ "SPN" SG_ 2566787070 TemperatureUnits 5194;
BA_ "SigType" SG_ 2566787070 PressureUnits 4;
BA_ "SPN" SG_ 2566787070 PressureUnits 5195;
BA_ "SigType" SG_ 2566787070 ForceUnits 4;
BA_ "SPN" SG_ 2566787070 ForceUnits 5196;
BA_ "SigType" SG_ 2566787070 UnitsSystem 4;
BA_ "SPN" SG_ 2566787070 UnitsSystem 5197;
BA_ "SPN" SG_ 2566787070 DistanceUnitCmd 2414;
BA_ "SigType" SG_ 2566787070 DistanceUnitCmd 4;
BA_ "SPN" SG_ 2566787070 AreaUnitCmd 2415;
BA_ "SigType" SG_ 2566787070 AreaUnitCmd 4;
BA_ "SPN" SG_ 2566787070 VolumeUnitCmd 2416;
BA_ "SigType" SG_ 2566787070 VolumeUnitCmd 4;
BA_ "SPN" SG_ 2566787070 MassUnitCmd 2417;
BA_ "SigType" SG_ 2566787070 MassUnitCmd 4;
BA_ "SPN" SG_ 2566787070 DateFormatCmd 2412;
BA_ "SigType" SG_ 2566787070 DateFormatCmd 1;
BA_ "SPN" SG_ 2566787070 DecimalSymbolCmd 2411;
BA_ "SigType" SG_ 2566787070 DecimalSymbolCmd 4;
BA_ "SPN" SG_ 2566787070 TimeFormatCmd 2413;
BA_ "SigType" SG_ 2566787070 TimeFormatCmd 4;
BA_ "SPN" SG_ 2566787070 LanguageCodeCmd 2410;
BA_ "SigType" SG_ 2566787070 LanguageCodeCmd 3;
BA_ "SigType" SG_ 2566786814 ActualRepetitionRate 1;
BA_ "SPN" SG_ 2566786814 ActualRepetitionRate 5198;
BA_ "SigType" SG_ 2566786814 PGN 6;
BA_ "SigType" SG_ 2633895422 NumberOfMembers 3;
BA_ "SPN" SG_ 2633895166 ArbitraryAddressCapable 2844;
BA_ "SPN" SG_ 2633895166 ECUInstance 2840;
BA_ "SPN" SG_ 2633895166 Function 2841;
BA_ "SPN" SG_ 2633895166 FunctionInstance 2839;
BA_ "SPN" SG_ 2633895166 IdentityNumber 2837;
BA_ "SPN" SG_ 2633895166 IndustryGroup 2846;
BA_ "SigType" SG_ 2633895166 ManufacturerCode 1;
BA_ "SPN" SG_ 2633895166 ManufacturerCode 2838;
BA_ "SPN" SG_ 2633895166 VehicleSystemInstance 2843;
BA_ "SigType" SG_ 2365459454 TractorControlCmdValue2 1;
BA_ "SigType" SG_ 2365459454 TractorControlCmdValue1 1;
BA_ "SPN" SG_ 2365459454 TractorControlModeCmd1 5204;
VAL_ 2628452094 RF_ReportHiddenFiles 0 "DoNotReportHiddenFiles" 1 "ReportHiddenFiles" 255 "NotAvailable" ;
VAL_ 2628452094 SF_PositionMode 0 "From the beginning of the file" 1 "From the current pointer pos" 2 "From the end of the file" ;
VAL_ 2628452094 OF_FlagExclusiveAccess 0 "Open file for shared read access" 1 "Open file with exclusive access" ;
VAL_ 2628452094 OF_FlagAppend 0 "Open file for random access" 1 "Open file for appending data" ;
VAL_ 2628452094 SA_ATTR_Hidden 3 "Leave attribute 'hidden'" 0 "Clear attribute 'hidden'" 1 "Set attribute 'hidden'" ;
VAL_ 2628452094 OF_FlagCreateNew 0 "Open an existing file" 1 "Create new file if not existing" ;
VAL_ 2628452094 MF_MoveModeRecursive 0 "'recursive' mode is not set" 1 "'recursive' mode is set" ;
VAL_ 2628452094 DF_DeleteModeRecursive 0 "'recursive' mode is not set" 1 "'recursive' mode is set" ;
VAL_ 2628452094 MF_MoveModeForce 0 "'force' mode is not set" 1 "'force' mode is set" ;
VAL_ 2628452094 DF_DeleteModeForce 0 "'force' mode is not set" 1 "'force' mode is set" ;
VAL_ 2628452094 SA_ATTR_ReadOnly 3 "Leave attribute 'read-only'" 0 "Clear attribute 'read-only'" 1 "Set attribute 'read-only'" ;
VAL_ 2628452094 OF_FlagReadWrite 0 "Open file for reading only" 1 "Open file for writing only" 2 "Open file for reading & writing" 3 "Open directory for reading" ;
VAL_ 2628452094 MF_MoveModeCopy 0 "'copy' mode is not set" 1 "'copy' mode is set" ;
VAL_ 2628452094 DF_DeleteMode 0 "'copy' mode is not set" 1 "'copy' mode is set" ;
VAL_ 2628452094 VS_RequestVolumeToPrepareForRemo 1 "RequestVolumeToPrepareForRemoval" ;
VAL_ 2628452094 VS_ReportVolumeUsedByClient 0 "ReportVolumeNotInUseByClient" 1 "ReportVolumeInUseByClient" ;
VAL_ 2628452094 CM_VersionNumber 0 "DIS" 1 "FDIS" 2 "FirstPublishedEditionOfIS" 3 "SecondPublishedEditionOfIS" 255 "CompliantToVersion2AndPrior" ;
VAL_ 2628452094 FSClientCommand 0 "ConnectionMaintenance" 16 "GetCurrentDirectoryRequest" 32 "OpenFileRequest" 33 "SeekFileRequest" 34 "ReadFileRequest" 35 "WriteFileRequest" 36 "CloseFileRequest" 48 "MoveFileRequest" 49 "DeleteFileRequest" 50 "GetFileAttributesRequest" 51 "SetFileAttributesRequest" 17 "ChangeCurrentDirectoryRequest" 52 "GetFileDateTimeRequest" 64 "VolumeInitializationRequest" 1 "GetFileServerProperties" 2 "VolumeStatusRequest" ;
VAL_ 2628517630 OF_ATTR_VolumeSupportsHidden 0 "No support of hidden attribute" 1 "Supports hidden attribute" ;
VAL_ 2628517630 OF_ATTR_VolumeIsCaseSensitive 0 "Is case-insensitive" 1 "Is case-sensitive" ;
VAL_ 2628517630 OF_ATTR_VolumeIsRemovable 0 "Is removable" 1 "Is not removable" ;
VAL_ 2628517630 OF_ATTR_SupportsLongFilenames 0 "Does not support long filename" 1 "Supports long filenames" ;
VAL_ 2628517630 OF_ATTR_IsDirectory 0 "Does not specifiy a directory" 1 "Specifes a directory" ;
VAL_ 2628517630 OF_ATTR_IsVolume 0 "Does not specifiy a volume" 1 "Specifies a volume" ;
VAL_ 2628517630 OF_ATTR_Hidden 0 "'Hidden' attribute is not set" 1 "'Hidden' attribute is set" ;
VAL_ 2628517630 OF_ATTR_ReadOnly 0 "'Read-only' attribute is not set" 1 "'Read-only' attribute is set" ;
VAL_ 2628517630 GA_ATTR_VolumeIsCaseSensitive 0 "Is case-insensitive" 1 "Is case-sensitive" ;
VAL_ 2628517630 VI_ATTR_VolumeRemovable 0 "Is removable" 1 "Is not removable" ;
VAL_ 2628517630 GA_ATTR_VolumeIsRemovable 0 "Is removable" 1 "Is not removable" ;
VAL_ 2628517630 VI_ATTR_SupportsLongFilenames 0 "Does not support long filename" 1 "Supports long filenames" ;
VAL_ 2628517630 GA_ATTR_SupportsLongFilenames 0 "Does not support long filename" 1 "Supports long filenames" ;
VAL_ 2628517630 GA_ATTR_IsDirectory 0 "Does not specifiy a directory" 1 "Specifes a directory" ;
VAL_ 2628517630 VI_ATTR_IsDirectory 0 "Does not specify a directory" 1 "Secifies a directory" ;
VAL_ 2628517630 VI_ATTR_IsVolume 0 "Does not specifiy a volume" 1 "Specifies a volume" ;
VAL_ 2628517630 GA_ATTR_IsVolume 0 "Does not specifiy a volume" 1 "Specifies a volume" ;
VAL_ 2628517630 VI_ATTR_VolumeSupportsHidden 0 "No support of hidden attribute" 1 "Supports hidden attribute" ;
VAL_ 2628517630 GA_ATTR_VolumeSupportsHidden 0 "No support of hidden attribute" 1 "Supports hidden attribute" ;
VAL_ 2628517630 VI_ATTR_Hidden 0 "'Hidden' attribute is not set" 1 "'Hidden' attribute is set" ;
VAL_ 2628517630 GA_ATTR_Hidden 0 "'Hidden' attribute is not set" 1 "'Hidden' attribute is set" ;
VAL_ 2628517630 VI_ATTR_ReadOnly 0 "'Read-only' attribute is not set" 1 "'Read-only' attribute is set" ;
VAL_ 2628517630 GA_ATTR_ReadOnly 0 "'Read-only' attribute is not set" 1 "'Read-only' attribute is set" ;
VAL_ 2628517630 GSP_SupportMultipleVolumes 0 "Beschreibung für den Wert '0'" ;
VAL_ 2628517630 FDT_ErrorCode 0 "Success" 1 "Access Denied" 3 "Too many files open" 4 "File, path or volume not found" 6 "Invalid given source name" 10 "Media is not present" 44 "Any other error" 43 "Out ot memory" 11 "Failure during a read operation" 13 " Volume possibly not initialized" ;
VAL_ 2628517630 RF_ErrorCode 45 "File pointer at end of file" 44 "Any other error" 42 "Invalid request length" 5 "Invalid handle" 0 "Success" 11 "Failure during read operation" 43 "Out of memory" 1 "Access denied" ;
VAL_ 2628517630 SF_ErrorCode 0 "Success" 5 "Invalid handle" 42 "Invalid request length" 44 "Any other error" 45 "File pointer at end of file" 11 "Failure during read operation" 43 "Out of memory" ;
VAL_ 2628517630 OF_ErrorCode 0 "Success" 1 "Access Denied" 2 "Invalid Access" 3 "Too many files open" 4 "File, path or volume not found" 6 "Invalid given source name" 8 "Volume out of free space" 10 "Media is not present" 44 "Any other error" 43 "Out of memory" 13 "Volume possibly not initialized" ;
VAL_ 2628517630 WF_ErrorCode 0 "Success" 1 "Access Denied" 5 "Invalid handle" 8 "Volume out of free space" 9 "Failure during a write operation" 42 "Invalid request length" 44 "Any other error" 43 "Out of memory" ;
VAL_ 2628517630 CF_ErrorCode 0 "Success" 1 "Access Denied" 5 "Invalid handle" 8 "Volume out of free space" 9 "Failure during a write operation" 44 "Any other error" 43 "Out ot memory" ;
VAL_ 2628517630 MF_ErrorCode 0 "Success" 1 "Access Denied" 3 "Too many files open" 6 "Invalid given source name" 7 "Invalid given destination name" 8 "Volume out of free space" 9 "Verify failure during a write op" 10 "Media is not present" 44 "Any other error" 43 "Out of memory" 4 "File, path or volume not found" 13 "Volume possibly not initialized" ;
VAL_ 2628517630 GA_ErrorCode 0 "Success" 1 "Access Denied" 3 "Too many files open" 4 "File, path or volume not found" 6 "Invalid given source name" 10 "Media is not present" 44 "Any other error" 43 "Out of memory" 11 "Failure during read operation" 13 "Volume possibly not initialized" ;
VAL_ 2628517630 SA_ErrorCode 0 "Success" 1 "Access Denied" 3 "Too many files open" 4 "File, path or volume not found" 6 "Invalid given source name" 8 "Volume out of free space" 9 "Failure during write operation" 10 "Media is not present" 44 "Any other error" 43 "Out of memory" 11 "Failure during read operation" 13 "Volume possibly not initialized" ;
VAL_ 2628517630 GCD_ErrorCode 0 "Success" 10 "Media is not present" 44 "Any other error" 43 "Out of Memory" 13 "Volume possibly not initialized" ;
VAL_ 2628517630 CCD_ErrorCode 0 "Success" 10 "Media is not present" 44 "Any other error" 43 "Out of memory" 13 "Volume possibly not initialized" 1 "Access denied" 2 "Invalid Access" 4 "File, path or volume not found" 7 "Invalid destination name given" ;
VAL_ 2628517630 DF_ErrorCode 0 "Success" 1 "Access Denied" 4 "File, path or volume not found" 6 "Invalid given source name" 10 "Media is not present" 44 "Any other error" 43 "Out of memory" 9 "Failure during write operation" 11 "Failure during read operation" 13 "Volume possibly not initialized" ;
VAL_ 2628517630 VI_ErrorCode 0 "Success" 1 "Access Denied" 4 "File, path or volume not found" 6 "Invalid given source name" 8 "Volume out of free space" 9 "Failure during write operation" 42 "Invalid request length" 44 "Any other error" 43 "Out of memory" 10 "Media is not present" 11 "Failure during read operation" 13 "Volume possibly not initialized" ;
VAL_ 2628517630 GSP_VersionNumber 0 "DIS" 1 "FDIS" 2 "FirstPublishedEditionOfIS" 3 "SecondPublishedEditionOfIS" 255 "CompliantToVersion2AndPrior" ;
VAL_ 2628517630 VS_VolumeStatus 0 "Present" 1 "InUse" 2 "PreparingForRemoval" 3 "Removed" ;
VAL_ 2628517630 FSServerCommand 0 "FileServerStatus" 16 "GetCurrentDirectoryResponse" 32 "OpenFileResponse" 33 "SeekFileResponse" 34 "ReadFileResponse" 35 "WriteFileResponse" 36 "CloseFileResponse" 48 "MoveFileResponse" 49 "DeleteFileResponse" 50 "GetFileAttributesResponse" 51 "SetFileAttributeResponse" 17 "ChangeCurrentDirectoryResponse" 52 "GetFileDateTimeResponse" 64 "VolumeInitializationResponse" 1 "GetFileServerPropertiesResponse" 2 "VolumeStatusResponse" ;
VAL_ 2364540158 EngStarterMode 15 "not available" 14 "error" 12 "starter inhibited  reason unknown" 9 "starter inhibited due to intake air shutoff valve being active" 8 "starter inhibited due to starter overtemp" 7 "starter inhibited due to active immobilizer" 6 "starter inhibited due to driveline engaged or other transmission inhibit" 5 "starter inhibited due to engine not ready for start preheating" 4 "starter inhibited due to engine already running" 3 "start finished starter not active after having been actively engaged after 50ms mode goes to 0000" 2 "starter active gear engaged" 1 "starter active gear not engaged" 0 "start not requested" 10 "starter inhibited due to active SCR inducement" 11 "Reserved" 13 "error legacy implementation only use 1110" ;
VAL_ 2364540158 ActlEngPrcntTorqueHighResolution 0 "0000" 1 "0125" 7 "0875" 8 "1111  not available" ;
VAL_ 2563309310 PGNumber 255 "NotAvailable" ;
VAL_ 2563309310 ControlByte 255 "EAbort" 20 "ERTS" 21 "ECTS" 22 "EDPO" 23 "EEoMACK" 24 "EAbort" ;
VAL_ 2563309310 ConnectionAbortReason 15 "ECTS requested packets exceeds message size" 14 "Unexpected ECTS PGN (PGN in ECTS is bad)" 13 "Deprecated use 254 instead" 12 "Bad EDPO offset" 11 "EDPO number of packets is greater than CTS" 10 "Unexpected EDPO PGN (PGN in EDPO is bad)" 9 "Unexpected EDPO packet" 8 "Duplicate sequence number" 1 "Already in one or more connection-managed sessions" 2 "System resources were needed for another task" 3 "Timeout occurred" 4 "CTS messages received when data transfer is in progress" 5 "Maximum retransmit request limit reached" 6 "Unexpected data transfer packet" 7 "Bad sequence number" ;
VAL_ 2583168510 RefrenceStationType1 14 "Error" 1 "GLONASS" 0 "GPS" ;
VAL_ 2583168510 GNSSIntegrity 3 "Unsafe" 2 "Caution" 1 "Safe" 0 "No integrity checking" ;
VAL_ 2583168510 GNSSMethod 14 "Error" 8 "Simulate mode" 7 "Manual input" 6 "Estimated (DR) mode" 5 "RTK float" 4 "RTK fixed integer" 3 "Precise GNSS" 2 "DGNSS fix" 1 "GNSS fix" 0 "no GPS" ;
VAL_ 2583168510 TypeOfSystem 4 "GPS and SBAS and GLONASS" 3 "GPS and SBAS(WAAS)" 2 "GPS and GLONASS" 1 "GLONASS" 0 "GPS" ;
VAL_ 2566849534 ManufacturerSpecific8 255 "NotAvailable" ;
VAL_ 2566849534 ManufacturerSpecific7 255 "NotAvailable" ;
VAL_ 2566849534 ManufacturerSpecific6 255 "NotAvailable" ;
VAL_ 2566849534 ManufacturerSpecific5 255 "NotAvailable" ;
VAL_ 2566849534 ManufacturerSpecific4 255 "NotAvailable" ;
VAL_ 2566849534 ManufacturerSpecific3 255 "NotAvailable" ;
VAL_ 2566849534 ManufacturerSpecific2 255 "NotAvailable" ;
VAL_ 2566849534 ManufacturerSpecific1 255 "NotAvailable" ;
VAL_ 2566849278 ManufacturerSpecific8 255 "NotAvailable" ;
VAL_ 2566849278 ManufacturerSpecific7 255 "NotAvailable" ;
VAL_ 2566849278 ManufacturerSpecific6 255 "NotAvailable" ;
VAL_ 2566849278 ManufacturerSpecific5 255 "NotAvailable" ;
VAL_ 2566849278 ManufacturerSpecific4 255 "NotAvailable" ;
VAL_ 2566849278 ManufacturerSpecific3 255 "NotAvailable" ;
VAL_ 2566849278 ManufacturerSpecific2 255 "NotAvailable" ;
VAL_ 2566849278 ManufacturerSpecific1 255 "NotAvailable" ;
VAL_ 2566849022 ManufacturerSpecific8 255 "NotAvailable" ;
VAL_ 2566849022 ManufacturerSpecific7 255 "NotAvailable" ;
VAL_ 2566849022 ManufacturerSpecific6 255 "NotAvailable" ;
VAL_ 2566849022 ManufacturerSpecific5 255 "NotAvailable" ;
VAL_ 2566849022 ManufacturerSpecific4 255 "NotAvailable" ;
VAL_ 2566849022 ManufacturerSpecific3 255 "NotAvailable" ;
VAL_ 2566849022 ManufacturerSpecific2 255 "NotAvailable" ;
VAL_ 2566849022 ManufacturerSpecific1 255 "NotAvailable" ;
VAL_ 2566848766 ManufacturerSpecific8 255 "NotAvailable" ;
VAL_ 2566848766 ManufacturerSpecific7 255 "NotAvailable" ;
VAL_ 2566848766 ManufacturerSpecific6 255 "NotAvailable" ;
VAL_ 2566848766 ManufacturerSpecific5 255 "NotAvailable" ;
VAL_ 2566848766 ManufacturerSpecific4 255 "NotAvailable" ;
VAL_ 2566848766 ManufacturerSpecific3 255 "NotAvailable" ;
VAL_ 2566848766 ManufacturerSpecific2 255 "NotAvailable" ;
VAL_ 2566848766 ManufacturerSpecific1 255 "NotAvailable" ;
VAL_ 2365475326 GroundBasedMachineDirection 3 "NotAvailable" 2 "ErrorIndication" 1 "Forward" 0 "Reverse" ;
VAL_ 2365475070 OperatorDirectionReversed 0 "Not reversed" 1 "Reversed" 2 "Error" 3 "Not available" ;
VAL_ 2365475070 StartStopState 3 "Don't Care" 2 "Reserved" 1 "Start or enable implement work" 0 "Stop or disable implement work" ;
VAL_ 2365475070 KeySwitchState 3 "NotAvailable" 2 "ErrorIndication" 1 "KeySwitchNotOff" 0 "KeySwitchOff" ;
VAL_ 2365475070 WheelBasedMachineDirection 3 "NotAvailable" 2 "ErrorIndicator" 1 "Forward" 0 "Reverse" ;
VAL_ 2566801406 ImplementInWorkState 3 "Not available" 2 "Error indication" 1 "Implement is in work state" 0 "Implement is not in work state" ;
VAL_ 2566801406 ImplementTransportState 3 "Not available" 2 "Error indication" 1 "Implement may be transported" 0 "Implement may not be transported" ;
VAL_ 2566801406 ImplementParkState 3 "Not available" 2 "Error indication" 1 "Implement may be disconnected" 0 "Implement may not be disconnected" ;
VAL_ 2566801406 ImplementReadyToWorkState 3 "Not available" 2 "Error indication" 1 "Implement is ready for field work" 0 "Implement is not ready for field work" ;
VAL_ 2566801406 MaintainECUPower 3 "DoNotCare" 1 "RequireForTwoMoreSecOfECU_PWR" 0 "NoFurtherRequireForECU_PWR" ;
VAL_ 2566801406 MaintainActuatorPower 3 "DoNotCare" 1 "RequireForTwoMoreSecOfPWR" 0 "NoFurtherRequirementForPWR" ;
VAL_ 2365474558 FrontHitchExitReasonCode 0 "No reason/all clear " 1 "Operator presence not detected" 2 "Implement released control of function" 3 "Operator override of function " 4 "Operator control not in valid position " 5 "Remote command timeout " 6 "Remote command out of range/invalid " 7 "Function not calibrated " 8 "Operator control fault " 9 "Function fault " 20 "Hydraulic oil level too low " 21 "Hitch locked out " 62 "Error" 63 "Not available (parameter not supported) " ;
VAL_ 2365474558 FrontHitchInWorkIndication 3 "NotAvailable" 2 "ErrorIndication" 1 "HitchPositionIsInWorl" 0 "HitchPositionIsOutOfWork" ;
VAL_ 2365474558 FrontHitchPositionLimitStatus 0 "Not limited" 1 "Operator Limited" 2 "Limited High" 3 "Limited Low" 4 "Reserved" 5 "Reserver" 6 "Non-recoverable Fault" 7 "Not available" ;
VAL_ 2365474302 RearHitchExitReasonCode 0 "No reason/all clear " 1 "Operator presence not detected" 2 "Implement released control of function" 3 "Operator override of function " 4 "Operator control not in valid position " 5 "Remote command timeout " 6 "Remote command out of range/invalid " 7 "Function not calibrated " 8 "Operator control fault " 9 "Function fault " 20 "Hydraulic oil level too low " 21 "Hitch locked out " 62 "Error" 63 "Not available (parameter not supported) " ;
VAL_ 2365474302 RearHitchInWorkIndication 3 "NotAvailable" 2 "ErrorIndication" 1 "HitchPositionIsInWork" 0 "HitchPositionIsOutOfWork" ;
VAL_ 2365474302 RearHitchPositionLimitStatus 0 "Not limited" 1 "Operator Limited" 2 "Limited High" 3 "Limited Low" 4 "Reserved" 5 "Reserver" 6 "Non-recoverable Fault" 7 "Not available" ;
VAL_ 2365474046 FrontPTOExitReasonCode 0 "No reason/all clear" 1 "Operator presence not detected" 2 "Implement released control of function" 3 "Operator override of function " 4 "Operator control not in valid position " 5 "Remote command timeout " 6 "Remote command out of range/invalid " 7 "Function not calibrated " 8 "Operator control fault " 9 "Function fault " 20 "Invalid PTO gear" 62 "Error " 63 "Not available (parameter not supported)" ;
VAL_ 2365474046 FrontPTOModeRqStatus 0 "External Request accepted" 1 "Control Override" 2 "Error" 3 "Not available" ;
VAL_ 2365474046 FrontPTOEconomyModeRqStatus 0 "External Request accepted" 1 "Control Override" 2 "Error" 3 "Not available" ;
VAL_ 2365474046 FrontPTOShaftSpeedLimitStatus 0 "Not limited" 1 "Operator Limited" 2 "Limited High" 3 "Limited Low" 4 "Reserved" 5 "Reserver" 6 "Non-recoverable Fault" 7 "Not available" ;
VAL_ 2365474046 FrontPTOEngagement 3 "NotAvailable" 2 "ErrorIndication" 1 "PTOEngaged" 0 "PTODisengaged" ;
VAL_ 2365474046 FrontPTOMode 3 "NotAvailable" 2 "ErrorIndication" 1 "PTOModeIs1000" 0 "PTOModeIs540" ;
VAL_ 2365474046 FrontPTOEconomyMode 3 "NotAvailable" 2 "ErrorIndication" 1 "PTOEconomyModeIsEngaged" 0 "PTOEconomyModeIsDisengaged" ;
VAL_ 2365474046 FrontPTOEngagementRqStatus 0 "External Request accepted" 1 "Control Override" 2 "Error" 3 "Not available" ;
VAL_ 2365473790 RearPTOExitReasonCode 0 "No reason/all clear" 1 "Operator presence not detected" 2 "Implement released control of function" 3 "Operator override of function " 4 "Operator control not in valid position " 5 "Remote command timeout " 6 "Remote command out of range/invalid " 7 "Function not calibrated " 8 "Operator control fault " 9 "Function fault " 20 "Invalid PTO gear" 62 "Error " 63 "Not available (parameter not supported)" ;
VAL_ 2365473790 RearPTOModeRqStatus 0 "External Request accepted" 1 "Control Override" 2 "Error" 3 "Not available" ;
VAL_ 2365473790 RearPTOEconomyModeRqStatus 0 "External Request accepted" 1 "Control Override" 2 "Error" 3 "Not available" ;
VAL_ 2365473790 RearPTOShaftSpeedLimitStatus 0 "Not limited" 1 "Operator Limited" 2 "Limited High" 3 "Limited Low" 4 "Reserved" 5 "Reserver" 6 "Non-recoverable Fault" 7 "Not available" ;
VAL_ 2365473790 RearPTOEngagement 3 "NotAvailable" 2 "ErrorIndication" 1 "PTOEngaged" 0 "PTODisengaged" ;
VAL_ 2365473790 RearPTOMode 3 "NotAvailable" 2 "ErrorIndication" 1 "PTOModeIs1000" 0 "PTOModeIs540" ;
VAL_ 2365473790 RearPTOEconomyMode 3 "NotAvailabel" 2 "ErrorIndication" 1 "PTOEconomyModeIsEngaged" 0 "PTOEconomyModeIsDisengaged" ;
VAL_ 2365473790 RearPTOEngagementRqStatus 0 "External Request accepted" 1 "Control Override" 2 "Error" 3 "Not available" ;
VAL_ 2365473534 FrontPTOModeCmd 3 "DoNotCare" 1 "Select1000rpmMode" 0 "Select540rpmMode" ;
VAL_ 2365473534 RearPTOModeCmd 3 "DoNotCare" 1 "Select1000rpmMode" 0 "Select540rpmMode" ;
VAL_ 2365473534 FrontPTOEconomyModeCmd 3 "DoNotCare" 1 "EngagePTOEconomyMode" 0 "DisengagePTOEconomyMode" ;
VAL_ 2365473534 RearPTOEconomyModeCmd 3 "DoNotCare" 1 "EngagePTOEconomyMode" 0 "DisengagePTOEconomyMode" ;
VAL_ 2365473534 FrontPTOEngagementCmd 3 "DoNotCare" 1 "EngagePTO" 0 "DisengagePTO" ;
VAL_ 2365473534 RearPTOEngagementCmd 3 "DoNotCare" 1 "EngangePTO" 0 "DisengagePTO" ;
VAL_ 2365473278 ImplementRearWorkLightCmd 0 "Deactivate" 1 "Activate" 2 "Reserved" 3 "Dont Care" ;
VAL_ 2365473278 ImplementLeftFacingWorkLightCmd 3 "Dont Care" 1 "Activate" 0 "Deactivate" 2 "Reserved" ;
VAL_ 2365473278 ImplementRightFacingWorkLightCmd 0 "Deactivate" 1 "Activate" 2 "Reserved" 3 "Dont Care" ;
VAL_ 2365473278 LightingDataRequestCmd 3 "DoNotCare" 1 "Acitvate" 0 "Deactivate" ;
VAL_ 2365473278 ImplementLeftForwardLightCmd 3 "DoNotCare" 1 "Acitvate" 0 "Deactivate" ;
VAL_ 2365473278 ImplementRightForwardLightCmd 3 "DoNotCare" 1 "Acitvate" 0 "Deactivate" ;
VAL_ 2365473278 ImplementOEMOption1LightCmd 0 "Deactivate" 1 "Activate" 2 "Reserved" 3 "Dont Care" ;
VAL_ 2365473278 ImplementOEMOption2LightCmd 0 "Deactivate" 1 "Activate" 2 "Reserved" 3 "Dont Care" ;
VAL_ 2365473278 TractorFrontHighWorkLightCmd 3 "DoNotCare" 1 "Acitvate" 0 "Deactivate" ;
VAL_ 2365473278 TractorFrontLowWorkLightCmd 3 "DoNotCare" 1 "Acitvate" 0 "Deactivate" ;
VAL_ 2365473278 TractorSideHighWorkLightCmd 3 "DoNotCare" 1 "Acitvate" 0 "Deactivate" ;
VAL_ 2365473278 TractorSideLowWorkLightCmd 3 "DoNotCare" 1 "Acitvate" 0 "Deactivate" ;
VAL_ 2365473278 TractorRearHighWorkLightCmd 3 "DoNotCare" 1 "Acitvate" 0 "Deactivate" ;
VAL_ 2365473278 TractorRearLowWorkLightCmd 3 "DoNotCare" 1 "Acitvate" 0 "Deactivate" ;
VAL_ 2365473278 TractorUndersideWorkLightCmd 3 "DoNotCare" 1 "Acitvate" 0 "Deactivate" ;
VAL_ 2365473278 RearFogLightCmd 3 "Dont Care" 1 "Activate" 0 "Deactivate" 2 "Reserved" ;
VAL_ 2365473278 TractorMarkerLightCmd 3 "Dont Care" 1 "Activate" 0 "Deactivate" 2 "Reserved" ;
VAL_ 2365473278 ImplementMarkerLightCmd 3 "Dont Care" 1 "Activate" 0 "Deactivate" 2 "Reserved" ;
VAL_ 2365473278 TractorClearanceLightCmd 3 "Dont Care" 1 "Activate" 0 "Deactivate" 2 "Reserved" ;
VAL_ 2365473278 ImplementClearanceLightCmd 3 "Dont Care" 1 "Activate" 0 "Deactivate" 2 "Reserved" ;
VAL_ 2365473278 LeftStopLightCmd 3 "Dont Care" 1 "Activate" 0 "Deactivate" 2 "Reserved" ;
VAL_ 2365473278 RightStopLightCmd 0 "Deactivate" 1 "Activate" 2 "Reserved" 3 "Dont Care" ;
VAL_ 2365473278 CentreStopLightCmd 3 "DoNotCare" 1 "Acitvate" 0 "Deactivate" ;
VAL_ 2365473278 BackUpLightAndAlarmHornCmd 3 "Dont Care" 1 "Activate" 0 "Deactivate" 2 "Reserved" ;
VAL_ 2365473278 LeftTurnSignalLightCmd 3 "DoNotCare" 1 "Activate" 0 "Deactivate" ;
VAL_ 2365473278 RightTurnSignalLightCmd 3 "DoNotCare" 1 "Activate" 0 "Deactivate" ;
VAL_ 2365473278 RotatingBeaconLightCmd 0 "Deactivate" 1 "Activate" 2 "Reserved" 3 "Dont Care" ;
VAL_ 2365473278 TractorFrontFogLightCmd 3 "DoNotCare" 1 "Activate" 0 "Deactivate" ;
VAL_ 2365473278 HighBeamHeadLightCmd 3 "Dont Care" 1 "Activate" 0 "Deactivate" 2 "Reserved" ;
VAL_ 2365473278 LowBeamHeadLightCmd 3 "Dont Care" 1 "Activate" 0 "Deactivate" 2 "Reserved" ;
VAL_ 2365473278 AlternateHeadLightCmd 3 "DoNotCare" 1 "Activate" 0 "Deactivate" ;
VAL_ 2365473278 DaytimeRunningLightCmd 3 "DoNotCare" 1 "Activate" 0 "Deactivate" ;
VAL_ 2566799614 ImplementRearWorkLightData 3 "NotAvailable" 2 "FaultDetected" 1 "Activated" 0 "Deactivated" ;
VAL_ 2566799614 ImplLeftFacingWorkLightData 3 "NotAvailable" 2 "FaultDetected" 1 "Activated" 0 "Deactivated" ;
VAL_ 2566799614 ImplRightFacingWorkLightData 3 "NotAvailable" 2 "FaultDetected" 1 "Activated" 0 "Deactivated" ;
VAL_ 2566799614 ImplementLeftForwardLightData 3 "NotAvailable" 2 "FaultDetected" 1 "Activated" 0 "Deactivated" ;
VAL_ 2566799614 ImplementRightForwardLightData 3 "NotAvailable" 2 "FaultDetected" 1 "Activated" 0 "Deactivated" ;
VAL_ 2566799614 ImplementOEMOption1LightData 3 "NotAvailable" 2 "FaultDetected" 1 "Activated" 0 "Deactivated" ;
VAL_ 2566799614 ImplementOEMOption2LightData 3 "NotAvailable" 2 "FaultDetected" 1 "Activated" 0 "Deactivated" ;
VAL_ 2566799614 TractorFrontHighWorkLightData 3 "NotAvailable" 2 "FaultDetected" 1 "Activated" 0 "Deactivated" ;
VAL_ 2566799614 TractorFrontLowWorkLightData 3 "NotAvailable" 2 "FaultDetected" 1 "Activated" 0 "Deactivated" ;
VAL_ 2566799614 TractorSideHighWorkLightData 3 "NotAvailable" 2 "FaultDetected" 1 "Activated" 0 "Deactivated" ;
VAL_ 2566799614 TractorSideLowWorkLightData 3 "NotAvailable" 2 "FaultDetected" 1 "Activated" 0 "Deactivated" ;
VAL_ 2566799614 TractorRearHighWorkLightData 3 "NotAvailable" 2 "FaultDetected" 1 "Activated" 0 "Deactivated" ;
VAL_ 2566799614 TractorRearLowWorkLightData 3 "NotAvailable" 2 "FaultDetected" 1 "Activated" 0 "Deactivated" ;
VAL_ 2566799614 TractorUndersideWorkLightData 3 "NotAvailable" 2 "FaultDetected" 1 "Activated" 0 "Deactivated" ;
VAL_ 2566799614 RearFogLightData 3 "NotAvailable" 2 "FaultDetected" 1 "Activated" 0 "Deactivated" ;
VAL_ 2566799614 TractorMarkerLightData 3 "NotAvailable" 2 "FaultDetected" 1 "Activated" 0 "Deactivated" ;
VAL_ 2566799614 ImplementMarkerLightData 3 "NotAvailable" 2 "FaultDetected" 1 "Activated" 0 "Deactivated" ;
VAL_ 2566799614 TractorClearanceLightData 3 "NotAvailable" 2 "FaultDetected" 1 "Activated" 0 "Deactivated" ;
VAL_ 2566799614 ImplementClearanceLightData 3 "NotAvailable" 2 "FaultDetected" 1 "Activated" 0 "Deactivated" ;
VAL_ 2566799614 LefttStopLightData 3 "NotAvailable" 2 "FaultDetected" 1 "Activated" 0 "Deactivated" ;
VAL_ 2566799614 RightStopLightData 3 "NotAvailable" 2 "FaultDetected" 1 "Activated" 0 "Deactivated" ;
VAL_ 2566799614 CentreStopLightData 3 "NotAvailable" 2 "FaultDetected" 1 "Activated" 0 "Deactivated" ;
VAL_ 2566799614 BackUpLightAndAlarmHornData 3 "NotAvailable" 2 "FaultDetected" 1 "Activated" 0 "Deactivated" ;
VAL_ 2566799614 LeftTurnSignalLightData 3 "NotAvailable" 2 "FaultDetected" 1 "Activated" 0 "Deactivated" ;
VAL_ 2566799614 RightTurnSignalLightData 3 "NotAvailable" 2 "FaultDetected" 1 "Activated" 0 "Deactivated" ;
VAL_ 2566799614 RotationBeaconLightData 3 "NotAvailable" 2 "FaultDetected" 1 "Activated" 0 "Deactivated" ;
VAL_ 2566799614 TractorFrontFogLightData 3 "NotAvailable" 2 "FaultDetected" 1 "Activated" 0 "Deactivated" ;
VAL_ 2566799614 HighBeamHeadLightData 3 "Not Available" 2 "Fault Detected" 1 "Activated" 0 "Deactivated" ;
VAL_ 2566799614 LowBeamHeadLightData 3 "Not Available" 2 "Fault Detected" 1 "Activated" 0 "Deactivated" ;
VAL_ 2566799614 AlternateHeadLightData 3 "NotAvailable" 2 "FaultDetected" 1 "Activated" 0 "Deactivated" ;
VAL_ 2566799614 DaytimeRunningLightData 3 "NotAvailable" 2 "FaultDetected" 1 "Activated" 0 "Deactivated" ;
VAL_ 2365472766 Valve15FailSaveModeCmd 3 "DoNotCare" 1 "Float" 0 "Block" ;
VAL_ 2365472766 Valve15StateCmd 15 "Reserved" 3 "Float" 2 "Retract" 1 "Extend" 0 "Block" ;
VAL_ 2365472510 Valve14FailSaveModeCmd 3 "DoNotCare" 1 "Float" 0 "Block" ;
VAL_ 2365472510 Valve14StateCmd 15 "Reserved" 3 "Float" 2 "Retract" 1 "Extend" 0 "Block" ;
VAL_ 2365472254 Valve13FailSaveModeCmd 3 "DoNotCare" 1 "Float" 0 "Block" ;
VAL_ 2365472254 Valve13StateCmd 15 "Reserved" 3 "Float" 2 "Retract" 1 "Extend" 0 "Block" ;
VAL_ 2365471998 Valve12FailSaveModeCmd 3 "DoNotCare" 1 "Float" 0 "Block" ;
VAL_ 2365471998 Valve12StateCmd 15 "Reserved" 3 "Float" 2 "Retract" 1 "Extend" 0 "Block" ;
VAL_ 2365471742 Valve11FailSaveModeCmd 3 "DoNotCare" 1 "Float" 0 "Block" ;
VAL_ 2365471742 Valve11StateCmd 15 "Reserved" 3 "Float" 2 "Retract" 1 "Extend" 0 "Block" ;
VAL_ 2365471486 Valve10FailSaveModeCmd 3 "DoNotCare" 1 "Float" 0 "Block" ;
VAL_ 2365471486 Valve10StateCmd 15 "Reserved" 3 "Float" 2 "Retract" 1 "Extend" 0 "Block" ;
VAL_ 2365471230 Valve9FailSaveModeCmd 3 "DoNotCare" 1 "Float" 0 "Block" ;
VAL_ 2365471230 Valve9StateCmd 15 "Reserved" 3 "Float" 2 "Retract" 1 "Extend" 0 "Block" ;
VAL_ 2365470974 Valve8FailSaveModeCmd 3 "DoNotCare" 1 "Float" 0 "Block" ;
VAL_ 2365470974 Valve8StateCmd 15 "Reserved" 3 "Float" 2 "Retract" 1 "Extend" 0 "Block" ;
VAL_ 2365470718 Valve7FailSaveModeCmd 3 "DoNotCare" 1 "Float" 0 "Block" ;
VAL_ 2365470718 Valve7StateCmd 15 "Reserved" 3 "Float" 2 "Retract" 1 "Extend" 0 "Block" ;
VAL_ 2365470462 Valve6FailSaveModeCmd 3 "DoNotCare" 1 "Float" 0 "Block" ;
VAL_ 2365470462 Valve6StateCmd 15 "Reserved" 3 "Float" 2 "Retract" 1 "Extend" 0 "Block" ;
VAL_ 2365470206 Valve5FailSaveModeCmd 3 "DoNotCare" 1 "Float" 0 "Block" ;
VAL_ 2365470206 Valve5StateCmd 15 "Reserved" 3 "Float" 2 "Retract" 1 "Extend" 0 "Block" ;
VAL_ 2365469950 Valve4FailSaveModeCmd 3 "DoNotCare" 1 "Float" 0 "Block" ;
VAL_ 2365469950 Valve4StateCmd 15 "Reserved" 3 "Float" 2 "Retract" 1 "Extend" 0 "Block" ;
VAL_ 2365469694 Valve3FailSaveModeCmd 3 "DoNotCare" 1 "Float" 0 "Block" ;
VAL_ 2365469694 Valve3StateCmd 15 "Reserved" 3 "Float" 2 "Retract" 1 "Extend" 0 "Block" ;
VAL_ 2365469438 Valve2FailSaveModeCmd 3 "DoNotCare" 1 "Float" 0 "Block" ;
VAL_ 2365469438 Valve2StateCmd 15 "Reserved" 3 "Float" 2 "Retract" 1 "Extend" 0 "Block" ;
VAL_ 2365469182 Valve1FailSaveModeCmd 3 "DoNotCare" 1 "Float" 0 "Block" ;
VAL_ 2365469182 Valve1StateCmd 15 "Reserved" 3 "Float" 2 "Retract" 1 "Extend" 0 "Block" ;
VAL_ 2365468926 Valve0FailSaveModeCmd 3 "DoNotCare" 1 "Float" 0 "Block" ;
VAL_ 2365468926 Valve0StateCmd 15 "Reserved" 3 "Float" 2 "Retract" 1 "Extend" 0 "Block" ;
VAL_ 2365468670 Valve15LimitStatus 0 "Not limited" 1 "Operator Limited" 2 "Limited High" 3 "Limited Low" 4 "Reserved" 5 "Reserver" 6 "Non-recoverable Fault" 7 "Not available" ;
VAL_ 2365468414 Valve14LimitStatus 0 "Not limited" 1 "Operator Limited" 2 "Limited High" 3 "Limited Low" 4 "Reserved" 5 "Reserver" 6 "Non-recoverable Fault" 7 "Not available" ;
VAL_ 2365468158 Valve13LimitStatus 0 "Not limited" 1 "Operator Limited" 2 "Limited High" 3 "Limited Low" 4 "Reserved" 5 "Reserver" 6 "Non-recoverable Fault" 7 "Not available" ;
VAL_ 2365467902 Valve12LimitStatus 0 "Not limited" 1 "Operator Limited" 2 "Limited High" 3 "Limited Low" 4 "Reserved" 5 "Reserver" 6 "Non-recoverable Fault" 7 "Not available" ;
VAL_ 2365467646 Valve11LimitStatus 0 "Not limited" 1 "Operator Limited" 2 "Limited High" 3 "Limited Low" 4 "Reserved" 5 "Reserver" 6 "Non-recoverable Fault" 7 "Not available" ;
VAL_ 2365467390 Valve10LimitStatus 0 "Not limited" 1 "Operator Limited" 2 "Limited High" 3 "Limited Low" 4 "Reserved" 5 "Reserver" 6 "Non-recoverable Fault" 7 "Not available" ;
VAL_ 2365467134 Valve9LimitStatus 0 "Not limited" 1 "Operator Limited" 2 "Limited High" 3 "Limited Low" 4 "Reserved" 5 "Reserver" 6 "Non-recoverable Fault" 7 "Not available" ;
VAL_ 2365466878 Valve8LimitStatus 0 "Not limited" 1 "Operator Limited" 2 "Limited High" 3 "Limited Low" 4 "Reserved" 5 "Reserver" 6 "Non-recoverable Fault" 7 "Not available" ;
VAL_ 2365466622 Valve7LimitStatus 0 "Not limited" 1 "Operator Limited" 2 "Limited High" 3 "Limited Low" 4 "Reserved" 5 "Reserver" 6 "Non-recoverable Fault" 7 "Not available" ;
VAL_ 2365466366 Valve6LimitStatus 0 "Not limited" 1 "Operator Limited" 2 "Limited High" 3 "Limited Low" 4 "Reserved" 5 "Reserver" 6 "Non-recoverable Fault" 7 "Not available" ;
VAL_ 2365466110 Valve5LimitStatus 0 "Not limited" 1 "Operator Limited" 2 "Limited High" 3 "Limited Low" 4 "Reserved" 5 "Reserver" 6 "Non-recoverable Fault" 7 "Not available" ;
VAL_ 2365465854 Valve4LimitStatus 0 "Not limited" 1 "Operator Limited" 2 "Limited High" 3 "Limited Low" 4 "Reserved" 5 "Reserver" 6 "Non-recoverable Fault" 7 "Not available" ;
VAL_ 2365465598 Valve3LimitStatus 0 "Not limited" 1 "Operator Limited" 2 "Limited High" 3 "Limited Low" 4 "Reserved" 5 "Reserver" 6 "Non-recoverable Fault" 7 "Not available" ;
VAL_ 2365465342 Valve2LimitStatus 0 "Not limited" 1 "Operator Limited" 2 "Limited High" 3 "Limited Low" 4 "Reserved" 5 "Reserver" 6 "Non-recoverable Fault" 7 "Not available" ;
VAL_ 2365465086 Valve1LimitStatus 0 "Not limited" 1 "Operator Limited" 2 "Limited High" 3 "Limited Low" 4 "Reserved" 5 "Reserver" 6 "Non-recoverable Fault" 7 "Not available" ;
VAL_ 2365464830 Valve0LimitStatus 0 "Not limited" 1 "Operator Limited" 2 "Limited High" 3 "Limited Low" 4 "Reserved" 5 "Reserver" 6 "Non-recoverable Fault" 7 "Not available" ;
VAL_ 2365464574 AuxValve15ExitReasonCode 0 "No reason/all clear " 1 "Operator presence not detected " 2 "Implement released control of function" 3 "Operator override of function" 4 "Operator control not in valid position" 5 "Remote command timeout " 6 "Remote command out of range/invalid " 7 "Function not calibrated" 8 "Operator control fault " 9 "Function fault " 20 "Hydraulic oil level too low " 21 "Valve locked out " 62 "Error " 63 "Not available (parameter not supported)" ;
VAL_ 2365464574 Valve15LimitStatus 0 "Not limited" 1 "Operator Limited" 2 "Limited High" 3 "Limited Low" 4 "Reserved" 5 "Reserver" 6 "Non-recoverable Fault" 7 "Not available" ;
VAL_ 2365464574 Valve15FailSafeMode 3 "NotAvailable" 2 "ErrorIndication" 1 "Float" 0 "Block" ;
VAL_ 2365464574 Valve15ValveState 15 "DoNotCare" 14 "ErrorIndication" 3 "Floating" 2 "Retract" 1 "Extend" 0 "Blocked" ;
VAL_ 2365464318 Valve14LimitStatus 0 "Not limited" 1 "Operator Limited" 2 "Limited High" 3 "Limited Low" 4 "Reserved" 5 "Reserver" 6 "Non-recoverable Fault" 7 "Not available" ;
VAL_ 2365464318 Valve14FailSafeMode 3 "NotAvailable" 2 "ErrorIndication" 1 "Float" 0 "Block" ;
VAL_ 2365464318 Valve14ValveState 15 "DoNotCare" 14 "ErrorIndication" 3 "Floating" 2 "Retract" 1 "Extend" 0 "Blocked" ;
VAL_ 2365464062 Valve13LimitStatus 0 "Not limited" 1 "Operator Limited" 2 "Limited High" 3 "Limited Low" 4 "Reserved" 5 "Reserver" 6 "Non-recoverable Fault" 7 "Not available" ;
VAL_ 2365464062 Valve13FailSafeMode 3 "NotAvailable" 2 "ErrorIndication" 1 "Float" 0 "Block" ;
VAL_ 2365464062 Valve13ValveState 15 "DoNotCare" 14 "ErrorIndication" 3 "Floating" 2 "Retract" 1 "Extend" 0 "Blocked" ;
VAL_ 2365463806 Valve12LimitStatus 0 "Not limited" 1 "Operator Limited" 2 "Limited High" 3 "Limited Low" 4 "Reserved" 5 "Reserver" 6 "Non-recoverable Fault" 7 "Not available" ;
VAL_ 2365463806 Valve12FailSafeMode 3 "NotAvailable" 2 "ErrorIndication" 1 "Float" 0 "Block" ;
VAL_ 2365463806 Valve12ValveState 15 "DoNotCare" 14 "ErrorIndication" 3 "Floating" 2 "Retract" 1 "Extend" 0 "Blocked" ;
VAL_ 2365463550 Valve11LimitStatus 0 "Not limited" 1 "Operator Limited" 2 "Limited High" 3 "Limited Low" 4 "Reserved" 5 "Reserver" 6 "Non-recoverable Fault" 7 "Not available" ;
VAL_ 2365463550 Valve11FailSafeMode 3 "NotAvailable" 2 "ErrorIndication" 1 "Float" 0 "Block" ;
VAL_ 2365463550 Valve11ValveState 15 "DoNotCare" 14 "ErrorIndication" 3 "Floating" 2 "Retract" 1 "Extend" 0 "Blocked" ;
VAL_ 2365463294 Valve10LimitStatus 0 "Not limited" 1 "Operator Limited" 2 "Limited High" 3 "Limited Low" 4 "Reserved" 5 "Reserver" 6 "Non-recoverable Fault" 7 "Not available" ;
VAL_ 2365463294 Valve10FailSafeMode 3 "NotAvailable" 2 "ErrorIndication" 1 "Float" 0 "Block" ;
VAL_ 2365463294 Valve10ValveState 15 "DoNotCare" 14 "ErrorIndication" 3 "Floating" 2 "Retract" 1 "Extend" 0 "Blocked" ;
VAL_ 2365463038 Valve9LimitStatus 0 "Not limited" 1 "Operator Limited" 2 "Limited High" 3 "Limited Low" 4 "Reserved" 5 "Reserver" 6 "Non-recoverable Fault" 7 "Not available" ;
VAL_ 2365463038 Valve9FailSafeMode 3 "NotAvailable" 2 "ErrorIndication" 1 "Float" 0 "Block" ;
VAL_ 2365463038 Valve9ValveState 15 "DoNotCare" 14 "ErrorIndication" 3 "Floating" 2 "Retract" 1 "Extend" 0 "Blocked" ;
VAL_ 2365462782 Valve8LimitStatus 0 "Not limited" 1 "Operator Limited" 2 "Limited High" 3 "Limited Low" 4 "Reserved" 5 "Reserver" 6 "Non-recoverable Fault" 7 "Not available" ;
VAL_ 2365462782 Valve8FailSafeMode 3 "NotAvailable" 2 "ErrorIndication" 1 "Float" 0 "Block" ;
VAL_ 2365462782 Valve8ValveState 15 "DoNotCare" 14 "ErrorIndication" 3 "Floating" 2 "Retract" 1 "Extend" 0 "Blocked" ;
VAL_ 2365462526 Valve7LimitStatus 0 "Not limited" 1 "Operator Limited" 2 "Limited High" 3 "Limited Low" 4 "Reserved" 5 "Reserver" 6 "Non-recoverable Fault" 7 "Not available" ;
VAL_ 2365462526 Valve7FailSafeMode 3 "NotAvailable" 2 "ErrorIndication" 1 "Float" 0 "Block" ;
VAL_ 2365462526 Valve7ValveState 15 "DoNotCare" 14 "ErrorIndication" 3 "Floating" 2 "Retract" 1 "Extend" 0 "Blocked" ;
VAL_ 2365462270 Valve6LimitStatus 0 "Not limited" 1 "Operator Limited" 2 "Limited High" 3 "Limited Low" 4 "Reserved" 5 "Reserver" 6 "Non-recoverable Fault" 7 "Not available" ;
VAL_ 2365462270 Valve6FailSafeMode 3 "NotAvailable" 2 "ErrorIndication" 1 "Float" 0 "Block" ;
VAL_ 2365462270 Valve6ValveState 15 "DoNotCare" 14 "ErrorIndication" 3 "Floating" 2 "Retract" 1 "Extend" 0 "Blocked" ;
VAL_ 2365462014 Valve5LimitStatus 0 "Not limited" 1 "Operator Limited" 2 "Limited High" 3 "Limited Low" 4 "Reserved" 5 "Reserver" 6 "Non-recoverable Fault" 7 "Not available" ;
VAL_ 2365462014 Valve5FailSafeMode 3 "NotAvailable" 2 "ErrorIndication" 1 "Float" 0 "Block" ;
VAL_ 2365462014 Valve5ValveState 15 "DoNotCare" 14 "ErrorIndication" 3 "Floating" 2 "Retract" 1 "Extend" 0 "Blocked" ;
VAL_ 2365461758 Valve4LimitStatus 0 "Not limited" 1 "Operator Limited" 2 "Limited High" 3 "Limited Low" 4 "Reserved" 5 "Reserver" 6 "Non-recoverable Fault" 7 "Not available" ;
VAL_ 2365461758 Valve4FailSafeMode 3 "NotAvailable" 2 "ErrorIndication" 1 "Float" 0 "Block" ;
VAL_ 2365461758 Valve4ValveState 15 "DoNotCare" 14 "ErrorIndication" 3 "Floating" 2 "Retract" 1 "Extend" 0 "Blocked" ;
VAL_ 2365461502 Valve3LimitStatus 0 "Not limited" 1 "Operator Limited" 2 "Limited High" 3 "Limited Low" 4 "Reserved" 5 "Reserver" 6 "Non-recoverable Fault" 7 "Not available" ;
VAL_ 2365461502 Valve3FailSafeMode 3 "NotAvailable" 2 "ErrorIndication" 1 "Float" 0 "Block" ;
VAL_ 2365461502 Valve3ValveState 15 "DoNotCare" 14 "ErrorIndication" 3 "Floating" 2 "Retract" 1 "Extend" 0 "Blocked" ;
VAL_ 2365461246 Valve2LimitStatus 0 "Not limited" 1 "Operator Limited" 2 "Limited High" 3 "Limited Low" 4 "Reserved" 5 "Reserver" 6 "Non-recoverable Fault" 7 "Not available" ;
VAL_ 2365461246 Valve2FailSafeMode 3 "NotAvailable" 2 "ErrorIndication" 1 "Float" 0 "Block" ;
VAL_ 2365461246 Valve2ValveState 15 "DoNotCare" 14 "ErrorIndication" 3 "Floating" 2 "Retract" 1 "Extend" 0 "Blocked" ;
VAL_ 2365460990 Valve1LimitStatus 0 "Not limited" 1 "Operator Limited" 2 "Limited High" 3 "Limited Low" 4 "Reserved" 5 "Reserver" 6 "Non-recoverable Fault" 7 "Not available" ;
VAL_ 2365460990 Valve1FailSafeMode 3 "NotAvailable" 2 "ErrorIndication" 1 "Float" 0 "Block" ;
VAL_ 2365460990 Valve1ValveState 15 "DoNotCare" 14 "ErrorIndication" 3 "Floating" 2 "Retract" 1 "Extend" 0 "Blocked" ;
VAL_ 2365460734 AuxValveNum0ExitReasonCode 0 "No reason/all clear " 1 "Operator presence not detected " 2 "Implement released control of function " 3 "Operator override of function " 4 "Operator control not in valid position " 5 "Remote command timeout " 6 "Remote command out of range/invalid " 7 "Function not calibrated " 8 "Operator control fault " 9 "Function fault " 20 "Hydraulic oil level too low " 21 "Valve locked out" 62 "Error " 63 "Not available (parameter not supported)" ;
VAL_ 2365460734 Valve0LimitStatus 0 "Not limited" 1 "Operator Limited" 2 "Limited High" 3 "Limited Low" 4 "Reserved" 5 "Reserver" 6 "Non-recoverable Fault" 7 "Not available" ;
VAL_ 2365460734 Valve0FailSafeMode 3 "NotAvailable" 2 "ErrorIndication" 1 "Float" 0 "Block" ;
VAL_ 2365460734 Valve0ValveState 15 "DoNotCare" 14 "ErrorIndication" 3 "Floating" 2 "Retract" 1 "Extend" 0 "Blocked" ;
VAL_ 2566787070 TemperatureUnits 3 "NoAction" 2 "Reserved" 1 "Imperial" 0 "Metric" ;
VAL_ 2566787070 PressureUnits 3 "NoAction" 2 "Reserved" 1 "Imperial" 0 "Metric" ;
VAL_ 2566787070 ForceUnits 3 "NoAction" 2 "Reserved" 1 "Imperial" 0 "Metric" ;
VAL_ 2566787070 UnitsSystem 3 "NoAction" 2 "US" 1 "Imperial" 0 "Metric" ;
VAL_ 2566787070 DistanceUnitCmd 3 "NoAction" 1 "Imperial" 0 "Metric" ;
VAL_ 2566787070 AreaUnitCmd 3 "NoAction" 1 "Imperial" 0 "Metric" ;
VAL_ 2566787070 VolumeUnitCmd 3 "NoAction" 2 "US" 1 "Imperial" 0 "Metric" ;
VAL_ 2566787070 MassUnitCmd 3 "NoAction" 2 "TonsPounds" 1 "Imperial" 0 "Metric" ;
VAL_ 2566787070 DateFormatCmd 5 "yyyyddmm" 4 "yyyymmdd" 3 "mmddyyyy" 2 "mmyyyydd" 1 "ddyyyymm" 0 "ddmmyyyy" ;
VAL_ 2566787070 DecimalSymbolCmd 3 "NoAction" 1 "PointIsUsed" 0 "CommaIsUsed" ;
VAL_ 2566787070 TimeFormatCmd 3 "NoAction" 1 "Hour12" 0 "Hour24" ;
VAL_ 2633895166 Function 43 "Transmission Display" 44 "Exhaust Emission Control" 45 "Vehicle Dynamic Stability Control" 46 "Oil Sensor Unit" 47 "Information System Controller" 48 "Ramp Control" 49 "Clutch/Converter Control" 50 "Auxiliary Heater" 51 "Forward-Looking Collision Warning System" 52 "Chassis Controller" 53 "Alternator/Charging System" 54 "Communications Unit, Cellular" 55 "Communications Unit, Satellite" 56 "Communications Unit, Radio" 57 "Steering Column Unit" 58 "Fan Drive Control" 59 "Starter" 60 "Cab Display" 61 "File Server/Printer" 62 "On-Board Diagnostic Unit" 63 "Engine Valve Controller" 64 "Endurance Braking" 65 "Gas Flow Measurement" 66 "I/O Controller" 67 "Electrical System Controller" 68 "Aftertreatment system gas measurement" 69 "Engine Emission Aftertreatement System" 70 "Auxiliary Regeneration Device" 71 "Transfer Case Control" 72 "Coolant Valve Controller" 73 "Rollover Detection Control" 74 "Lubrication System" 75 "Supplemental Fan" 76 "Temperature Sensor" 77 "Fuel Properties Sensor" 78 "Fire Suppression System" 79 "Power Systems Manager" 80 "Electric Powertrain" 81 "Hydraulic Powertrain" 82 "File Server" 83 "Printer" 84 "Start Aid Device" 85 "Engine Injection Control Module" 86 "Reserved" 87 "Reserved" 88 "Reserved" 89 "Reserved" 90 "Reserved" 91 "Reserved" 92 "Reserved" 93 "Reserved" 94 "Reserved" 95 "Reserved" 96 "Reserved" 97 "Reserved" 98 "Reserved" 99 "Reserved" 100 "Reserved" 0 "Engine" 1 "Auxiliary Power Unit (APU)" 2 "Electric Propulsion Control" 3 "Transmission" 4 "Battery Pack Monitor" 5 "Shift Control/Console" 6 "Power TakeOff - (Main or Rear)" 7 "Axle - Steering" 8 "Axle - Drive" 9 "Brakes - System Controller" 10 "Brakes - Steer Axle" 11 "Brakes - Drive Axle" 12 "Retarder - Engine" 13 "Retarder - Driveline" 14 "Cruise Control" 15 "Fuel System" 16 "Steering Controller" 17 "Suspension - Steer Axle" 18 "Suspension - Drive Axle" 19 "Instrument Cluster" 20 "Trip Recorder" 21 "Cab Climate Control" 22 "Aerodynamic Control" 23 "Vehicle Navigation" 24 "Vehicle Security" 25 "Network Interconnect ECU" 26 "Body Controller" 27 "Power TakeOff (Secondary or Front)" 28 "Off Vehicle Gateway" 29 "Virtual Terminal (in cab)" 30 "Management Computer" 31 "Propulsion Battery Charger" 32 "Headway Controller" 33 "System Monitor" 34 "Hydraulic Pump Controller" 35 "Suspension - System Controller" 36 "Pneumatic - System Controller" 37 "Cab Controller" 38 "Tire Pressure Control" 39 "Ignition Control Module" 40 "Seat Control" 41 "Lighting - Operator Controls" 42 "Water Pump Control" 101 "Reserved" 102 "Reserved" 103 "Reserved" 104 "Reserved" 105 "Reserved" 106 "Reserved" 107 "Reserved" 108 "Reserved" 109 "Reserved" 110 "Reserved" 111 "Reserved" 112 "Reserved" 113 "Reserved" 114 "Reserved" 115 "Reserved" 116 "Reserved" 117 "Reserved" 118 "Reserved" 119 "Reserved" 120 "Reserved" 121 "Reserved" 122 "Reserved" 123 "Reserved" 124 "Reserved" 125 "Reserved" 126 "Reserved" 127 "Reserved" 255 "Not Available" ;
VAL_ 2633895166 IndustryGroup 7 "Reserved for SAE" 5 "IndustrialProcessCtrlStationary" 4 "Marine" 3 "Construction" 2 "AgriculturalAndForestry" 1 "On-Highway" 0 "Global" 6 "Reserved for SAE" ;
VAL_ 2633895166 ManufacturerCode 1863 "Thomas G. Faria Co." 1862 "Sanshin" 1861 "Vector North America " 1860 "MMP" 1859 "Kvasar AB" 1858 "Litton" 1857 "Simrad" 1856 "Trimble" 1855 "Furuno USA" 1854 "Northstar Technologies" 1853 "Japan Radio Co" 1852 "Navionics" 1851 "RayMarine" 1850 "Teleflex" 786 "Johnson Matthey Battery Systems" 785 "Fischer Panda GmbH" 784 "CM Automotive Systems, Inc." 783 "Loup Electronics Inc." 782 "AVR bvba" 781 "Poly-Planar LLC" 780 "AVID Technology Ltd" 779 "RLC Electronic Systems" 778 "Seakeeper Inc." 777 "Ocean Signal Ltd" 776 "HMI Systems LLC" 775 "ZIEHL-ABEGG Automotive GmbH" 774 "Taisho Corporation" 773 "Clarion Corporation of America" 772 "Blink Marine" 771 "Shaw Development, LLC" 770 "MONOSEM" 769 "Trombetta" 768 "Flores Automation, LLC" 767 "Alliance Wireless Technologies Inc." 766 "Epec Oy" 765 "GIGAVAC" 764 "Bednar FMT s.r.o." 763 "AT-Systems BVBA" 762 "ROJ s.r.l." 761 "MITA OLEODINAMICA S.p.A." 760 "Bernecker + Rainer Industrie Elektronik GmbH" 759 "Hydro-Gear" 758 "Banner Engineering Corp." 757 "IMPCO Technologies" 756 "Maschio Gaspardo S.P.A." 755 "Firefly Integrations" 754 "Parker Hannifin Corp., Automation Group" 753 "AIROD Technologies" 752 "Deep Sea Electronics Plc" 751 "Pacific Track" 750 "Joskin SA" 749 "Chart Inc." 748 "ISOTTA" 747 "Agratronix" 746 "SureFire Ag Systems, Inc." 745 "Cidra Corporate Services Inc." 744 "Woosung Engineering Co., Ltd." 743 "Daemyung Elevator Co., Ltd." 742 "EROAD" 741 "Carling Technologies" 740 "e-Traction" 739 "LXNAV d.o.o." 738 "Blue Ink Technologies" 737 "Balluff GmbH" 736 "Terex Aerial Work Platforms - Genie" 735 "AEM Performance Electronics" 734 "REAPsystems" 733 "Intendia S.L." 732 "Gefran S.p.A." 731 "Modine Manufacturing Company" 730 "BERTHOUD AGRICOLE" 729 "Liebherr" 728 "Streumaster / Panien" 727 "Dhoot Transmission Pvt Ltd." 726 "MIDORI PRECISIONS" 725 "Hitachi Construction Machinery Co., Ltd." 724 "Electronic Applications, Inc." 723 "Jabil Inc." 722 "Contelec AG" 721 "Hypro" 720 "WITZ Corporation" 719 "Cojali S. L." 718 "Micronet Inc" 717 "Yacht Devices Ltd" 716 "Eaton Control & Power Conversion Division (CPCD)" 715 "Autonnic Research Ltd" 714 "Kobashi Kogyo Co., Ltd." 713 "US Hybrid Corporation" 712 "LOR Manufacturing Company Inc." 711 "DAS Co., LTD" 710 "Greentronics Ltd." 709 "Marquardt GmbH" 708 "Lars Thrane A/S" 707 "Rochester Gauges Inc" 706 "Shanghai Diesel Engine Corporation Limited" 705 "SVAB Hydraulik AB" 704 "JL Audio, Inc." 703 "Hydro Tab Marine Engineering" 702 "Weichai Power Co., Ltd." 701 "BigRoad Inc." 700 "K-Tec Earthmovers Inc." 699 "Harman International Industries" 698 "Scorpion Technologies Ltd." 697 "Ålö AB" 696 "DRS Network & Imaging Systems, LLC (DRS Technologies)" 695 "Weldon Technologies" 694 "GasTOPS Ltd." 693 "Agility Fuel Solutions (formerly Agility Fuel Systems)" 692 "Tanhay Corporation" 691 "Digitroll Agricultural Electronics" 690 "LINAK A/S" 689 "Aarcomm Systems Inc" 688 "Rockford Corp" 687 "Flight Systems, Inc." 686 "Taigene Electric Machinery Corp." 685 "ANEDO Ltd." 684 "KEB" 683 "Fosen Elektro" 682 "Eckelmann AG" 681 "BEDIA Motorentechnik GmbH & Co. KG" 680 "AMVAC Chemical Corporation" 679 "Cimco Marine AB" 678 "KeepTruckin, Inc." 677 "DSA Daten- und Systemtechnik GmbH" 676 "Danfoss IXA A/S" 675 "Kawasaki Motors Corp., USA" 674 "Yara International ASA" 673 "Caruelle Nicolas" 672 "OPTIMA Concept" 671 "Innovative Controls Inc." 670 "STEMCO LP" 669 "Quantum Fuel Systems Technologies Worldwide, Inc" 668 "MacDon Industries Ltd." 667 "Bartec" 666 "Schaeffler Technologies AG & Co., KG" 665 "Gebr. Bode GmbH & Co. KG" 664 "Level Developments Ltd" 663 "Delta Systems, Inc" 662 "Kissling Elektrotechnik GmbH" 661 "SPAL Automotive S.r.l." 660 "Auto-Gaz Centrum" 659 "Data Panel Corp." 658 "Shenzhen Jiuzhou Himunication Technology Co., Ltd" 657 "Terzo Power Systems" 656 "PRO SOLUS do Brasil" 655 "Genge & Thoma AG" 654 "Kohler Power Systems, Detroit Engine Development Center (DEDC)" 653 "AEV, spol. s r. o." 652 "MicroControl GmbH & Co. KG" 651 "Takakita Co, Ltd." 650 "Seiko Epson Corp." 649 "Control-Q BV" 648 "OJSC Ekran" 647 "Siloking" 646 "Veenhuis Machines BV" 645 "esd electronic system design gmbh" 644 "KUS USA" 643 "Bogballe A/S" 642 "Moog / Aspen Motion Technologies" 641 "Diverse Yacht Services" 640 "Power Solutions International" 639 "Startec s.r.l." 638 "KVH Industries, Inc." 637 "Bavaria Yachtbau GmbH" 636 "Divelbiss Corporation" 635 "Argo Tractors S.p.A." 634 "Rocky Research" 633 "TORC Robotics" 632 "Pepperl+Fuchs GmbH" 631 "Reltima" 630 "SmartDrive Systems Inc." 629 "Agri Info Design, Ltd." 524 "Vomax Instrumentation Pty. Ltd." 523 "Reggio Emilia Innovazione" 522 "Nebraska Tractor Test Laboratory" 521 "Clever Devices Ltd." 520 "Trapeze" 519 "Peeters Landbouwmachines b.v." 518 "Transas USA Inc." 517 "Noland Engineering" 516 "AVAT Automation GmbH" 515 "GINAF Trucks Nederland B.V." 514 "DISTek Integration, Inc." 513 "FarmscanAg" 512 "Inpower LLC" 511 "Sulky" 510 "Marinesoft Co. Ltd" 509 "MOTORTECH GmbH" 508 "Transtech Innovations" 507 "ISOBUS Test Center" 506 "IHI STAR Machinery Corporation" 505 "Yetter Farm Equipment" 504 "Vesper Marine" 503 "Naviop S.R.L." 502 "Attwood Corporation" 501 "Agrotronix S.A." 500 "Oxbo International Corporation" 499 "LCJ Capteurs" 498 "Innovative Design Solutions, Inc." 497 "SENTRON Sistemas Embarcados" 496 "W. Gessmann GmbH" 495 "HOLMER Maschinenbau GmbH" 494 "Synerject" 493 "Watcheye" 492 "Inergy Automotive Systems" 491 "Penny and Giles Ltd" 490 "QuikQ" 489 "Appareo Systems, LLC" 488 "The Charles Machine Works, Inc." 487 "DSE Test Solutions A/S" 486 "Westport Innovations Inc." 485 "MATT automotive" 484 "Headsight Inc." 483 "Valeo" 482 "Tricon Electronics" 481 "Chetco Digital Instruments" 480 "EnerDel, Inc." 479 "Vapor Bus International" 478 "OceanSat BV" 477 "OilQuick AB" 476 "Hummingbird Marine Electronics" 475 "GME" 474 "Persen Technologies Inc." 473 "Boss Industries, Inc." 472 "Tenneco Inc." 471 "Sea Cross Marine AB" 628 "Falck Schmidt Defence Systems" 627 "Radio Ocean" 626 "AVL DiTEST GmbH" 625 "Global MRV Inc." 624 "Blackbox Machine Control Pty Ltd" 623 "Xirgo Technologies" 622 "Floyd Bell Inc" 621 "Hagie Manufacturing Company" 620 "Sevcon Ltd." 619 "Right Weigh Load Scales" 618 "Evrard SA" 617 "Zero Emission Vehicles" 616 "SMART-TEC s.r.o." 615 "Networkfleet, Verizon Telematics" 614 "ARLT Technologies GmbH" 613 "HKS Co., Ltd." 612 "Samwon IT" 611 "Esterline" 610 "Trail Tech" 609 "Walvoil S.p.A." 608 "Gale Banks Engineering" 607 "Knappco/Civacon" 606 "Intellian Technologies" 605 "Aventics GmbH" 604 "Indexator Rototilt Systems AB" 603 "Kereval" 602 "Nomad Digital Ltd." 601 "Navitas Systems" 600 "Aquatic AV" 599 "Spudnik Equipment Co, LLC" 598 "ABB Turbo Systems Ltd" 597 "Hydac Filter Systems GmbH" 596 "Brunelco Electronic Innovators B.V." 595 "CustomWare" 594 "Kongsberg Automotive" 593 "Sensata Technologies" 592 "tecsis GmbH" 591 "United States Coast Guard" 590 "ARGO-HYTOS GMBH" 589 "MICO, Inc." 588 "Vignal Systems" 587 "JCA Electronics" 586 "Suzuki Motor Corp" 585 "Industrial Electronic Controls" 584 "CarMedialab GmbH" 583 "Yachtcontrol" 582 "Innovative Software Engineering" 581 "Väderstad - Verken AB" 580 "San Jose Technology, Inc." 579 "KVH Industries, Inc." 578 "advanSea" 577 "Denchi Power Ltd  (formerly ABSL Power Solutions Limited)" 576 "Vectia" 575 "Lytx" 574 "Vishay Precision Group" 573 "Orolia Ltd" 572 "Fasse Valves" 571 "Marinecraft Co., Ltd." 570 "frenzel + berg electronic GmbH & Co. KG" 569 "LORD MicroStrain Sensing Systems" 568 "Makersan Ltd. Co." 567 "Lithiumstart LLC" 566 "Geode Technology, Inc." 565 "Micro-Trak Systems, Inc." 564 "Auto Power Electronic" 563 "LOHR Sistemas Eletronicos LTDA" 562 "Bombardier Transportation GmbH" 561 "b-plus GmbH" 560 "Iowa State University, Agricultural and Biosystems Engineering" 559 "Four Peaks Navigation" 558 "Davis Instruments Corp." 557 "Rockson Automation GmbH" 556 "Doosan Infracore Norway" 555 "Sasaki Corporation" 554 "iris-GmbH infrared & intelligent sensors" 553 "KIB Electronics" 552 "Matsuyama Plow Mfg Co, Ltd" 551 "Wexler CSD Ltd." 550 "SUN-A Corporation" 549 "ROAD Deutschland GmbH" 548 "TM4 Inc." 547 "Thomson Linear LLC" 546 "Maruyama Mfg Co, Inc." 545 "GS Hydraulics" 544 "Au Group Electronics" 543 "BAUER Maschinen GmbH" 542 "Dinamica Generale s.p.a." 541 "Total Fire Systems, Inc." 540 "Dinex A/S" 539 "Mobileview" 538 "Crop Ventures, Inc." 537 "Schrader Electronics Ltd." 536 "SSI Technologies" 535 "MOTORPAL, a.s." 534 "Webasto Thermo & Comfort SE" 533 "Doran Manufacturing, LLC" 532 "Onwa Marine Electronics Co Ltd." 531 "Genge & Thoma AG" 530 "NMEA" 529 "National Instruments Korea" 528 "Hoganas AB, Electric Drive Systems" 527 "GKN Walterscheid GmbH" 526 "LOFA Industries, Inc" 525 "Rust Sales INC" 470 "SI-TEX Marine Electronics" 469 "RA Consulting GmbH" 468 "Tyco Fire Protection Products" 467 "Lely Industries N.V." 466 "Veethree Electronics and Marine LLC" 465 "Ashcroft Inc" 464 "Leach International Corporation" 463 "PROBOTIQ" 462 "IHI Shibaura Machinery Corporation" 461 "HAWE Hydraulik SE" 460 "San Giorgio S.E.I.N." 459 "Alltek Marine Electronics Corp" 458 "Control Solutions, Inc." 457 "RUSELPROM-ElectricDrive Ltd" 456 "General Kinetics" 455 "ADZ NAGANO GmbH" 454 "NGK Spark Plug Co. Ltd" 453 "Cooper Bussmann" 452 "WIKA Alexander Wiegand SE & Co. KG" 451 "Parker Hannifin Corp" 450 "Dycor Technologies Ltd." 449 "Polaris Industries Inc" 448 "Stanadyne Corporation, Electronics Systems" 447 "Great Plains Mfg." 446 "CertTech, L.L.C." 445 "KAT MECHATRONIC, Electronic Product Division" 444 "ITT Power Solutions" 443 "SignalQuest, Inc." 442 "Horsch Maschinen GmbH" 441 "PTG Reifendruckregelsysteme GmbH" 440 "Cummins Power Generation" 439 "Hyundai Heavy Industries" 438 "Comar Systems Ltd" 437 "Digital Yacht Limited" 436 "Kinze Manufacturing" 435 "Zunhammer GmbH" 434 "Stored Energy Systems" 433 "Rowe Electronics" 432 "S&A Systems, Inc." 431 "Tohatsu Corporation" 430 "Auteq Telematica S.A." 429 "Rota Engineering Ltd." 425 "Methode Electronics Inc, MDI" 424 "Odyne LLC" 423 "BSM Wireless, Inc." 422 "True Heading AB" 421 "Vertex Standard Co, Ltd" 420 "Vermeer Corporation, ACS Group" 419 "Fusion Electronics Ltd" 418 "Intellistick Inc" 417 "KZValve" 416 "Kubota Corporation" 415 "Valid Manufacturing Ltd." 414 "Cattron Group International" 413 "Datapross Nijbroek bv" 412 "WebTech Wireless Inc." 411 "Hy-Drive Technologies Ltd." 410 "COBO S.p.A. Divisione 3B6" 409 "Transfluid S.r.L." 408 "Corvus Energy Ltd." 407 "Comtech Mobile Datacom" 406 "Vecima Networks Inc." 405 "Wema System AS" 404 "Com Nav Marine Ltd" 403 "Trackwell ADS, Inc." 402 "Simma Software, Inc." 401 "Torqeedo GmbH" 400 "Livorsi Marine" 399 "ISEKI & Co., Ltd." 398 "Hilite International" 397 "Sanyo-kiki Co Ltd." 396 "Beyond Measure" 395 "GENTEC S.R.L." 394 "Capi 2 Nederland BV" 393 "Harvest Tec, Inc" 392 "Tianyuan Technology Co Ltd." 391 "Electronic Design for Industry, Inc" 390 "Partech Inc." 389 "Benchmark Electronics, Minnesota Division" 388 "Innomatix, LLC" 387 "Orscheln Products, LLC" 386 "JLG Automation BVBA" 385 "Johnson Outdoor Marine Electronics" 384 "Camano Light" 383 "MCL Industries" 382 "National Agriculture and Food Research Organization" 381 "B & G" 380 "Suntech International Ltd." 379 "Yamabiko Corporation" 378 "Glendinning Marine Products" 377 "ifm electronic gmbh" 376 "Quake Global" 375 "Williams Controls Inc." 374 "Northern Lights, Inc." 373 "Electronic Design Inc." 372 "Delphi" 371 "Heinzmann GmbH & Co. KG" 370 "Rolls-Royce Marine AS" 369 "Power Torque Engineering Ltd" 368 "HANSENHOF_electronic" 367 "Fliegl Agrartechnik" 366 "Viewnyx Corp." 365 "Digi-Star, LLC" 364 "OEM Controls Inc." 363 "BEI Duncan" 362 "Poettinger Landtechnik GmbH (formerly Alois Poettinger Maschinenfabrik GmbH)" 361 "InMach" 360 "HJS Emission Technology GmbH & Co KG   (formerly HJS Fahrzeugtechnik GmbH & Co KG)" 359 "Ludwig Bergmann GmbH" 358 "Victron Energy BV" 357 "Hardi International A/S" 356 "Fischer Panda Generators, Inc" 355 "Mastervolt International B.V." 354 "Junkkari OY" 353 "Hegemon Electronics, Inc." 352 "SAME DEUTZ-FAHR GROUP S.p.A." 351 "Thrane & Thrane" 350 "Noris Marine Systems GmbH & Co KG" 349 "Suonentieto" 348 "Amazonen Werke H. Dreyer" 347 "Honeywell" 346 "Control Solutions" 345 "Korean Maritime University" 344 "Parvus Corporation" 343 "Baumer Group" 342 "THOMAS MAGNETE GmbH" 341 "Boning GmbH & Co" 340 "Continental AG" 339 "Competence Center ISOBUS e.V." 338 "GRAF-SYTECO" 337 "Carraro S.p.A." 336 "APE s.r.o." 335 "Evo Electric Ltd" 334 "Takata-Petri AG" 333 "Hadley Products Corporation" 332 "HWH Corporation" 331 "Horton, Inc." 330 "Kidde Aerospace and Defense" 329 "Deif A/S" 328 "Qwerty Electronik AB" 327 "Sonceboz SA" 326 "Akron Brass Company" 325 "ASM Automation Sensorik Messtechnik GmbH" 324 "Snap-on Diagnostics" 323 "Mobileye Vision Technologies Ltd." 322 "MICHENKA s.r.o." 321 "Ultra Electronics, Electrics" 320 "Miedema Landbouwwerktuigenfabriek B.V." 319 "Cadec Global" 318 "SAT Plan" 317 "Navtronics Bvba" 263 "IMMI" 262 "HydraForce, Inc" 261 "Red Dot Corporation" 260 "Reichhardt GmbH Steuerungstechnik" 259 "Jetter AG" 258 "ARAG" 257 "Honda Motor Co., Ltd" 256 "Tyco Electronics AMP" 255 "MEAS France" 254 "GE Sensing" 253 "Mobile Control Systems" 252 "Sensor-Technik Wiedemann GmbH" 251 "German Agricultural Society, Test Center (DLG)" 250 "Kuhn Group" 249 "Schaltbau GmbH" 248 "Cooper Standard Automotive Active Systems Group" 247 "ePULSE" 246 "Class 1, Inc" 245 "Capstan Ag Systems, Inc." 244 "Techno-Matic" 243 "eRide, Inc." 242 "Kokusandenki Co. Ltd" 241 "Schneider Automation SAS" 240 "Vanair Mfg" 239 "May & Scofield Ltd" 238 "ZF Friedrichshafen AG" 237 "Agtron Enterprises Inc" 236 "NORAC Systems International Inc" 235 "SailorMade Marine Telemetry - Tetra Technology Ltd." 234 "Mondial electronic GmbH" 233 "Yacht Monitoring Solutions Inc." 232 "TSD Integrated Controls" 231 "Topcon Positioning Systems, Inc." 230 "Saucon Technologies" 229 "Garmin International Inc." 228 "Unused (formerly ZF Marine Electronics)" 227 "Lykketronic A/S" 226 "Monaco Coach Corporation" 225 "SKF" 224 "EMMI Network, S.L." 223 "Vaueo Retarder Co., Ltd." 222 "Generac Power Systems, Inc." 221 "SiE" 220 "Beede Electrical Instrument Company, Inc" 219 "Cat OEM Solutions" 218 "Gits Manufacturing Company" 217 "RM Michaelides Software & Elektronik GmbH" 216 "Paneltronics Inc." 215 "Aetna Engineering/Fireboy-Xintex" 214 "MC elettronica Srl" 164 "MTU Friedrichshafen GmbH (formerly DaimlerChrysler Off-Highway)" 163 "BRP Inc." 162 "Axiomatic Technologies" 161 "Offshore Systems (UK) Ltd" 160 "Nido" 159 "NTech Industries Inc" 158 "Firestone Industrial Products Company" 157 "ISSPRO Inc." 156 "ITT Industries - Cannon" 155 "Vetronix Corporation" 154 "Westerbeke Corporation" 153 "Woodward, Industrial Controls Division" 152 "elobau GmbH & Co. KG" 151 "Raven Industries, Inc." 150 "Fleetguard" 149 "Holset" 148 "Blue Water Data, Inc." 147 "Nautibus electronic GmbH" 146 "Maxima Technologies" 145 "MurCal Controls" 144 "Mercury Marine" 143 "W. Gmeiner GmbH & Co." 142 "TRW Automotive (Commercial Steering Systems)" 141 "Thales Navigation Ltd." 140 "Lowrance Electronics, Inc." 139 "Caterpillar Trimble Control Technologies (CTCT), LLC" 138 "Georg Fritzmeier GmbH & Co. KG" 137 "Maretron" 136 "Komatsu Ltd" 135 "Airmar Technology Corporation" 134 "Iris Technology Ltd" 133 "Bucher Schoerling GmbH" 132 "Mulag-Fahrzeugwerk" 131 "ITT Industries" 130 "Nido - Universal Machines B.V." 129 "OMNEX Control Systems Inc." 128 "Gerhard Duecker GmbH & Co. KG" 127 "Holland USA" 126 "Driver Tech" 125 "Nevada Automotive Test Center" 124 "Hydac Electronic" 123 "Basler Electric" 122 "FG Wilson (Engineering) Limited" 121 "HED (Hydro Electronic Devices, Inc.)" 120 "RDS Technology Ltd" 119 "IntegriNautics  " 118 "Intron GmbH" 117 "HUSCO International" 116 "BEELINE Technologies" 115 "NACCO Materials Handling Group, Inc." 114 "EControls, Inc." 113 "Stress-Tek, Inc." 112 "MECALAC" 111 "Maschinenfabrik Bernard Krone GmbH" 110 "EPIQ Sensor-Nite" 109 "TeeJet Technologies Denmark (formerly LH Technologies ApS)" 108 "WTK-Elecktronik GmbH" 107 "Grimme Landmaschinen GmbH & Co. KG" 106 "BAE Systems Controls, Inc." 105 "Kiepe Elektrik GmbH & Co. KG" 104 "CLAAS KGaA mbH (formerly CLAAS Selbstfahrende Erntemaschinen GmbH)" 103 "CLAAS E-Systems KGaA mbH & Co. KG (formerly CLAAS Agrosystems GmbH & Co. KG)" 102 "AGCO (formerly AGCO GmbH & Co.)" 101 "Sensoria" 100 "VDO Technik AG" 99 "International Transmissions Ltd (ITL)" 98 "Mueller-Elektronik GmbH & Co" 97 "Ag Leader Technology, Inc." 96 "Mech@tronic IT GmbH" 95 "Pacific Insight Electronics Corp." 94 "CNH Industrial N.V. (formerly CNH Global N.V.)" 93 "Perkins Engines Company Ltd." 92 "Ag-Chem Equipment Co., Inc." 91 "BSG Bodensee Steuergeraete GmbH" 90 "Knorr-Bremse SfN GmbH" 89 "Kverneland Group, Electronics Division" 88 "Satloc Precision GPS" 87 "J.C. Bamford Excavators Ltd (JCB)" 86 "C. E. Niehoff & Company" 85 "Kohler Co" 84 "New Holland UK Limited" 83 "Bendix VORAD Technologies (formerly Eaton VORAD Technologies)" 82 "Bobcat/Ingersoll-Rand (formerly Melroe/Ingersoll-Rand)" 81 "Fire Research Corp." 80 "Twin Disc, Inc." 79 "Daimler Benz AG - Engine Division (PBM)" 78 "Frank W. Murphy Manufacturing, Inc" 77 "Deere Power Systems Group" 76 "unused (formerly Deere & Co, Construction Division)" 75 "Deere & Co, Agricultural Division" 74 "Eaton Axle-Brake Division" 73 "LeTourneau, Inc." 72 "Sisu Corporation" 71 "Vansco Electronics Ltd." 70 "Flex-coil Limited" 69 "Trimble Navigation" 316 "ITT Flow Control" 315 "Icom Incorporated" 314 "CSM GmbH" 313 "Ilmor Engineering, Inc." 312 "Lectronix, Inc." 311 "Patrick Power Products" 310 "TECNORD srl" 309 "Krauss-Maffei Wegmann GmbH & Co. KG" 308 "Cyntrx" 307 "MAS Technologies" 306 "Sleipner Motor AB" 305 "NovAtel Inc" 304 "EmpirBus AB" 303 "CTS Corporation" 302 "Nissin Kogyo Co., LTD" 301 "Parker Hannifin (UK) Ltd FDE group" 300 "Systron Donner Automotive" 299 "Rauch" 298 "Holley Performance" 297 "Zonar Systems Inc" 296 "micro dynamics GmbH" 295 "BEP Marine" 294 "Grayhill Inc." 293 "Spyder Controls Corp." 292 "IKUSI - Angel Iglesias S.A." 291 "Groeneveld Transport Efficiency BV" 290 "Kuebler GmbH" 289 "Watlow" 288 "Mitsubishi FUSO Truck & Bus Corp." 287 "NTech Industries, Inc" 286 "Coelmo srl" 285 "Sea Recovery Corp" 284 "Mobile Tech Chile" 283 "CWF Hamilton & Co Ltd" 282 "Medallion Instrumentation Systems" 281 "Precision Governors LLC" 280 "Leica Geosystems Pty Ltd" 279 "Geometris LP" 278 "Takata Electronics" 277 "LHP Telematics" 276 "Aqua-Hot Heating Systems" 275 "Navico Egersund AS" 274 "LTW Technology Co., LTD" 273 "Active Research Limited" 272 "Gross Mechanical Laboratories, Inc" 271 "Cole Hersee" 270 "Tennant" 269 "Saft America Inc.,  Space & Defense Division" 268 "Accurate Technologies" 267 "Red Lion Controls, Inc" 266 "International Thermal Research Ltd" 265 "MTS Sensor Technologie GmbH" 264 "Autolync" 213 "CNH Belgium N.V." 212 "Sure Power Industries, Inc" 211 "DNA Group" 210 "Iteris, Inc." 209 "Bell Equip. Co. SA (PTY) LTD" 208 "Drew Technologies, Inc" 207 "Otto Engineering" 206 "port GmbH" 205 "SmarTire Systems Inc" 204 "The Morey Corporation" 203 "MILtronik GmbH" 202 "Curtis Instruments, Inc" 201 "Disenos y Tecnologia S.A." 200 "MGM Brakes" 199 "Actia Corp" 198 "Mystic Valley Communications" 197 "Mechron Power Systems" 196 "LEMKEN GmbH & Co KG" 195 "General Engine Products" 194 "TriMark Corporation" 193 "Jeppesen Marine" 192 "Floscan" 191 "XRS Corporation (formerly XATA Corporation)" 190 "Hella KGaA Hueck & Co" 189 "QUALCOMM" 188 "EMP Corp" 187 "Air-Weigh" 186 "Altronic, Inc" 185 "Beede Electrical Instrument Company" 184 "EIA Electronics" 183 "KDS Controls, Inc" 182 "Vehicle Systems Engineering B.V." 181 "Coretronics, Inc." 180 "Smart Power Systems" 179 "TeeJet Technologies Springfield (formerly Midwest Technologies Illinois, LLC)" 178 "Continental Automotive GmbH (formerly Siemens VDO Automotive AG)" 177 "Diagnostic Systems Associates" 176 "Moritz Aerospace" 175 "Veris Technologies, Inc." 174 "AB Volvo Penta" 173 "Ryeso, Inc." 172 "Yanmar Co., Ltd. (formerly Yanmar Marine USA)" 171 "Wachendorff Elektronik GmbH & Co. KG" 170 "Computronics Corporation Ltd." 169 "Marlin Technologies Inc." 168 "Xantrex" 167 "JLG Industries Inc" 166 "John Deere Electronic Solutions (formerly Phoenix International)" 165 "CPAC Systems AB" 68 "Scania" 67 "John Deere Coffeyville Works (formerly Funk Manufacturing Company)" 66 "John Deere Construction Equipment Division" 65 "MAN Nutzfahrzeuge AG" 64 "Unused (formerly SpectraPrecision Laserplane, then SpectraPhysics)" 63 "ZF Industries Inc." 62 "Wabco" 61 "Volvo Truck Corp." 60 "Volvo Trucks North America Inc." 59 "VES Inc." 58 "SPX Corporation, OTC Div" 57 "Danfoss  (formerly Sauer Sundstrand Co, then Sauer-Danfoss Co)" 56 "SAIC" 55 "Ryder System Inc." 54 "Meritor Wabco" 53 "Continental Automotive Systems US, Inc. (formerly Rockwell Land Transportation)" 52 "Meritor Automotive, Inc. (formerly Rockwell Automotive)" 51 "Robert Bosch GmbH" 50 "Robert Bosch Corp" 49 "RE America Inc." 48 "Pollak Alphabet" 47 "Phillips Semiconductor" 46 "Noregon Systems, Inc  (formerly Parasoft Computing Solutions)" 45 "PACCAR" 44 "Nippondenso Co. Ltd." 43 "International Truck and Engine Corporation - Vehicle Electronics (formerly Navistar Intl Trans Corp.)" 42 "International Truck and Engine Corporation - Engine Electronics  (formerly Navistar Intl Trans Co., Engine Electronics)" 41 "Motorola Inc." 40 "Motorola AIEG Inc." 39 "Microfirm Inc." 38 "Micro Processor Systems Inc." 37 "Mack Trucks Inc." 36 "Lucas Ind." 35 "Kenworth Truck Co." 34 "Kelsey Hayes Co." 33 "John Deere" 32 "Jacobs Vehicle Systems" 31 "J Pollak Corp" 30 "Isuzu Motors Ltd" 29 "Hino Motors Ltd." 28 "Grote Ind. Inc." 27 "GMC" 26 "General Motors Corp, Service Technology Grp" 25 "Daimler Trucks North America LLC (formerly Freightliner LLC)" 24 "Ford Motor Co., Vehicle Controls" 23 "Ford Motor Co., Heavy Truck" 22 "Ford Motor Co., Electronic Concepts & Systems" 21 "Echlin Inc., Midland Brake Inc." 20 "Eaton Ltd" 19 "Eaton Corp. Trucking Info Services" 18 "Eaton Corp, Transmission Div." 17 "Eaton Corp, Corp Res & Dev" 16 "Eaton Corp" 15 "DICKEY-john Corporation" 14 "Detroit Diesel Corporation" 13 "Delco Electronics" 12 "Deere & Company, Precision Farming" 11 "Dearborn Group Inc." 10 "Cummins Inc (formerly Cummins Engine Co)" 9 "Chrysler Corp." 8 "Caterpillar Inc." 7 "Case Corp." 6 "Berifors Electronics AB" 5 "AMP Inc." 4 "Ametek-Dixson" 3 "Ametek, US Gauge Division" 2 "Allison Transmission, Inc." 1 "Bendix Commercial Vehicle Systems LLC (formerly Allied Signal Inc.)" 0 "Reserved" ;
VAL_ 2633895166 VehicleSystem 127 "Not Available" 0 "NonSpecificSystem" ;
VAL_ 2633895166 VehicleSystem1 0 "NonSpecificSystem" 127 "Not Available" 1 "Tractor" 2 "Trailer" ;
VAL_ 2633895166 VehicleSystem2 0 "NonSpecificSystem" 127 "Not Available" 1 "Tractor" 2 "Tillage" 3 "Secondary Tillage" 4 "Planters/Seeders" 5 "Fertilizers" 6 "Sprayers" 7 "Harvesters" 8 "Root Harvesters" 9 "Forage" 10 "Irrigation" 11 "Transport/Trailer" 12 "Farm Yard Operations" 13 "Powered Auxiliary Device" 14 "Special Crops" 15 "Earth Work" 16 "Skidder" 17 "Sensor Systems" 19 "Timber Harvesters" 20 "Forwarders" 21 "Timber loaders" 22 "Timber Processing Machines" 23 "Mulchers" 24 "Utility Vehicles" 25 "Slurry Applicators" ;
VAL_ 2633895166 VehicleSystem3 0 "NonSpecificSystem" 127 "Not Available" 1 "Skid Steer Loader" 2 "Articulated Dump Truck" 3 "Backhoe" 4 "Crawler" 5 "Excavator" 6 "Forklift" 7 "Four Wheel Drive Loader" 8 "Grader" ;
VAL_ 2633895166 VehicleSystem4 0 "NonSpecificSystem" 127 "Not Available" 10 "System Tools" 20 "Safety Systems" 25 "Inter/Intranetwork Device" 30 "Electrical Distribution" 40 "Steering and Control Surfaces" 50 "Propulsion" 60 "Navigation" 70 "Communications" 80 "Instrumentation/General Systems (deprecate)" 90 "Internal Environment" 100 "Deck, Cargo and Fishing Equipment" 35 "Electrical Generation" 75 "Sensor Communication Interface" 85 "External Environment" 120 "Display" 125 "Entertainment" ;
VAL_ 2633895166 VehicleSystem5 0 "Ind. Process Control Stationary" 127 "Not Available" ;
VAL_ 2365459454 TactorControlModeCmd2 31 "DoNotCare" 18 "UserDefinedControl" 17 "EnableGuidanceControl" 16 "EnableRearDraftForceControl" 15 "EnableFrontDraftForceControl" 14 "EnableRearPTOTorqueControl" 13 "EnableFrontPTOTorqueControl" 12 "EnableEngineEconomyCruiseControl" 11 "EnableMinimumEngineSpeedControl" 10 "EnableConstPTOSpeedCruiseControl" 9 "EnableConstantPTOSpeedControl" 8 "EnableMaximumDraftPowerControl" 7 "EnableAuxiliaryValveSlipControl" 6 "EnableReduceSpeedSlipControl" 5 "EnableRearPTOSlipControl" 4 "EnableFrontPTOSlipControl" 3 "EnableRearHitchSlipControl" 2 "EnableFrontHitchSlipControl" 1 "EnableCruiseControl" 0 "DisableRemoteControl" ;
VAL_ 2365459454 TractorControlModeCmd1 31 "DontCare" 17 "EnableGuidanceControl" 16 "EnableRearDraftForceControl" 15 "EnableFrontDraftForceControl" 14 "EnableRearPTOTorqueControl" 13 "EnableFrontPTOTorqueControl" 12 "EnableEngineEconomyCruiseControl" 11 "EnableMinimumEngineSpeedControl" 10 "EnableConstPTOSpeedCruiseControl" 9 "EnableConstantPTOSpeedControl" 8 "EnableMaximumDraftPowerControl" 7 "EnableAuxiliaryValveSlipControl" 6 "EnableReduceSpeedSlipControl" 5 "EnableRearPTOSlipControl" 4 "EnableFrontPTOSlipControl" 3 "EnableRearHitchSlipControl" 2 "EnableFrontHitchSlipControl" 1 "EnableCruiseControl" 0 "DisableRemoteControl" ;
